VERSION ""

NS_ :

BS_:

BU_: Server VCU Body Brakes

BO_ 2566822142 TCI4: 8 Vector__XXX
 SG_ EngTurbo1TurbineIntakeTemp : 0|16@1+ (0.03125,-273) [-273|1734.97] "deg C" Vector__XXX
 SG_ EngTurbo2TurbineIntakeTemp : 16|16@1+ (0.03125,-273) [-273|1734.97] "deg C" Vector__XXX
 SG_ EngTurbo3TurbineIntakeTemp : 32|16@1+ (0.03125,-273) [-273|1734.97] "deg C" Vector__XXX
 SG_ EngTurbo4TurbineIntakeTemp : 48|16@1+ (0.03125,-273) [-273|1734.97] "deg C" Vector__XXX

BO_ 2566822398 TCI3: 8 Vector__XXX
 SG_ EngTurbo1CompressorIntakePress : 0|16@1+ (0.007812,-250) [-250|251.96] "kPa" Vector__XXX
 SG_ EngTurbo2CompressorIntakePress : 16|16@1+ (0.007812,-250) [-250|251.96] "kPa" Vector__XXX
 SG_ EngTurbo3CompressorIntakePress : 32|16@1+ (0.007812,-250) [-250|251.96] "kPa" Vector__XXX
 SG_ EngTurbo4CompressorIntakePress : 48|16@1+ (0.007812,-250) [-250|251.96] "kPa" Vector__XXX

BO_ 2566822654 TCI2: 8 Vector__XXX
 SG_ EngTurbo1CompressorIntakeTemp : 0|16@1+ (0.03125,-273) [-273|1734.97] "deg C" Vector__XXX
 SG_ EngTurbo2CompressorIntakeTemp : 16|16@1+ (0.03125,-273) [-273|1734.97] "deg C" Vector__XXX
 SG_ EngTurbo3CompressorIntakeTemp : 32|16@1+ (0.03125,-273) [-273|1734.97] "deg C" Vector__XXX
 SG_ EngTurbo4CompressorIntakeTemp : 48|16@1+ (0.03125,-273) [-273|1734.97] "deg C" Vector__XXX

BO_ 2633931774 TCI1: 8 Vector__XXX
 SG_ EngTurboLubeOilPress2 : 0|8@1+ (4,0) [0|1000] "kPa" Vector__XXX
 SG_ EngTurbo2Speed : 8|16@1+ (4,0) [0|257020] "rpm" Vector__XXX
 SG_ EngTurbo3Speed : 24|16@1+ (4,0) [0|257020] "rpm" Vector__XXX
 SG_ EngTurbo4Speed : 40|16@1+ (4,0) [0|257020] "rpm" Vector__XXX

BO_ 2566802430 TCFG2: 8 Vector__XXX
 SG_ TransTorqueLimit : 0|16@1+ (1,0) [0|64255] "Nm" Vector__XXX

BO_ 2566841086 TCFG: 8 Vector__XXX
 SG_ NumberOfReverseGearRatios : 0|8@1+ (1,0) [0|250] "" Vector__XXX
 SG_ NumberOfForwardGearRatios : 8|8@1+ (1,0) [0|250] "" Vector__XXX
 SG_ TransGearRatio : 16|16@1+ (0.001,0) [0|64.255] "" Vector__XXX

BO_ 2348941054 TC1: 8 Vector__XXX
 SG_ TransGearShiftInhibitRq : 0|2@1+ (1,0) [0|3] "" Vector__XXX
 SG_ TrnsTrqeConverterLockupDisableRq : 2|2@1+ (1,0) [0|3] "" Vector__XXX
 SG_ DisengageDrivelineRq : 4|2@1+ (1,0) [0|3] "" Vector__XXX
 SG_ TransReverseGearShiftInhibitRq : 6|2@1+ (1,0) [0|3] "" Vector__XXX
 SG_ RequestedPercentClutchSlip : 8|8@1+ (1,0) [0|100] "%" Vector__XXX
 SG_ TransRequestedGear : 16|8@1+ (1,-125) [-125|125] "" Vector__XXX
 SG_ DisengageDiffLockRqFrontAxle1 : 24|2@1+ (1,0) [0|3] "" Vector__XXX
 SG_ DisengageDiffLockRqFrontAxle2 : 26|2@1+ (1,0) [0|3] "" Vector__XXX
 SG_ DisengageDiffLockRqRearAxle1 : 28|2@1+ (1,0) [0|3] "" Vector__XXX
 SG_ DisengageDiffLockRqRearAxle2 : 30|2@1+ (1,0) [0|3] "" Vector__XXX
 SG_ DisengageDiffLockRqCentral : 32|2@1+ (1,0) [0|3] "" Vector__XXX
 SG_ DisengageDiffLockRqCentralFront : 34|2@1+ (1,0) [0|3] "" Vector__XXX
 SG_ DisengageDiffLockRqCentralRear : 36|2@1+ (1,0) [0|3] "" Vector__XXX
 SG_ TransMode1 : 40|2@1+ (1,0) [0|3] "" Vector__XXX
 SG_ TransMode2 : 42|2@1+ (1,0) [0|3] "" Vector__XXX
 SG_ TransMode3 : 44|2@1+ (1,0) [0|3] "" Vector__XXX
 SG_ TransMode4 : 46|2@1+ (1,0) [0|3] "" Vector__XXX
 SG_ TransRequestedLaunchGear : 50|4@1+ (1,0) [0|15] "" Vector__XXX
 SG_ TrnsShftSlectorDisplayModeSwitch : 54|2@1+ (1,0) [0|3] "" Vector__XXX
 SG_ TransMode5 : 56|2@1+ (1,0) [0|3] "" Vector__XXX
 SG_ TransMode6 : 58|2@1+ (1,0) [0|3] "" Vector__XXX
 SG_ TransMode7 : 60|2@1+ (1,0) [0|3] "" Vector__XXX
 SG_ TransMode8 : 62|2@1+ (1,0) [0|3] "" Vector__XXX

BO_ 2566839806 TC: 8 Vector__XXX
 SG_ EngTurboLubeOilPress1 : 0|8@1+ (4,0) [0|1000] "kPa" Vector__XXX
 SG_ EngTurbo1Speed : 8|16@1+ (4,0) [0|257020] "rpm" Vector__XXX
 SG_ EngTurboOilLevelSwitch : 30|2@1+ (1,0) [0|3] "" Vector__XXX

BO_ 2633911806 TAVG: 8 Vector__XXX
 SG_ EngTotalAverageFuelRate : 0|16@1+ (0.05,0) [0|3212.75] "L/h" Vector__XXX
 SG_ EngTotalAverageFuelEconomy : 16|16@1+ (0.001953,0) [0|125.49] "km/L" Vector__XXX

BO_ 2566775550 SPR: 8 Vector__XXX
 SG_ PneumaticSupplyPressRq : 0|8@1+ (1,0) [0|255] "kPa" Vector__XXX
 SG_ ParkingAnd_orTrailerAirPressRq : 8|8@1+ (1,0) [0|255] "kPa" Vector__XXX
 SG_ ServiceBrakeAirPressRqCircuit1 : 16|8@1+ (1,0) [0|255] "kPa" Vector__XXX
 SG_ ServiceBrakeAirPressRqCircuit2 : 24|8@1+ (1,0) [0|255] "kPa" Vector__XXX
 SG_ AuxEquipmentSupplyPressRq : 32|8@1+ (1,0) [0|255] "kPa" Vector__XXX
 SG_ AirSuspensionSupplyPressRq : 40|8@1+ (1,0) [0|255] "kPa" Vector__XXX

BO_ 2566819838 SP2: 8 Vector__XXX
 SG_ EngExtlShutdownAirSupplyPress : 0|16@1+ (0.5,0) [0|32127.5] "kPa" Vector__XXX

BO_ 2566839038 SOFT: 8 Vector__XXX
 SG_ SoftwareIdentification : 8|8@1+ (1.02,0) [0|255] "per byte" Vector__XXX
 SG_ NmbrOfSftwreIdentificationFields : 0|8@1+ (1,0) [0|250] "steps" Vector__XXX

BO_ 2566841344 SHUTDN: 8 Vector__XXX
 SG_ EngIdleShutdownHasShutdownEng : 0|2@1+ (1,0) [0|3] "" Vector__XXX
 SG_ EngIdleShutdownDriverAlertMode : 2|2@1+ (1,0) [0|3] "" Vector__XXX
 SG_ EngIdleShutdownTimerOverride : 4|2@1+ (1,0) [0|3] "" Vector__XXX
 SG_ EngIdleShutdownTimerState : 6|2@1+ (1,0) [0|3] "" Vector__XXX
 SG_ EngIdleShutdownTimerFunction : 14|2@1+ (1,0) [0|3] "" Vector__XXX
 SG_ A_CHighPressFanSwitch : 16|2@1+ (1,0) [0|3] "" Vector__XXX
 SG_ RefrigerantLowPressSwitch : 18|2@1+ (1,0) [0|3] "" Vector__XXX
 SG_ RefrigerantHighPressSwitch : 20|2@1+ (1,0) [0|3] "" Vector__XXX
 SG_ EngWaitToStartLamp : 24|2@1+ (1,0) [0|3] "" Vector__XXX
 SG_ EngPrtectionSystemHasShutdownEng : 32|2@1+ (1,0) [0|3] "" Vector__XXX
 SG_ EngPrtctnSystmApprachingShutdown : 34|2@1+ (1,0) [0|3] "" Vector__XXX
 SG_ EngProtectionSystemTimerOverride : 36|2@1+ (1,0) [0|3] "" Vector__XXX
 SG_ EngProtectionSystemTimerState : 38|2@1+ (1,0) [0|3] "" Vector__XXX
 SG_ EngProtectionSystemConfig : 46|2@1+ (1,0) [0|3] "" Vector__XXX
 SG_ EngAlarmAcknowledge : 48|2@1+ (1,0) [0|3] "" Vector__XXX
 SG_ EngAlarmOutputCmdStatus : 50|2@1+ (1,0) [0|3] "" Vector__XXX
 SG_ EngAirShutoffCmdStatus : 52|2@1+ (1,0) [0|3] "" Vector__XXX
 SG_ EngOverspeedTest : 54|2@1+ (1,0) [0|3] "" Vector__XXX
 SG_ EngAirShutoffStatus : 56|2@1+ (1,0) [0|3] "" Vector__XXX
 SG_ PTOShutdownHasShutdownEng : 58|2@1+ (1,0) [0|3] "" Vector__XXX
 SG_ CoolantLevEngPrtcShutdnStatus : 60|2@1+ (1,0) [0|3] "bit" Vector__XXX
 SG_ EngOilPressSwitch : 62|2@1+ (1,0) [0|3] "bit" Vector__XXX

BO_ 2633895166 WSMEM: 8 Vector__XXX
 SG_ IdentityNumber : 0|21@1+ (1,0) [0|2097150] "" Vector__XXX
 SG_ ManufacturerCode : 21|11@1+ (1,0) [0|2047] "" Vector__XXX
 SG_ Function : 40|8@1+ (1,0) [0|255] "" Vector__XXX
 SG_ FunctionInstance : 35|5@1+ (1,0) [0|31] "" Vector__XXX
 SG_ ECUInstance : 32|3@1+ (1,0) [0|7] "" Vector__XXX
 SG_ VehicleSystem : 49|7@1+ (1,0) [0|127] "" Vector__XXX
 SG_ VehicleSystemInstance : 56|4@1+ (1,0) [0|15] "" Vector__XXX
 SG_ IndustryGroup : 60|3@1+ (1,0) [0|7] "" Vector__XXX
 SG_ ArbitraryAddressCapable : 63|1@1- (1,0) [0|1] "" Vector__XXX
 SG_ VehicleSystem1 : 49|7@1+ (1,0) [0|127] "" Vector__XXX
 SG_ VehicleSystem2 : 49|7@1+ (1,0) [0|127] "" Vector__XXX
 SG_ VehicleSystem3 : 49|7@1+ (1,0) [0|127] "" Vector__XXX
 SG_ VehicleSystem4 : 49|7@1+ (1,0) [0|127] "" Vector__XXX
 SG_ VehicleSystem5 : 49|7@1+ (1,0) [0|127] "" Vector__XXX

BO_ 2566832382 SERV: 8 Vector__XXX
 SG_ ServiceComponentIdentification : 0|8@1+ (1,0) [0|250] "ID" Vector__XXX
 SG_ ServiceDistance : 8|16@1+ (5,-160635) [-160635|160640] "km" Vector__XXX
 SG_ ServiceComponentIdentification : 24|8@1+ (1,0) [0|250] "ID" Vector__XXX
 SG_ ServiceDelay_CalendarTimeBased : 32|8@1+ (1,-125) [-125|125] "weeks" Vector__XXX
 SG_ ServiceComponentIdentification : 40|8@1+ (1,0) [0|250] "ID" Vector__XXX
 SG_ SrviceDelay_OperationalTimeBased : 48|16@1+ (1,-32127) [-32127|32128] "hr" Vector__XXX

BO_ 2633928446 S2: 8 Vector__XXX
 SG_ ServiceComponentIdentification : 0|8@1+ (1,0) [0|250] "ID" Vector__XXX
 SG_ TimeSinceLastService : 8|16@1+ (1,-32127) [-32127|32128] "hr" Vector__XXX

BO_ 2566804478 RTC1: 8 Vector__XXX
 SG_ LwLmtThrshldFrMaxRPMFromRetarder : 0|8@1+ (1,0) [0|255] "rpm" Vector__XXX
 SG_ HghLmtThrshldFrMnCntnsRPMFrmRtrd : 8|8@1+ (1,0) [0|255] "rpm" Vector__XXX
 SG_ LwLmtThrshldFrMxTrqeFromRetarder : 16|8@1+ (1,-125) [-125|125] "%" Vector__XXX
 SG_ HghLmtThrshldFrMnCntnsTrqFrmRtrd : 24|8@1+ (1,-125) [-125|125] "%" Vector__XXX
 SG_ MaxContinuousRetarderSpeed : 32|8@1+ (1,0) [0|255] "rpm" Vector__XXX
 SG_ MinContinuousRetarderSpeed : 40|8@1+ (1,0) [0|255] "rpm" Vector__XXX
 SG_ MaxContinuousRetarderTorque : 48|8@1+ (1,-125) [-125|125] "%" Vector__XXX
 SG_ MinContinuousRetarderTorque : 56|8@1+ (1,-125) [-125|125] "%" Vector__XXX

BO_ 2566847486 RF: 8 Vector__XXX
 SG_ HydRetarderPress : 0|8@1+ (16,0) [0|4000] "kPa" Vector__XXX
 SG_ HydRetarderOilTemp : 8|8@1+ (1,-40) [-40|210] "deg C" Vector__XXX
 SG_ DrvlineRetarderOverheatIndicator : 16|2@1+ (1,0) [0|3] "" Vector__XXX

BO_ 2631859966 RESET: 8 Vector__XXX
 SG_ TripGroup1 : 0|2@1+ (1,0) [0|3] "" Vector__XXX
 SG_ TripGroup2Proprietary : 2|2@1+ (1,0) [0|3] "" Vector__XXX
 SG_ ServiceComponentIdentification : 8|8@1+ (1,0) [0|250] "ID" Vector__XXX
 SG_ EngBuildHoursReset : 16|2@1+ (1,0) [0|3] "" Vector__XXX
 SG_ SteerStraightAheadPosReset : 18|2@1+ (1,0) [0|3] "" Vector__XXX

BO_ 2633930238 RBI: 8 Vector__XXX
 SG_ EngOperationTimeSinceRebuild : 0|32@1+ (1,0) [0|4211080000] "s" Vector__XXX

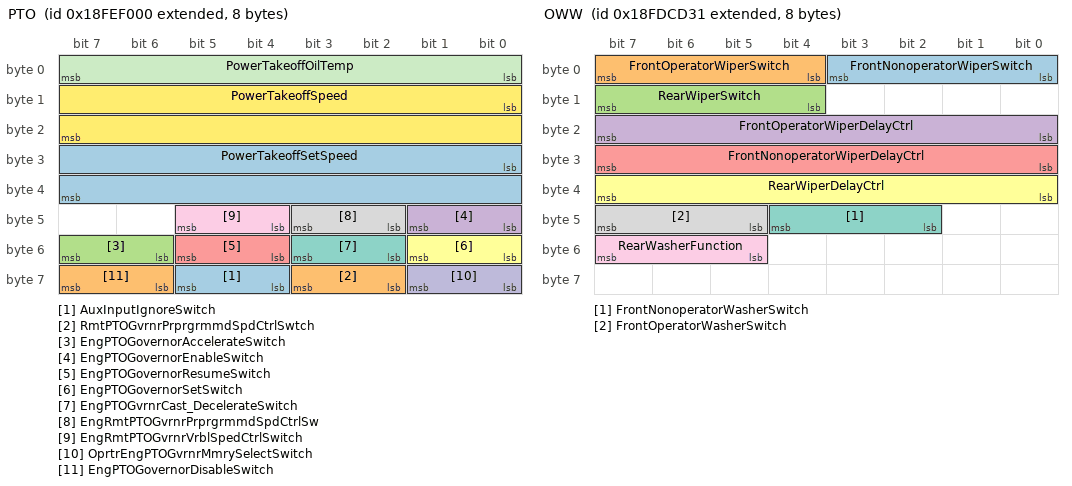
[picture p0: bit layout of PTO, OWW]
BO_ 2566844416 PTO: 8 Vector__XXX
 SG_ AuxInputIgnoreSwitch : 60|2@1+ (1,0) [0|3] "" Vector__XXX
 SG_ RmtPTOGvrnrPrprgrmmdSpdCtrlSwtch : 58|2@1+ (1,0) [0|3] "" Vector__XXX
 SG_ EngPTOGovernorAccelerateSwitch : 54|2@1+ (1,0) [0|3] "" Vector__XXX
 SG_ EngPTOGovernorEnableSwitch : 40|2@1+ (1,0) [0|3] "" Vector__XXX
 SG_ EngPTOGovernorResumeSwitch : 52|2@1+ (1,0) [0|3] "" Vector__XXX
 SG_ EngPTOGovernorSetSwitch : 48|2@1+ (1,0) [0|3] "" Vector__XXX
 SG_ EngPTOGvrnrCast_DecelerateSwitch : 50|2@1+ (1,0) [0|3] "" Vector__XXX
 SG_ EngRmtPTOGvrnrPrprgrmmdSpdCtrlSw : 42|2@1+ (1,0) [0|3] "" Vector__XXX
 SG_ EngRmtPTOGvrnrVrblSpedCtrlSwitch : 44|2@1+ (1,0) [0|3] "" Vector__XXX
 SG_ OprtrEngPTOGvrnrMmrySelectSwitch : 56|2@1+ (1,0) [0|3] "" Vector__XXX
 SG_ PowerTakeoffOilTemp : 0|8@1+ (1,-40) [-40|210] "deg C" Vector__XXX
 SG_ PowerTakeoffSpeed : 8|16@1+ (0.125,0) [0|8031.88] "rpm" Vector__XXX
 SG_ PowerTakeoffSetSpeed : 24|16@1+ (0.125,0) [0|8031.88] "rpm" Vector__XXX
 SG_ EngPTOGovernorDisableSwitch : 62|2@1+ (1,0) [0|3] "" Vector__XXX

BO_ 2566769969 OWW: 8 Vector__XXX
 SG_ FrontNonoperatorWiperSwitch : 0|4@1+ (1,0) [0|15] "" Vector__XXX
 SG_ FrontOperatorWiperSwitch : 4|4@1+ (1,0) [0|15] "" Vector__XXX
 SG_ RearWiperSwitch : 12|4@1+ (1,0) [0|15] "" Vector__XXX
 SG_ FrontOperatorWiperDelayCtrl : 16|8@1+ (0.4,0) [0|100] "%" Vector__XXX
 SG_ FrontNonoperatorWiperDelayCtrl : 24|8@1+ (0.4,0) [0|100] "%" Vector__XXX
 SG_ RearWiperDelayCtrl : 32|8@1+ (0.4,0) [0|100] "%" Vector__XXX
 SG_ FrontNonoperatorWasherSwitch : 42|3@1+ (1,0) [0|7] "" Vector__XXX
 SG_ FrontOperatorWasherSwitch : 45|3@1+ (1,0) [0|7] "" Vector__XXX
 SG_ RearWasherFunction : 53|3@1+ (1,0) [0|7] "" Vector__XXX

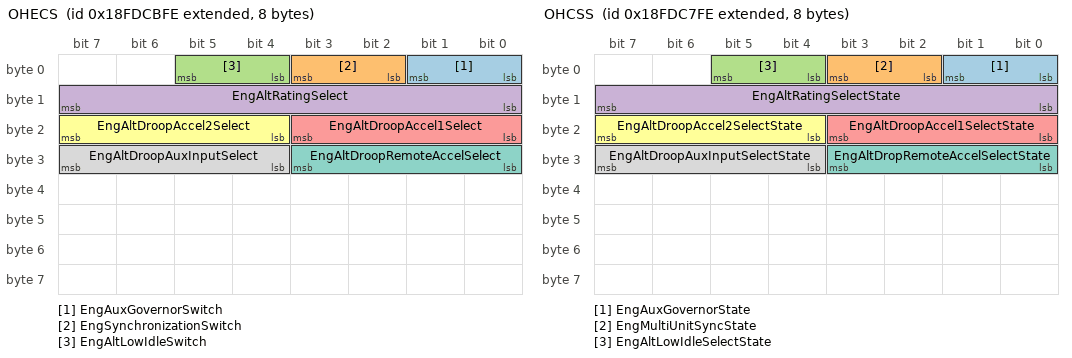
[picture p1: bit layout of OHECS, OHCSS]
BO_ 2566769662 OHECS: 8 Vector__XXX
 SG_ EngAuxGovernorSwitch : 0|2@1+ (1,0) [0|3] "" Vector__XXX
 SG_ EngSynchronizationSwitch : 2|2@1+ (1,0) [0|3] "" Vector__XXX
 SG_ EngAltLowIdleSwitch : 4|2@1+ (1,0) [0|3] "" Vector__XXX
 SG_ EngAltRatingSelect : 8|8@1+ (1.02,0) [0|255] "" Vector__XXX
 SG_ EngAltDroopAccel1Select : 16|4@1+ (1,0) [0|15] "" Vector__XXX
 SG_ EngAltDroopAccel2Select : 20|4@1+ (1,0) [0|15] "" Vector__XXX
 SG_ EngAltDroopRemoteAccelSelect : 24|4@1+ (1,0) [0|15] "" Vector__XXX
 SG_ EngAltDroopAuxInputSelect : 28|4@1+ (1,0) [0|15] "" Vector__XXX

BO_ 2566768638 OHCSS: 8 Vector__XXX
 SG_ EngAuxGovernorState : 0|2@1+ (1,0) [0|3] "" Vector__XXX
 SG_ EngMultiUnitSyncState : 2|2@1+ (1,0) [0|3] "" Vector__XXX
 SG_ EngAltLowIdleSelectState : 4|2@1+ (1,0) [0|3] "" Vector__XXX
 SG_ EngAltRatingSelectState : 8|8@1+ (1,0) [0|255] "" Vector__XXX
 SG_ EngAltDroopAccel1SelectState : 16|4@1+ (1,0) [0|15] "" Vector__XXX
 SG_ EngAltDroopAccel2SelectState : 20|4@1+ (1,0) [0|15] "" Vector__XXX
 SG_ EngAltDropRemoteAccelSelectState : 24|4@1+ (1,0) [0|15] "" Vector__XXX
 SG_ EngAltDroopAuxInputSelectState : 28|4@1+ (1,0) [0|15] "" Vector__XXX

BO_ 2365443326 OEL: 8 Vector__XXX
 SG_ WorkLightSwitch : 0|4@1+ (1,0) [0|15] "" Vector__XXX
 SG_ MainLightSwitch : 4|4@1+ (1,0) [0|15] "" Vector__XXX
 SG_ TurnSignalSwitch : 8|4@1+ (1,0) [0|15] "" Vector__XXX
 SG_ HazardLightSwitch : 12|2@1+ (1,0) [0|3] "" Vector__XXX
 SG_ HighLowBeamSwitch : 14|2@1+ (1,0) [0|3] "" Vector__XXX
 SG_ OperatorsDesiredBacklight : 16|8@1+ (0.4,0) [0|100] "%" Vector__XXX
 SG_ OprtorsDesiredDelayedLampOffTime : 24|16@1+ (1,0) [0|64255] "s" Vector__XXX

BO_ 2566776318 MVS: 8 Vector__XXX
 SG_ MaxVehicleSpeedLimit1 : 0|8@1+ (1,0) [0|250] "km/h" Vector__XXX
 SG_ MaxVehicleSpeedLimit2 : 8|8@1+ (1,0) [0|250] "km/h" Vector__XXX
 SG_ MaxVehicleSpeedLimit3 : 16|8@1+ (1,0) [0|250] "km/h" Vector__XXX
 SG_ MaxVehicleSpeedLimit4 : 24|8@1+ (1,0) [0|250] "km/h" Vector__XXX
 SG_ MaxVehicleSpeedLimit5 : 32|8@1+ (1,0) [0|250] "km/h" Vector__XXX
 SG_ MaxVehicleSpeedLimit6 : 40|8@1+ (1,0) [0|250] "km/h" Vector__XXX
 SG_ MaxVehicleSpeedLimit7 : 48|8@1+ (1,0) [0|250] "km/h" Vector__XXX
 SG_ AppliedVehicleSpeedLimit : 56|8@1+ (1,0) [0|250] "km/h" Vector__XXX

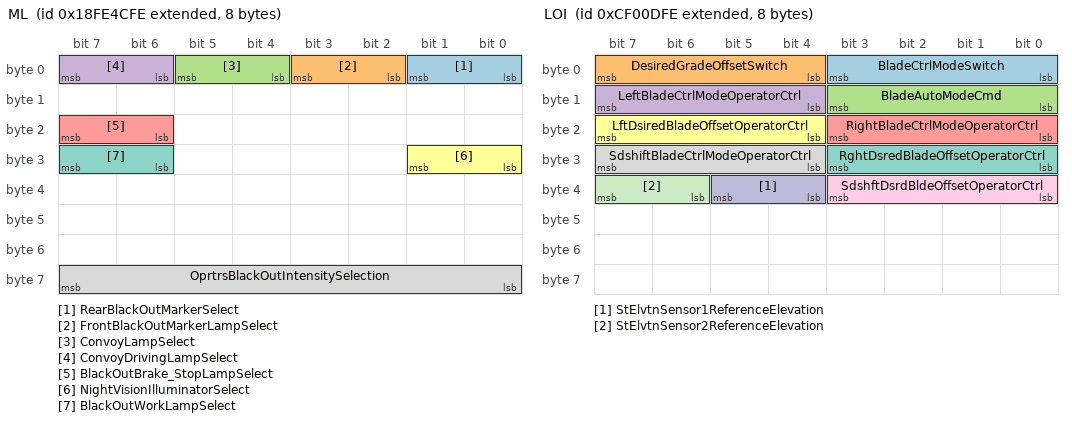
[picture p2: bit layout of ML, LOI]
BO_ 2566802686 ML: 8 Vector__XXX
 SG_ RearBlackOutMarkerSelect : 0|2@1+ (1,0) [0|3] "" Vector__XXX
 SG_ FrontBlackOutMarkerLampSelect : 2|2@1+ (1,0) [0|3] "" Vector__XXX
 SG_ ConvoyLampSelect : 4|2@1+ (1,0) [0|3] "" Vector__XXX
 SG_ ConvoyDrivingLampSelect : 6|2@1+ (1,0) [0|3] "" Vector__XXX
 SG_ BlackOutBrake_StopLampSelect : 22|2@1+ (1,0) [0|3] "" Vector__XXX
 SG_ NightVisionIlluminatorSelect : 24|2@1+ (1,0) [0|3] "" Vector__XXX
 SG_ BlackOutWorkLampSelect : 30|2@1+ (1,0) [0|3] "" Vector__XXX
 SG_ OprtrsBlackOutIntensitySelection : 56|8@1+ (1,0) [0|100] "%" Vector__XXX

BO_ 2566774014 MCI: 8 Vector__XXX
 SG_ EngThrttlSynchrnzationModeStatus : 0|4@1+ (1,0) [0|15] "" Vector__XXX
 SG_ TrollingModeStatus : 4|2@1+ (1,0) [0|3] "" Vector__XXX
 SG_ SlowVesselModeStatus : 6|2@1+ (1,0) [0|3] "" Vector__XXX

BO_ 2566823166 MBT3: 8 Vector__XXX
 SG_ EngMainBearing9Temp : 0|16@1+ (0.03125,-273) [-273|1734.97] "deg C" Vector__XXX
 SG_ EngMainBearing10Temp : 16|16@1+ (0.03125,-273) [-273|1734.97] "deg C" Vector__XXX
 SG_ EngMainBearing11Temp : 32|16@1+ (0.03125,-273) [-273|1734.97] "deg C" Vector__XXX

BO_ 2566823422 MBT2: 8 Vector__XXX
 SG_ EngMainBearing5Temp : 0|16@1+ (0.03125,-273) [-273|1734.97] "deg C" Vector__XXX
 SG_ EngMainBearing6Temp : 16|16@1+ (0.03125,-273) [-273|1734.97] "deg C" Vector__XXX
 SG_ EngMainBearing7Temp : 32|16@1+ (0.03125,-273) [-273|1734.97] "deg C" Vector__XXX
 SG_ EngMainBearing8Temp : 48|16@1+ (0.03125,-273) [-273|1734.97] "deg C" Vector__XXX

BO_ 2566823678 MBT1: 8 Vector__XXX
 SG_ EngMainBearing1Temp : 0|16@1+ (0.03125,-273) [-273|1734.97] "deg C" Vector__XXX
 SG_ EngMainBearing2Temp : 16|16@1+ (0.03125,-273) [-273|1734.97] "deg C" Vector__XXX
 SG_ EngMainBearing3Temp : 32|16@1+ (0.03125,-273) [-273|1734.97] "deg C" Vector__XXX
 SG_ EngMainBearing4Temp : 48|16@1+ (0.03125,-273) [-273|1734.97] "deg C" Vector__XXX

BO_ 2432595710 LVDD: 8 Vector__XXX
 SG_ LEDDisplayData1 : 0|8@1+ (1,0) [0|255] "" Vector__XXX
 SG_ LEDDisplayModeCtrl : 8|4@1+ (1,0) [0|15] "" Vector__XXX
 SG_ LEDDisplayDeadbandCtrl : 12|4@1+ (1,0) [0|15] "" Vector__XXX
 SG_ LEDPatternCtrl : 16|4@1+ (1,0) [0|15] "" Vector__XXX
 SG_ DisplayDeadbands : 20|4@1+ (1,0) [0|15] "" Vector__XXX

BO_ 2365486590 LVD: 8 Vector__XXX
 SG_ AbsLaserStrikePos : 40|16@1+ (0.1,0) [0|6425.5] "mm" Vector__XXX
 SG_ LaserStrikeVerticalDeviation : 0|16@1+ (0.1,-3200) [-3200|3225.5] "mm" Vector__XXX
 SG_ LaserReceiverType : 16|8@1+ (1,0) [0|250] "" Vector__XXX
 SG_ LaserStrikeDataLatency : 24|16@1+ (5.1E-005,0) [0|3.277] "s" Vector__XXX

BO_ 2365485566 LTP: 8 Vector__XXX
 SG_ LaserTracerTargetDeviation : 0|16@1+ (0.1,-3200) [-3200|3225.5] "mm" Vector__XXX
 SG_ LaserTracerVerticalDistance : 16|16@1+ (0.1,0) [0|6425.5] "mm" Vector__XXX
 SG_ LaserTracerHorizontalDeviation : 32|8@1+ (1,0) [0|250] "%" Vector__XXX
 SG_ LEDDisplayData2 : 40|8@1+ (1,0) [0|255] "" Vector__XXX
 SG_ LaserTracerInformation : 48|8@1+ (1,0) [0|255] "" Vector__XXX

BO_ 2365486334 LSP: 8 Vector__XXX
 SG_ ModifyLevelingSystemSetPoint : 0|16@1+ (0.1,-3200) [-3200|3225.5] "mm" Vector__XXX
 SG_ BldeHeightSetPointHighResolution : 16|32@1+ (1,-209.715) [-209.715|4294970000] "m" Vector__XXX

BO_ 2364542462 LOI: 8 Vector__XXX
 SG_ BladeCtrlModeSwitch : 0|4@1+ (1,0) [0|15] "" Vector__XXX
 SG_ DesiredGradeOffsetSwitch : 4|4@1+ (1,0) [0|15] "" Vector__XXX
 SG_ BladeAutoModeCmd : 8|4@1+ (1,0) [0|15] "" Vector__XXX
 SG_ LeftBladeCtrlModeOperatorCtrl : 12|4@1+ (1,0) [0|15] "" Vector__XXX
 SG_ RightBladeCtrlModeOperatorCtrl : 16|4@1+ (1,0) [0|15] "" Vector__XXX
 SG_ LftDsiredBladeOffsetOperatorCtrl : 20|4@1+ (1,0) [0|15] "" Vector__XXX
 SG_ RghtDsredBladeOffsetOperatorCtrl : 24|4@1+ (1,0) [0|15] "" Vector__XXX
 SG_ SdshiftBladeCtrlModeOperatorCtrl : 28|4@1+ (1,0) [0|15] "" Vector__XXX
 SG_ SdshftDsrdBldeOffsetOperatorCtrl : 32|4@1+ (1,0) [0|15] "" Vector__XXX
 SG_ StElvtnSensor1ReferenceElevation : 36|2@1+ (1,0) [0|3] "" Vector__XXX
 SG_ StElvtnSensor2ReferenceElevation : 38|2@1+ (1,0) [0|3] "" Vector__XXX

BO_ 2365486078 LMP: 8 Vector__XXX
 SG_ MastPos : 0|16@1+ (0.1,-3200) [-3200|3225.5] "mm" Vector__XXX

BO_ 2633937918 LFI: 8 Vector__XXX
 SG_ TotalEngPTOGovernorFuelUsed : 0|32@1+ (0.5,0) [0|2105540000] "kg" Vector__XXX
 SG_ TripAverageFuelRate : 32|16@1+ (0.05,0) [0|3212.75] "kg/h" Vector__XXX
 SG_ FlexibleFuelPercentage : 48|10@1+ (1,0) [0|102] "%" Vector__XXX

BO_ 2566844928 LFE: 8 Vector__XXX
 SG_ EngThrottleValve1Pos : 48|8@1+ (0.4,0) [0|100] "%" Vector__XXX
 SG_ EngThrottleValve2Pos : 56|8@1+ (0.4,0) [0|100] "%" Vector__XXX
 SG_ EngFuelRate : 0|16@1+ (0.05,0) [0|3212.75] "L/h" Vector__XXX
 SG_ EngInstantaneousFuelEconomy : 16|16@1+ (0.001953,0) [0|125.49] "km/L" Vector__XXX
 SG_ EngAverageFuelEconomy : 32|16@1+ (0.001953,0) [0|125.49] "km/L"  VCU

BO_ 2566842878 LFC: 8 Vector__XXX
 SG_ EngTripFuel : 0|32@1+ (0.5,0) [0|2105540000] "L" Vector__XXX
 SG_ EngTotalFuelUsed : 32|32@1+ (0.5,0) [0|2105540000] "L" Vector__XXX

BO_ 2633883646 FWD: 8 Vector__XXX
 SG_ FrontWheelDriveActuatorStatus : 0|2@1+ (1,0) [0|3] "" Vector__XXX

BO_ 2633880062 FMS: 8 Vector__XXX
 SG_ FMSstandardDiagnosticsSupported : 0|2@1+ (1,0) [0|3] "" Vector__XXX
 SG_ FMSstandardRequestsSupported : 2|2@1+ (1,0) [0|3] "" Vector__XXX
 SG_ FMSstandardSWversionSupported : 8|32@1+ (1,0) [0|4294970000] "per byte" Vector__XXX

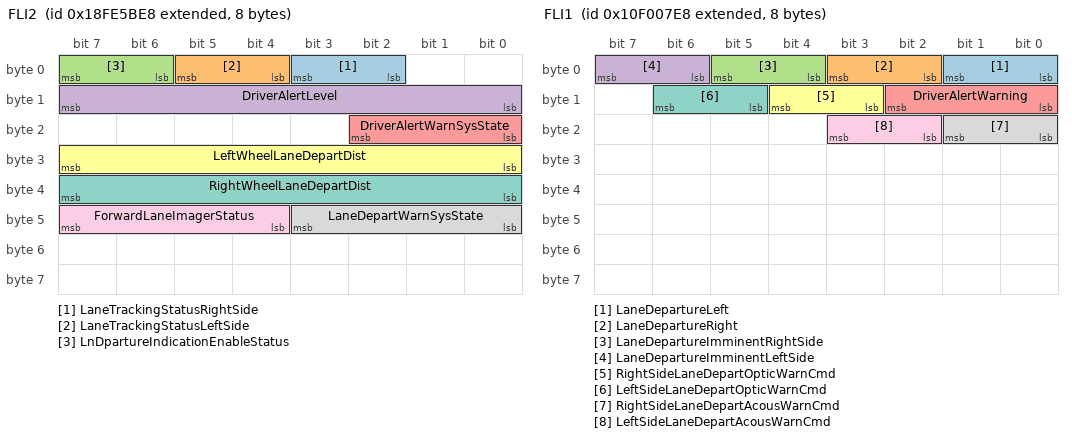
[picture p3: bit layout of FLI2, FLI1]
BO_ 2566806504 FLI2: 8 Vector__XXX
 SG_ LaneTrackingStatusRightSide : 2|2@1+ (1,0) [0|3] "" Vector__XXX
 SG_ LaneTrackingStatusLeftSide : 4|2@1+ (1,0) [0|3] "" Vector__XXX
 SG_ LnDpartureIndicationEnableStatus : 6|2@1+ (1,0) [0|3] "" Vector__XXX
 SG_ DriverAlertLevel : 8|8@1+ (0.4,0) [0|40] "%" Vector__XXX
 SG_ DriverAlertWarnSysState : 16|3@1+ (1,0) [0|7] "bit" Vector__XXX
 SG_ LeftWheelLaneDepartDist : 24|8@1+ (1,-125) [-125|125] "cm" Vector__XXX
 SG_ RightWheelLaneDepartDist : 32|8@1+ (1,-125) [-125|125] "cm" Vector__XXX
 SG_ LaneDepartWarnSysState : 40|4@1+ (1,0) [0|15] "bit" Vector__XXX
 SG_ ForwardLaneImagerStatus : 44|4@1+ (1,0) [0|15] "bit" Vector__XXX

BO_ 2431649768 FLI1: 8 Vector__XXX
 SG_ LaneDepartureLeft : 0|2@1+ (1,0) [0|3] "" Vector__XXX
 SG_ LaneDepartureRight : 2|2@1+ (1,0) [0|3] "" Vector__XXX
 SG_ LaneDepartureImminentRightSide : 4|2@1+ (1,0) [0|3] "" Vector__XXX
 SG_ LaneDepartureImminentLeftSide : 6|2@1+ (1,0) [0|3] "" Vector__XXX
 SG_ DriverAlertWarning : 8|3@1+ (1,0) [0|7] "" Vector__XXX
 SG_ RightSideLaneDepartOpticWarnCmd : 11|2@1+ (1,0) [0|3] "" Vector__XXX
 SG_ LeftSideLaneDepartOpticWarnCmd : 13|2@1+ (1,0) [0|3] "" Vector__XXX
 SG_ RightSideLaneDepartAcousWarnCmd : 16|2@1+ (1,0) [0|3] "" Vector__XXX
 SG_ LeftSideLaneDepartAcousWarnCmd : 18|2@1+ (1,0) [0|3] "" Vector__XXX

BO_ 2633929214 FL: 8 Vector__XXX
 SG_ EngFuelLeakage1 : 0|2@1+ (1,0) [0|3] "" Vector__XXX
 SG_ EngFuelLeakage2 : 2|2@1+ (1,0) [0|3] "" Vector__XXX

BO_ 2566831360 FD1: 8 Vector__XXX
 SG_ EstPercentFanSpeed : 0|8@1+ (1,0) [0|100] "%" Vector__XXX
 SG_ FanDriveState : 8|4@1+ (1,0) [0|15] "" Vector__XXX
 SG_ FanSpeed : 16|16@1+ (0.125,0) [0|8031.88] "rpm" Vector__XXX
 SG_ HydFanMotorPress : 32|16@1+ (0.5,0) [0|32127.5] "kPa" Vector__XXX
 SG_ FanDriveBypassCmdStatus : 48|8@1+ (1,0) [0|100] "%" Vector__XXX

BO_ 2566820094 ETH: 8 Vector__XXX
 SG_ NumberOfEngTorqueHistoryRecords : 0|8@1+ (1,0) [0|250] "records" Vector__XXX
 SG_ EngPower : 8|16@1+ (0.5,0) [0|32127.5] "kW" Vector__XXX
 SG_ EngPeakTorque1 : 24|16@1+ (1,0) [0|64255] "Nm" Vector__XXX
 SG_ EngPeakTorque2 : 40|16@1+ (1,0) [0|64255] "Nm" Vector__XXX
 SG_ CalibRecordStartMonth : 56|8@1+ (1,0) [0|250] "months" Vector__XXX
 SG_ CalibRecordStartDay : 64|8@1+ (0.25,0) [0|62.5] "days" Vector__XXX
 SG_ CalibRecordStartYear : 72|8@1+ (1,1985) [1985|2235] "years" Vector__XXX
 SG_ CalibRecordDurationTime : 80|32@1+ (0.05,0) [0|210554000] "hr" Vector__XXX
 SG_ TorqueLimitingFeatureStatus : 112|2@1+ (1,0) [0|3] "" Vector__XXX
 SG_ EngTorqueLimitFeature : 114|3@1+ (1,0) [0|7] "" Vector__XXX
 SG_ TransGearRatio1 : 120|16@1+ (0.01,0) [0|642.55] "" Vector__XXX
 SG_ EngTorqueLimit1Trans : 136|16@1+ (1,0) [0|64255] "Nm" Vector__XXX
 SG_ TransGearRatio2 : 152|16@1+ (0.01,0) [0|642.55] "" Vector__XXX
 SG_ EngTorqueLimit2Trans : 168|16@1+ (1,0) [0|64255] "Nm" Vector__XXX
 SG_ TransGearRatio3 : 184|16@1+ (0.01,0) [0|642.55] "" Vector__XXX
 SG_ EngTorqueLimit3Trans : 200|16@1+ (1,0) [0|64255] "Nm" Vector__XXX
 SG_ EngTorqueLimit4Trans : 216|16@1+ (1,0) [0|64255] "Nm" Vector__XXX
 SG_ EngTorqueLimit5Switch : 232|16@1+ (1,0) [0|64255] "Nm" Vector__XXX
 SG_ EngTorqueLimit6AxleInput : 248|16@1+ (2,0) [0|128510] "Nm" Vector__XXX

BO_ 2364541955 ETC8: 8 Vector__XXX
 SG_ TransTorqueConverterRatio : 0|16@1+ (0.001,0) [0|64.255] "" Vector__XXX
 SG_ TransClutch_ConverterInputSpeed : 16|16@1+ (0.125,0) [0|8031.88] "rpm" Vector__XXX

BO_ 2566801923 ETC7: 8 Vector__XXX
 SG_ TransServiceIndicator : 2|2@1+ (1,0) [0|3] "" Vector__XXX
 SG_ TrnsRqstedRangeDisplayBlankState : 4|2@1+ (1,0) [0|3] "" Vector__XXX
 SG_ TrnsRqstedRangeDisplayFlashState : 6|2@1+ (1,0) [0|3] "" Vector__XXX
 SG_ TransReadyForBrakeRelease : 8|2@1+ (1,0) [0|3] "" Vector__XXX
 SG_ ActiveShiftConsoleIndicator : 10|2@1+ (1,0) [0|3] "" Vector__XXX
 SG_ TransEngCrankEnable : 12|2@1+ (1,0) [0|3] "" Vector__XXX
 SG_ TransShiftInhibitIndicator : 14|2@1+ (1,0) [0|3] "" Vector__XXX
 SG_ TransMode4Indicator : 16|2@1+ (1,0) [0|3] "" Vector__XXX
 SG_ TransMode3Indicator : 18|2@1+ (1,0) [0|3] "" Vector__XXX
 SG_ TransMode2Indicator : 20|2@1+ (1,0) [0|3] "" Vector__XXX
 SG_ TransMode1Indicator : 22|2@1+ (1,0) [0|3] "" Vector__XXX
 SG_ TransRequestedGearFeedback : 24|8@1+ (1,-125) [-125|125] "" Vector__XXX
 SG_ TransMode5Indicator : 32|2@1+ (1,0) [0|3] "" Vector__XXX
 SG_ TransMode6Indicator : 34|2@1+ (1,0) [0|3] "" Vector__XXX
 SG_ TransMode7Indicator : 36|2@1+ (1,0) [0|3] "" Vector__XXX
 SG_ TransMode8Indicator : 38|2@1+ (1,0) [0|3] "" Vector__XXX
 SG_ TransWarningIndicator : 42|2@1+ (1,0) [0|3] "" Vector__XXX
 SG_ TrnsCrrentRangeDisplayBlankState : 0|2@1+ (1,0) [0|3] "" Vector__XXX
 SG_ TrnsRverseGearShiftInhibitStatus : 40|2@1+ (1,0) [0|3] "" Vector__XXX
 SG_ TransMode9Indicator : 44|2@1+ (1,0) [0|3] "" Vector__XXX
 SG_ TransMode10Indicator : 46|2@1+ (1,0) [0|3] "" Vector__XXX
 SG_ TransAirSupplyPressureIndicator : 48|3@1+ (1,0) [0|7] "" Vector__XXX
 SG_ TransManualReturnState : 51|3@1+ (1,0) [0|7] "" Vector__XXX
 SG_ TransManualModeIndicator : 54|2@1+ (1,0) [0|3] "" Vector__XXX

BO_ 2633935870 ETC6: 8 Vector__XXX
 SG_ RecommendedGear : 0|8@1+ (1,-125) [-125|125] "" Vector__XXX
 SG_ HighestPossibleGear : 8|8@1+ (1,-125) [-125|125] "" Vector__XXX
 SG_ LowestPossibleGear : 16|8@1+ (1,-125) [-125|125] "" Vector__XXX
 SG_ ClutchLifeRemaining : 24|8@1+ (0.4,0) [0|100] "%" Vector__XXX

BO_ 2633942014 ETC5: 8 Vector__XXX
 SG_ TransHighRangeSenseSwitch : 0|2@1+ (1,0) [0|3] "" Vector__XXX
 SG_ TransLowRangeSenseSwitch : 2|2@1+ (1,0) [0|3] "" Vector__XXX
 SG_ TransReverseDirectionSwitch : 8|2@1+ (1,0) [0|3] "" Vector__XXX
 SG_ TransNeutralSwitch : 10|2@1+ (1,0) [0|3] "" Vector__XXX
 SG_ TransForwardDirectionSwitch : 12|2@1+ (1,0) [0|3] "" Vector__XXX

BO_ 2633942526 ETC4: 8 Vector__XXX
 SG_ TransSynchronizerClutchValue : 0|8@1+ (0.4,0) [0|100] "%" Vector__XXX
 SG_ TransSynchronizerBrakeValue : 8|8@1+ (0.4,0) [0|100] "%" Vector__XXX

BO_ 2633943038 ETC3: 8 Vector__XXX
 SG_ TransShiftFingerGearPos : 0|8@1+ (0.4,0) [0|100] "%" Vector__XXX
 SG_ TransShiftFingerRailPos : 8|8@1+ (0.4,0) [0|100] "%" Vector__XXX
 SG_ TransShiftFingerNeutralIndicator : 16|2@1+ (1,0) [0|3] "" Vector__XXX
 SG_ TrnsShftFngerEngagementIndicator : 18|2@1+ (1,0) [0|3] "" Vector__XXX
 SG_ TrnsShftFngerCenterRailIndicator : 20|2@1+ (1,0) [0|3] "" Vector__XXX
 SG_ TransShiftFingerRailActuator1 : 24|2@1+ (1,0) [0|3] "" Vector__XXX
 SG_ TransShiftFingerGearActuator1 : 26|2@1+ (1,0) [0|3] "" Vector__XXX
 SG_ TransShiftFingerRailActuator2 : 28|2@1+ (1,0) [0|3] "" Vector__XXX
 SG_ TransShiftFingerGearActuator2 : 30|2@1+ (1,0) [0|3] "" Vector__XXX
 SG_ TransRangeHighActuator : 32|2@1+ (1,0) [0|3] "" Vector__XXX
 SG_ TransRangeLowActuator : 34|2@1+ (1,0) [0|3] "" Vector__XXX
 SG_ TransSplitterDirectActuator : 36|2@1+ (1,0) [0|3] "" Vector__XXX
 SG_ TransSplitterIndirectActuator : 38|2@1+ (1,0) [0|3] "" Vector__XXX
 SG_ TransClutchActuator : 40|2@1+ (1,0) [0|3] "" Vector__XXX
 SG_ TransLockupClutchActuator : 42|2@1+ (1,0) [0|3] "" Vector__XXX
 SG_ TransDefuelActuator : 44|2@1+ (1,0) [0|3] "" Vector__XXX
 SG_ TransInertiaBrakeActuator : 46|2@1+ (1,0) [0|3] "" Vector__XXX

BO_ 2565866755 ETC2: 8 Vector__XXX
 SG_ TransCurrentGear : 24|8@1+ (1,-125) [-125|125] "" Vector__XXX
 SG_ TransSelectedGear : 0|8@1+ (1,-125) [-125|125] "" Vector__XXX
 SG_ TransActualGearRatio : 8|16@1+ (0.001,0) [0|64.255] "" Vector__XXX
 SG_ TransRequestedRange : 32|16@1+ (1,0) [0|255] "per byte" Vector__XXX
 SG_ TransCurrentRange : 48|16@1+ (1,0) [0|255] "per byte"  VCU

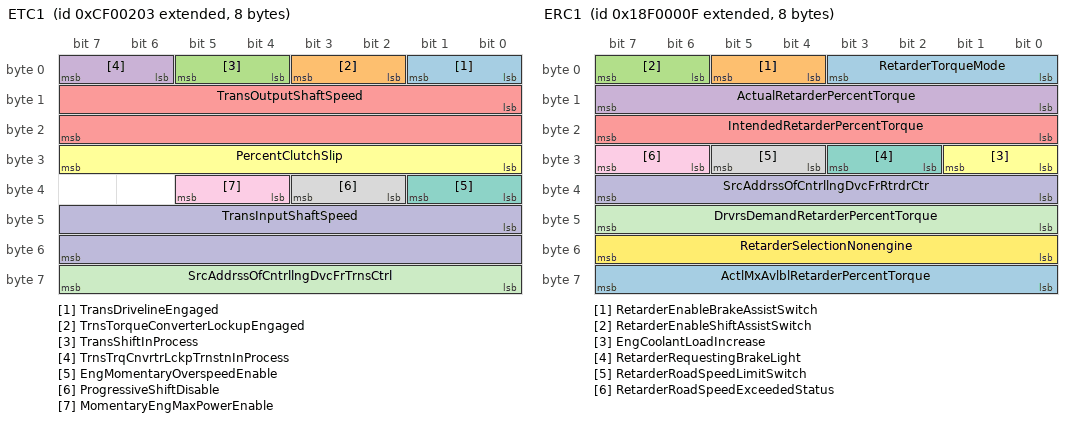
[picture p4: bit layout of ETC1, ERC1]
BO_ 2364539395 ETC1: 8 Vector__XXX
 SG_ TransDrivelineEngaged : 0|2@1+ (1,0) [0|3] "" Vector__XXX
 SG_ TrnsTorqueConverterLockupEngaged : 2|2@1+ (1,0) [0|3] "" Vector__XXX
 SG_ TransShiftInProcess : 4|2@1+ (1,0) [0|3] "" Vector__XXX
 SG_ TrnsTrqCnvrtrLckpTrnstnInProcess : 6|2@1+ (1,0) [0|3] "" Vector__XXX
 SG_ TransOutputShaftSpeed : 8|16@1+ (0.125,0) [0|8031.88] "rpm" Vector__XXX
 SG_ PercentClutchSlip : 24|8@1+ (0.4,0) [0|100] "%" Vector__XXX
 SG_ EngMomentaryOverspeedEnable : 32|2@1+ (1,0) [0|3] "" Vector__XXX
 SG_ ProgressiveShiftDisable : 34|2@1+ (1,0) [0|3] "" Vector__XXX
 SG_ MomentaryEngMaxPowerEnable : 36|2@1+ (1,0) [0|3] "" Vector__XXX
 SG_ TransInputShaftSpeed : 40|16@1+ (0.125,0) [0|8031.88] "rpm" Vector__XXX
 SG_ SrcAddrssOfCntrllngDvcFrTrnsCtrl : 56|8@1+ (1,0) [0|255] ""  VCU

BO_ 2566810110 ET3: 8 Vector__XXX
 SG_ EngCoolantTemp : 16|16@1+ (0.03125,-273) [-273|1734.97] "deg C" Vector__XXX
 SG_ EngIntakeManifold1AirTemp : 0|16@1+ (0.03125,-273) [-273|1734.97] "deg C" Vector__XXX
 SG_ EngIntkVlvActuationSystemOilTemp : 32|16@1+ (0.03125,-273) [-273|1734.97] "deg C" Vector__XXX
 SG_ EngChargeAirCooler1OutletTemp : 48|16@1+ (0.03125,-273) [-273|1734.97] "deg C" Vector__XXX

BO_ 2566825214 ET2: 8 Vector__XXX
 SG_ EngOilTemp2 : 0|16@1+ (0.03125,-273) [-273|1734.97] "deg C" Vector__XXX
 SG_ EngECUTemp : 16|16@1+ (0.03125,-273) [-273|1734.97] "deg C" Vector__XXX
 SG_ EngExhaustGasRecirculation1Temp : 48|16@1+ (0.03125,-273) [-273|1734.97] "deg C" Vector__XXX
 SG_ EngExhstGsRcirculation1DiffPress : 32|16@1+ (0.007812,-250) [-250|251.96] "kPa" Vector__XXX

BO_ 2566843904 ET1: 8 Vector__XXX
 SG_ EngCoolantTemp : 0|8@1+ (1,-40) [-40|210] "deg C" Vector__XXX
 SG_ EngOilTemp1 : 16|16@1+ (0.03125,-273) [-273|1734.97] "deg C" Vector__XXX
 SG_ EngTurboOilTemp : 32|16@1+ (0.03125,-273) [-273|1734.97] "deg C" Vector__XXX
 SG_ EngIntercoolerTemp : 48|8@1+ (1,-40) [-40|210] "deg C" Vector__XXX
 SG_ EngIntercoolerThermostatOpening : 56|8@1+ (0.4,0) [0|100] "%" Vector__XXX
 SG_ EngFuel1Temp1 : 8|8@1+ (1,-40) [-40|210] "deg C"  VCU

BO_ 2566785022 ET: 8 Vector__XXX
 SG_ EngExhaustGasTempRightManifold : 0|16@1+ (0.03125,-273) [-273|1734.97] "deg C" Vector__XXX
 SG_ EngExhaustGasTempLeftManifold : 16|16@1+ (0.03125,-273) [-273|1734.97] "deg C" Vector__XXX

BO_ 2565868542 ESC1: 8 Vector__XXX
 SG_ ActualInnerWheelSteerAngle : 0|16@1+ (0.003891,-125) [-125|125.016] "deg" Vector__XXX
 SG_ AxleLocation : 16|8@1+ (1.02,0) [0|255] "" Vector__XXX
 SG_ StatusOfSteerAxle : 24|4@1+ (1,0) [0|15] "" Vector__XXX
 SG_ SteerableLiftAxleLoweringInhibit : 28|2@1+ (1,0) [0|3] "" Vector__XXX
 SG_ SteerType : 32|4@1+ (1,0) [0|15] "" Vector__XXX
 SG_ TypeOfSteerForces : 36|4@1+ (1,0) [0|15] "" Vector__XXX
 SG_ TypeOfSteerTrans : 40|4@1+ (1,0) [0|15] "" Vector__XXX

BO_ 2633941519 ERC2: 8 Vector__XXX
 SG_ TransOutputRetarder : 0|2@1+ (1,0) [0|3] "" Vector__XXX
 SG_ CruiseCtrlRetdActSpeedOffset : 2|16@1- (1,-125) [-417|168] "km/h" Vector__XXX

BO_ 2565865487 ERC1: 8 Vector__XXX
 SG_ RetarderTorqueMode : 0|4@1+ (1,0) [0|15] "" Vector__XXX
 SG_ RetarderEnableBrakeAssistSwitch : 4|2@1+ (1,0) [0|3] "" Vector__XXX
 SG_ RetarderEnableShiftAssistSwitch : 6|2@1+ (1,0) [0|3] "" Vector__XXX
 SG_ ActualRetarderPercentTorque : 8|8@1+ (1,-125) [-125|125] "%" Vector__XXX
 SG_ IntendedRetarderPercentTorque : 16|8@1+ (1,-125) [-125|125] "%" Vector__XXX
 SG_ EngCoolantLoadIncrease : 24|2@1+ (1,0) [0|3] "" Vector__XXX
 SG_ RetarderRequestingBrakeLight : 26|2@1+ (1,0) [0|3] "" Vector__XXX
 SG_ RetarderRoadSpeedLimitSwitch : 28|2@1+ (1,0) [0|3] "" Vector__XXX
 SG_ RetarderRoadSpeedExceededStatus : 30|2@1+ (1,0) [0|3] "" Vector__XXX
 SG_ SrcAddrssOfCntrllngDvcFrRtrdrCtr : 32|8@1+ (1,0) [0|255] "" Vector__XXX
 SG_ DrvrsDemandRetarderPercentTorque : 40|8@1+ (1,-125) [-125|125] "%" Vector__XXX
 SG_ RetarderSelectionNonengine : 48|8@1+ (0.4,0) [0|100] "%" Vector__XXX
 SG_ ActlMxAvlblRetarderPercentTorque : 56|8@1+ (1,-125) [-125|125] "%"  VCU

BO_ 2633932798 EPT5: 8 Vector__XXX
 SG_ EngExhaustGasPort17Temp : 0|16@1+ (0.03125,-273) [-273|1734.97] "deg C" Vector__XXX
 SG_ EngExhaustGasPort18Temp : 16|16@1+ (0.03125,-273) [-273|1734.97] "deg C" Vector__XXX
 SG_ EngExhaustGasPort19Temp : 32|16@1+ (0.03125,-273) [-273|1734.97] "deg C" Vector__XXX
 SG_ EngExhaustGasPort20Temp : 48|16@1+ (0.03125,-273) [-273|1734.97] "deg C" Vector__XXX

BO_ 2566824190 EPT4: 8 Vector__XXX
 SG_ EngExhaustGasPort13Temp : 0|16@1+ (0.03125,-273) [-273|1734.97] "deg C" Vector__XXX
 SG_ EngExhaustGasPort14Temp : 16|16@1+ (0.03125,-273) [-273|1734.97] "deg C" Vector__XXX
 SG_ EngExhaustGasPort15Temp : 32|16@1+ (0.03125,-273) [-273|1734.97] "deg C" Vector__XXX
 SG_ EngExhaustGasPort16Temp : 48|16@1+ (0.03125,-273) [-273|1734.97] "deg C" Vector__XXX

BO_ 2633933310 EPT3: 8 Vector__XXX
 SG_ EngExhaustGasPort9Temp : 0|16@1+ (0.03125,-273) [-273|1734.97] "deg C" Vector__XXX
 SG_ EngExhaustGasPort10Temp : 16|16@1+ (0.03125,-273) [-273|1734.97] "deg C" Vector__XXX
 SG_ EngExhaustGasPort11Temp : 32|16@1+ (0.03125,-273) [-273|1734.97] "deg C" Vector__XXX
 SG_ EngExhaustGasPort12Temp : 48|16@1+ (0.03125,-273) [-273|1734.97] "deg C" Vector__XXX

BO_ 2633933566 EPT2: 8 Vector__XXX
 SG_ EngExhaustGasPort5Temp : 0|16@1+ (0.03125,-273) [-273|1734.97] "deg C" Vector__XXX
 SG_ EngExhaustGasPort6Temp : 16|16@1+ (0.03125,-273) [-273|1734.97] "deg C" Vector__XXX
 SG_ EngExhaustGasPort7Temp : 32|16@1+ (0.03125,-273) [-273|1734.97] "deg C" Vector__XXX
 SG_ EngExhaustGasPort8Temp : 48|16@1+ (0.03125,-273) [-273|1734.97] "deg C" Vector__XXX

BO_ 2633933822 EPT1: 8 Vector__XXX
 SG_ EngExhaustGasPort1Temp : 0|16@1+ (0.03125,-273) [-273|1734.97] "deg C" Vector__XXX
 SG_ EngExhaustGasPort2Temp : 16|16@1+ (0.03125,-273) [-273|1734.97] "deg C" Vector__XXX
 SG_ EngExhaustGasPort3Temp : 32|16@1+ (0.03125,-273) [-273|1734.97] "deg C" Vector__XXX
 SG_ EngExhaustGasPort4Temp : 48|16@1+ (0.03125,-273) [-273|1734.97] "deg C" Vector__XXX

BO_ 2566776062 EPD: 8 Vector__XXX
 SG_ PayloadPercentage : 0|8@1+ (1,0) [0|250] "%" Vector__XXX

BO_ 2566771454 EP: 8 Vector__XXX
 SG_ KeepAliveBatteryConsumption : 0|16@1+ (1,0) [0|64255] "mAhr" Vector__XXX
 SG_ DataMemoryUsage : 16|8@1+ (0.4,0) [0|100] "%" Vector__XXX

BO_ 2566775806 EOAC: 8 Vector__XXX
 SG_ TravelVelocityCtrlPos : 0|8@1+ (1,-125) [-125|125] "%" Vector__XXX

BO_ 2633935358 EO1: 8 Vector__XXX
 SG_ EngDesiredRatedExhaustOxygen : 0|16@1+ (0.0025,0) [0|160.637] "%" Vector__XXX
 SG_ EngDesiredExhaustOxygen : 16|16@1+ (0.0025,0) [0|160.637] "%" Vector__XXX
 SG_ EngActualExhaustOxygen : 32|16@1+ (0.0025,0) [0|160.637] "%" Vector__XXX
 SG_ EngExhstGsOxygnSnsrFlngCrrection : 48|8@1+ (1,-125) [-125|125] "%" Vector__XXX
 SG_ EngExhstGsOxygnSnsrClsdLpOprtion : 62|2@1+ (1,0) [0|3] "" Vector__XXX

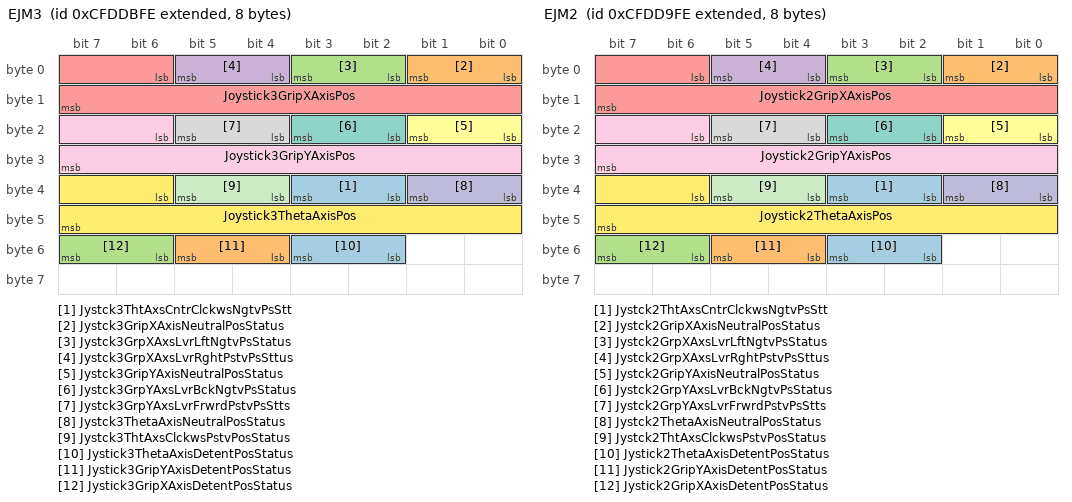
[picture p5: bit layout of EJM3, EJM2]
BO_ 2365447166 EJM3: 8 Vector__XXX
 SG_ Jystck3ThtAxsCntrClckwsNgtvPsStt : 34|2@1+ (1,0) [0|3] "" Vector__XXX
 SG_ Jystck3GripXAxisNeutralPosStatus : 0|2@1+ (1,0) [0|3] "" Vector__XXX
 SG_ Jystck3GrpXAxsLvrLftNgtvPsStatus : 2|2@1+ (1,0) [0|3] "" Vector__XXX
 SG_ Jystck3GrpXAxsLvrRghtPstvPsSttus : 4|2@1+ (1,0) [0|3] "" Vector__XXX
 SG_ Joystick3GripXAxisPos : 6|10@1+ (1,0) [0|102] "%" Vector__XXX
 SG_ Jystck3GripYAxisNeutralPosStatus : 16|2@1+ (1,0) [0|3] "" Vector__XXX
 SG_ Jystck3GrpYAxsLvrBckNgtvPsStatus : 18|2@1+ (1,0) [0|3] "" Vector__XXX
 SG_ Jystck3GrpYAxsLvrFrwrdPstvPsStts : 20|2@1+ (1,0) [0|3] "" Vector__XXX
 SG_ Joystick3GripYAxisPos : 22|10@1+ (1,0) [0|102] "%" Vector__XXX
 SG_ Jystck3ThetaAxisNeutralPosStatus : 32|2@1+ (1,0) [0|3] "" Vector__XXX
 SG_ Jystck3ThtAxsClckwsPstvPosStatus : 36|2@1+ (1,0) [0|3] "" Vector__XXX
 SG_ Joystick3ThetaAxisPos : 38|10@1+ (1,0) [0|102] "%" Vector__XXX
 SG_ Jystick3ThetaAxisDetentPosStatus : 50|2@1+ (1,0) [0|3] "" Vector__XXX
 SG_ Jystick3GripYAxisDetentPosStatus : 52|2@1+ (1,0) [0|3] "" Vector__XXX
 SG_ Jystick3GripXAxisDetentPosStatus : 54|2@1+ (1,0) [0|3] "" Vector__XXX

BO_ 2365446654 EJM2: 8 Vector__XXX
 SG_ Jystck2ThtAxsCntrClckwsNgtvPsStt : 34|2@1+ (1,0) [0|3] "" Vector__XXX
 SG_ Jystck2GripXAxisNeutralPosStatus : 0|2@1+ (1,0) [0|3] "" Vector__XXX
 SG_ Jystck2GrpXAxsLvrLftNgtvPsStatus : 2|2@1+ (1,0) [0|3] "" Vector__XXX
 SG_ Jystck2GrpXAxsLvrRghtPstvPsSttus : 4|2@1+ (1,0) [0|3] "" Vector__XXX
 SG_ Joystick2GripXAxisPos : 6|10@1+ (1,0) [0|102] "%" Vector__XXX
 SG_ Jystck2GripYAxisNeutralPosStatus : 16|2@1+ (1,0) [0|3] "" Vector__XXX
 SG_ Jystck2GrpYAxsLvrBckNgtvPsStatus : 18|2@1+ (1,0) [0|3] "" Vector__XXX
 SG_ Jystck2GrpYAxsLvrFrwrdPstvPsStts : 20|2@1+ (1,0) [0|3] "" Vector__XXX
 SG_ Joystick2GripYAxisPos : 22|10@1+ (1,0) [0|102] "%" Vector__XXX
 SG_ Jystck2ThetaAxisNeutralPosStatus : 32|2@1+ (1,0) [0|3] "" Vector__XXX
 SG_ Jystck2ThtAxsClckwsPstvPosStatus : 36|2@1+ (1,0) [0|3] "" Vector__XXX
 SG_ Joystick2ThetaAxisPos : 38|10@1+ (1,0) [0|102] "%" Vector__XXX
 SG_ Jystick2ThetaAxisDetentPosStatus : 50|2@1+ (1,0) [0|3] "" Vector__XXX
 SG_ Jystick2GripYAxisDetentPosStatus : 52|2@1+ (1,0) [0|3] "" Vector__XXX
 SG_ Jystick2GripXAxisDetentPosStatus : 54|2@1+ (1,0) [0|3] "" Vector__XXX

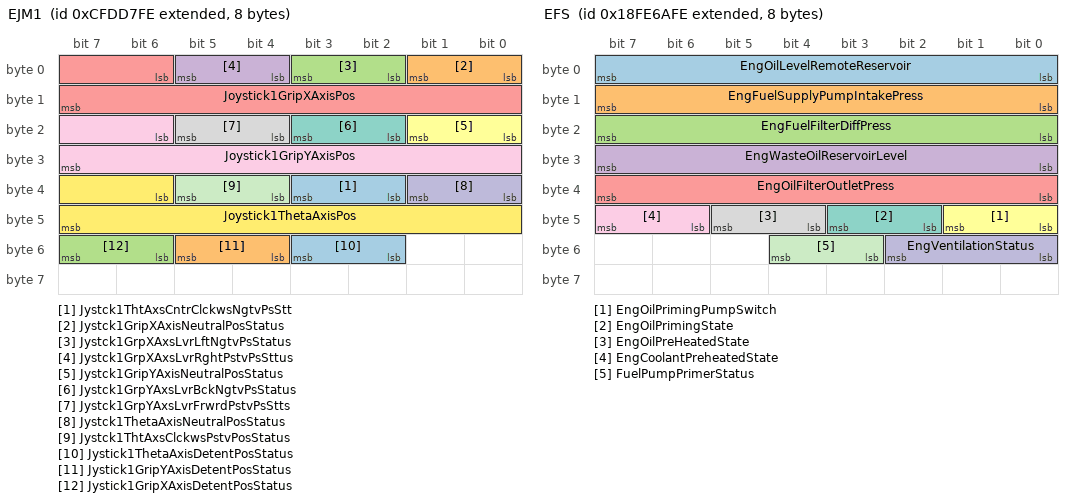
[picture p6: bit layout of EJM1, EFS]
BO_ 2365446142 EJM1: 8 Vector__XXX
 SG_ Jystck1ThtAxsCntrClckwsNgtvPsStt : 34|2@1+ (1,0) [0|3] "" Vector__XXX
 SG_ Jystck1GripXAxisNeutralPosStatus : 0|2@1+ (1,0) [0|3] "" Vector__XXX
 SG_ Jystck1GrpXAxsLvrLftNgtvPsStatus : 2|2@1+ (1,0) [0|3] "" Vector__XXX
 SG_ Jystck1GrpXAxsLvrRghtPstvPsSttus : 4|2@1+ (1,0) [0|3] "" Vector__XXX
 SG_ Joystick1GripXAxisPos : 6|10@1+ (1,0) [0|102] "%" Vector__XXX
 SG_ Jystck1GripYAxisNeutralPosStatus : 16|2@1+ (1,0) [0|3] "" Vector__XXX
 SG_ Jystck1GrpYAxsLvrBckNgtvPsStatus : 18|2@1+ (1,0) [0|3] "" Vector__XXX
 SG_ Jystck1GrpYAxsLvrFrwrdPstvPsStts : 20|2@1+ (1,0) [0|3] "" Vector__XXX
 SG_ Joystick1GripYAxisPos : 22|10@1+ (1,0) [0|102] "%" Vector__XXX
 SG_ Jystck1ThetaAxisNeutralPosStatus : 32|2@1+ (1,0) [0|3] "" Vector__XXX
 SG_ Jystck1ThtAxsClckwsPstvPosStatus : 36|2@1+ (1,0) [0|3] "" Vector__XXX
 SG_ Joystick1ThetaAxisPos : 38|10@1+ (1,0) [0|102] "%" Vector__XXX
 SG_ Jystick1ThetaAxisDetentPosStatus : 50|2@1+ (1,0) [0|3] "" Vector__XXX
 SG_ Jystick1GripYAxisDetentPosStatus : 52|2@1+ (1,0) [0|3] "" Vector__XXX
 SG_ Jystick1GripXAxisDetentPosStatus : 54|2@1+ (1,0) [0|3] "" Vector__XXX

BO_ 2633929470 EI: 8 Vector__XXX
 SG_ EngPrefilterOilPress : 0|8@1+ (4,0) [0|1000] "kPa" Vector__XXX
 SG_ EngExhaustGasPress : 8|16@1+ (0.007812,-250) [-250|251.96] "kPa" Vector__XXX
 SG_ InstantaneousEstBrakePower : 48|16@1+ (0.5,0) [0|32127.5] "kW" Vector__XXX
 SG_ EngGasMassFlowRate1 : 32|16@1+ (0.05,0) [0|3212.75] "kg/h" Vector__XXX
 SG_ EngFuelRackPos : 24|8@1+ (0.4,0) [0|100] "%" Vector__XXX

BO_ 2633937406 EH: 8 Vector__XXX
 SG_ TotalECUDistance : 0|32@1+ (0.125,0) [0|526385000] "km" Vector__XXX
 SG_ TotalECURunTime : 32|32@1+ (0.05,0) [0|210554000] "hr" Vector__XXX

BO_ 2364541440 EGF1: 8 Vector__XXX
 SG_ EngExhstGsRcrcltion1MassFlowRate : 0|16@1+ (0.05,0) [0|3212.75] "kg/h" Vector__XXX
 SG_ EngIntakeAirMassFlowRate : 16|16@1+ (0.05,0) [0|3212.75] "kg/h" Vector__XXX
 SG_ EngExhstGsRcrcltion2MassFlowRate : 32|16@1+ (0.05,0) [0|3212.75] "kg/h" Vector__XXX

BO_ 2566810366 EFS: 8 Vector__XXX
 SG_ EngOilLevelRemoteReservoir : 0|8@1+ (0.4,0) [0|100] "%" Vector__XXX
 SG_ EngFuelSupplyPumpIntakePress : 8|8@1+ (2,0) [0|500] "kPa" Vector__XXX
 SG_ EngFuelFilterDiffPress : 16|8@1+ (2,0) [0|500] "kPa" Vector__XXX
 SG_ EngWasteOilReservoirLevel : 24|8@1+ (0.4,0) [0|100] "%" Vector__XXX
 SG_ EngOilFilterOutletPress : 32|8@1+ (4,0) [0|1000] "kPa" Vector__XXX
 SG_ EngOilPrimingPumpSwitch : 40|2@1+ (1,0) [0|3] "" Vector__XXX
 SG_ EngOilPrimingState : 42|2@1+ (1,0) [0|3] "" Vector__XXX
 SG_ EngOilPreHeatedState : 44|2@1+ (1,0) [0|3] "" Vector__XXX
 SG_ EngCoolantPreheatedState : 46|2@1+ (1,0) [0|3] "" Vector__XXX
 SG_ EngVentilationStatus : 48|3@1+ (1,0) [0|7] "" Vector__XXX
 SG_ FuelPumpPrimerStatus : 51|2@1+ (1,0) [0|3] "" Vector__XXX

BO_ 2566767102 EFL_P3: 8 Vector__XXX
 SG_ EngIntkVlvActationSystemOilPress : 0|16@1+ (0.003906,0) [0|250.98] "MPa" Vector__XXX
 SG_ EngExhstGsRcrclation1IntakePress : 16|8@1+ (2,0) [0|500] "kPa" Vector__XXX
 SG_ EngExhstVlvActtionSystemOilPress : 24|16@1+ (0.003906,0) [0|250.98] "MPa" Vector__XXX
 SG_ EngExhstGsRcrclation1OutletPress : 40|8@1+ (2,0) [0|500] "kPa" Vector__XXX

BO_ 2566839294 EFL_P2: 8 Vector__XXX
 SG_ EngInjectionCtrlPress : 0|16@1+ (0.003906,0) [0|250.98] "MPa" Vector__XXX
 SG_ EngInjectorMeteringRail1Press : 16|16@1+ (0.003906,0) [0|250.98] "MPa" Vector__XXX
 SG_ EngInjectorTimingRail1Press : 32|16@1+ (0.003906,0) [0|250.98] "MPa" Vector__XXX
 SG_ EngInjectorMeteringRail2Press : 48|16@1+ (0.003906,0) [0|250.98] "MPa" Vector__XXX

BO_ 2566844160 EFL_P1: 8 Vector__XXX
 SG_ EngFuelDeliveryPress : 0|8@1+ (4,0) [0|1000] "kPa" Vector__XXX
 SG_ EngExCrankcaseBlowbyPress : 8|8@1+ (0.05,0) [0|12.5] "kPa" Vector__XXX
 SG_ EngOilLevel : 16|8@1+ (0.4,0) [0|100] "%" Vector__XXX
 SG_ EngOilPress : 24|8@1+ (4,0) [0|1000] "kPa" Vector__XXX
 SG_ EngCrankcasePress : 32|16@1+ (0.007812,-250) [-250|251.96] "kPa" Vector__XXX
 SG_ EngCoolantPress : 48|8@1+ (2,0) [0|500] "kPa" Vector__XXX
 SG_ EngCoolantLevel : 56|8@1+ (0.4,0) [0|100] "%" Vector__XXX

BO_ 2633929726 EES: 8 Vector__XXX
 SG_ ElectricalLoad : 0|16@1+ (0.5,0) [0|32127.5] "kW" Vector__XXX
 SG_ SafetyWireStatus : 16|2@1+ (1,0) [0|3] "" Vector__XXX

BO_ 2566772222 EEC5: 8 Vector__XXX
 SG_ EngTrb1ClclatedTurbineOutletTemp : 16|16@1+ (0.03125,-273) [-273|1734.96875] "deg C" Vector__XXX
 SG_ EngVrblGmtryTrbArCtrlShtoffValve : 48|2@1+ (1,0) [0|3] "" Vector__XXX
 SG_ EngVrblGeometryTurbo1ActuatorPos : 56|8@1+ (0.4,0) [0|100] "%" Vector__XXX
 SG_ EngExhstGsRcirculation1ValveCtrl : 32|16@1+ (0.0025,0) [0|160.8375] "%" Vector__XXX
 SG_ EngTrb1ClclatedTurbineIntakeTemp : 0|16@1+ (0.03125,-273) [-273|1734.96875] "deg C" Vector__XXX
 SG_ EngVriableGeometryTurbo1CtrlMode : 52|2@1+ (1,0) [0|3] "" Vector__XXX

BO_ 2633940734 EEC4: 8 Vector__XXX
 SG_ EngRatedPower : 0|16@1+ (0.5,0) [0|32127.5] "kW" Vector__XXX
 SG_ EngRatedSpeed : 16|16@1+ (0.125,0) [0|8031.88] "rpm" Vector__XXX
 SG_ EngRotationDirection : 32|2@1+ (1,0) [0|3] "" Vector__XXX
 SG_ EngIntakeManifoldPressCtrlMode : 34|2@1+ (1,0) [0|3] "" Vector__XXX
 SG_ CrnkAttmptCntOnPrsntStartAttempt : 40|8@1+ (1,0) [0|250] "" Vector__XXX

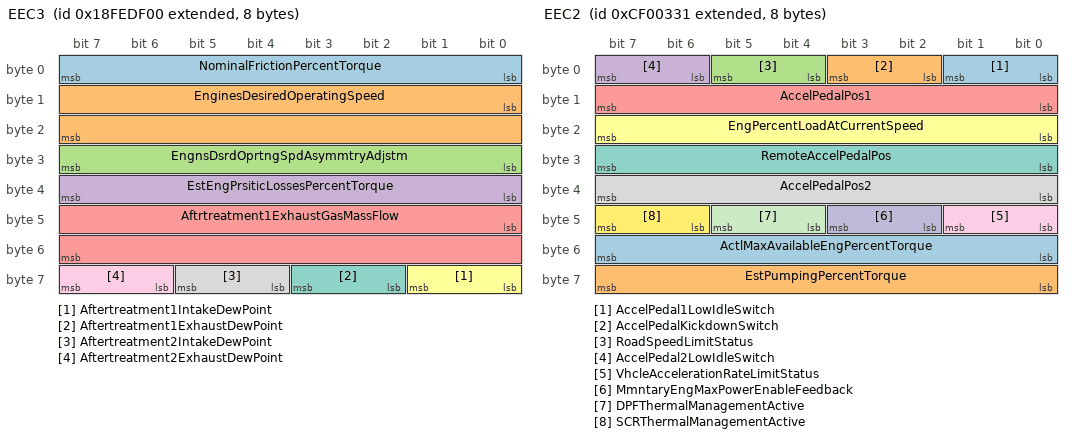
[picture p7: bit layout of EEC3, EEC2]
BO_ 2566840064 EEC3: 8 Vector__XXX
 SG_ NominalFrictionPercentTorque : 0|8@1+ (1,-125) [-125|125] "%" Vector__XXX
 SG_ EnginesDesiredOperatingSpeed : 8|16@1+ (1,0) [0|8032] "rpm" Vector__XXX
 SG_ EngnsDsrdOprtngSpdAsymmtryAdjstm : 24|8@1+ (1,0) [0|250] "" Vector__XXX
 SG_ EstEngPrsiticLossesPercentTorque : 32|8@1+ (1,-125) [-125|125] "%" Vector__XXX
 SG_ Aftrtreatment1ExhaustGasMassFlow : 40|16@1+ (0.2,0) [0|12851] "kg/h per bit" Vector__XXX
 SG_ Aftertreatment1IntakeDewPoint : 56|2@1+ (1,0) [0|3] "" Vector__XXX
 SG_ Aftertreatment1ExhaustDewPoint : 58|2@1+ (1,0) [0|3] "" Vector__XXX
 SG_ Aftertreatment2IntakeDewPoint : 60|2@1+ (1,0) [0|3] "" Vector__XXX
 SG_ Aftertreatment2ExhaustDewPoint : 62|2@1+ (1,0) [0|3] ""  VCU

BO_ 2364539697 EEC2: 8 Vector__XXX
 SG_ AccelPedal1LowIdleSwitch : 0|2@1+ (1,0) [0|3] "" Vector__XXX
 SG_ AccelPedalKickdownSwitch : 2|2@1+ (1,0) [0|3] "" Vector__XXX
 SG_ RoadSpeedLimitStatus : 4|2@1+ (1,0) [0|3] "" Vector__XXX
 SG_ AccelPedal2LowIdleSwitch : 6|2@1+ (1,0) [0|3] "" Vector__XXX
 SG_ AccelPedalPos1 : 8|8@1+ (0.4,0) [0|100] "%" Vector__XXX
 SG_ EngPercentLoadAtCurrentSpeed : 16|8@1+ (1,0) [0|250] "%" Vector__XXX
 SG_ RemoteAccelPedalPos : 24|8@1+ (0.4,0) [0|100] "%" Vector__XXX
 SG_ AccelPedalPos2 : 32|8@1+ (0.4,0) [0|100] "%" Vector__XXX
 SG_ VhcleAccelerationRateLimitStatus : 40|2@1+ (1,0) [0|3] "" Vector__XXX
 SG_ MmntaryEngMaxPowerEnableFeedback : 42|2@1+ (1,0) [0|3] "" Vector__XXX
 SG_ DPFThermalManagementActive : 44|2@1+ (1,0) [0|3] "" Vector__XXX
 SG_ SCRThermalManagementActive : 46|2@1+ (1,0) [0|3] "" Vector__XXX
 SG_ ActlMaxAvailableEngPercentTorque : 48|8@1+ (0.4,0) [0|100] "%" Vector__XXX
 SG_ EstPumpingPercentTorque : 56|8@1+ (1,-125) [-125|125] "%" Vector__XXX

BO_ 2364539904 EEC1: 8 Vector__XXX
 SG_ EngTorqueMode : 0|4@1+ (1,0) [0|15] "" Vector__XXX
 SG_ DriversDemandEngPercentTorque : 8|8@1+ (1,-125) [-125|125] "%" Vector__XXX
 SG_ ActualEngPercentTorque : 16|8@1+ (1,-125) [-125|125] "%" Vector__XXX
 SG_ EngSpeed : 24|16@1+ (0.125,0) [0|8031.88] "rpm" Vector__XXX
 SG_ EngStarterMode : 48|4@1+ (1,0) [0|15] "" Vector__XXX
 SG_ EngDemandPercentTorque : 56|8@1+ (1,-125) [-125|125] "%" Vector__XXX
 SG_ ActlEngPrcntTorqueHighResolution : 4|4@1+ (1,0) [0|1] "%" Vector__XXX
 SG_ SrcAddrssOfCntrllngDvcForEngCtrl : 40|8@1+ (1,0) [0|255] ""  VCU

BO_ 2566768126 ECUID: 8 Vector__XXX
 SG_ ECUPartNumber : 0|8@1+ (1.02,0) [0|255] "per byte" Vector__XXX
 SG_ ECUSerialNumber : 8|8@1+ (1.02,0) [0|255] "per byte" Vector__XXX
 SG_ ECULocation : 16|8@1+ (1.02,0) [0|255] "per byte" Vector__XXX
 SG_ ECUType : 24|8@1+ (1.02,0) [0|255] "per byte" Vector__XXX

BO_ 2566804734 ECT1: 8 Vector__XXX
 SG_ EngLwLmtThrsholdForMaxRPMFromEng : 0|8@1+ (1,0) [0|255] "rpm" Vector__XXX
 SG_ EngHghLmtThrshldFrMnCntnusEngRPM : 8|8@1+ (1,0) [0|255] "rpm" Vector__XXX
 SG_ EngLwLmtThrshldFrMxTorqueFromEng : 16|8@1+ (1,-125) [-125|125] "%" Vector__XXX
 SG_ EngHghLmtThrshldFrMnCntnsTrqFrmE : 24|8@1+ (1,-125) [-125|125] "%" Vector__XXX
 SG_ EngMaxContinuousRPM : 32|8@1+ (1,0) [0|255] "rpm" Vector__XXX
 SG_ EngMinContinuousRPM : 40|8@1+ (1,0) [0|255] "rpm" Vector__XXX
 SG_ EngMaxContinuousTorque : 48|8@1+ (1,-125) [-125|125] "%" Vector__XXX
 SG_ EngMinContinuousTorque : 56|8@1+ (1,-125) [-125|125] "%" Vector__XXX

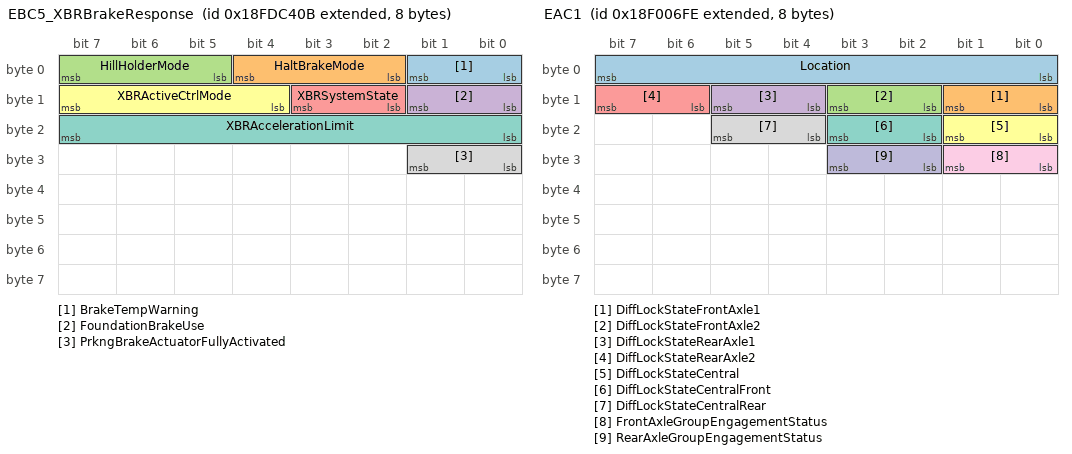
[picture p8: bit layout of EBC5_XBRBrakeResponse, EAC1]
BO_ 2566767627 EBC5_XBRBrakeResponse: 8 Vector__XXX
 SG_ BrakeTempWarning : 0|2@1+ (1,0) [0|3] "" Vector__XXX
 SG_ HaltBrakeMode : 2|3@1+ (1,0) [0|7] "" Vector__XXX
 SG_ HillHolderMode : 5|3@1+ (1,0) [0|7] "" Vector__XXX
 SG_ FoundationBrakeUse : 8|2@1+ (1,0) [0|3] "" Vector__XXX
 SG_ XBRSystemState : 10|2@1+ (1,0) [0|3] "" Vector__XXX
 SG_ XBRActiveCtrlMode : 12|4@1+ (1,0) [0|15] "" Vector__XXX
 SG_ XBRAccelerationLimit : 16|8@1+ (1,-12.5) [-12.5|12.5] "" Vector__XXX
 SG_ PrkngBrakeActuatorFullyActivated : 24|2@1+ (1,0) [0|3] ""  VCU

BO_ 2633936126 EBC4: 8 Vector__XXX
 SG_ BrkLnngRminingFrontAxleLeftWheel : 0|8@1+ (0.4,0) [0|100] "%" Vector__XXX
 SG_ BrkLnngRmningFrontAxleRightWheel : 8|8@1+ (0.4,0) [0|100] "%" Vector__XXX
 SG_ BrkLnngRminingRearAxle1LeftWheel : 16|8@1+ (0.4,0) [0|100] "%" Vector__XXX
 SG_ BrkLnngRmningRearAxle1RightWheel : 24|8@1+ (0.4,0) [0|100] "%" Vector__XXX
 SG_ BrkLnngRminingRearAxle2LeftWheel : 32|8@1+ (0.4,0) [0|100] "%" Vector__XXX
 SG_ BrkLnngRmningRearAxle2RightWheel : 40|8@1+ (0.4,0) [0|100] "%" Vector__XXX
 SG_ BrkLnngRminingRearAxle3LeftWheel : 48|8@1+ (0.4,0) [0|100] "%" Vector__XXX
 SG_ BrkLnngRmningRearAxle3RightWheel : 56|8@1+ (0.4,0) [0|100] "%" Vector__XXX

BO_ 2566827518 EBC3: 8 Vector__XXX
 SG_ BrkAppPrssHghRngRrAxl1RightWheel : 24|8@1+ (5,0) [0|1250] "kPa" Vector__XXX
 SG_ BrkAppPrssHghRngFrntAxlLeftWheel : 0|8@1+ (5,0) [0|1250] "kPa" Vector__XXX
 SG_ BrkAppPrssHghRngFrntAxlRghtWheel : 8|8@1+ (5,0) [0|1250] "kPa" Vector__XXX
 SG_ BrkAppPrssHghRngRrAxle1LeftWheel : 16|8@1+ (5,0) [0|1250] "kPa" Vector__XXX
 SG_ BrkAppPrssHghRngRrAxle2LeftWheel : 32|8@1+ (5,0) [0|1250] "kPa" Vector__XXX
 SG_ BrkAppPrssHghRngRrAxl2RightWheel : 40|8@1+ (5,0) [0|1250] "kPa" Vector__XXX
 SG_ BrkAppPrssHghRngRrAxle3LeftWheel : 48|8@1+ (5,0) [0|1250] "kPa" Vector__XXX
 SG_ BrkAppPrssHghRngRrAxl3RightWheel : 56|8@1+ (5,0) [0|1250] "kPa" Vector__XXX

BO_ 2566831883 EBC2: 8 Vector__XXX
 SG_ FrontAxleSpeed : 0|16@1+ (0.003906,0) [0|250.98] "km/h" Vector__XXX
 SG_ RelativeSpeedFrontAxleLeftWheel : 16|8@1+ (0.0625,-7.8125) [-7.8125|7.8125] "km/h" Vector__XXX
 SG_ RelativeSpeedFrontAxleRightWheel : 24|8@1+ (0.0625,-7.8125) [-7.8125|7.8125] "km/h" Vector__XXX
 SG_ RelativeSpeedRearAxle1LeftWheel : 32|8@1+ (0.0625,-7.8125) [-7.8125|7.8125] "km/h" Vector__XXX
 SG_ RelativeSpeedRearAxle1RightWheel : 40|8@1+ (0.0625,-7.8125) [-7.8125|7.8125] "km/h" Vector__XXX
 SG_ RelativeSpeedRearAxle2LeftWheel : 48|8@1+ (0.0625,-7.8125) [-7.8125|7.8125] "km/h" Vector__XXX
 SG_ RelativeSpeedRearAxle2RightWheel : 56|8@1+ (0.0625,-7.8125) [-7.8125|7.8125] "km/h" Vector__XXX

BO_ 2565865728 EBC1_00: 8 Vector__XXX
 SG_ ASREngCtrlActive : 0|2@1+ (1,0) [0|3] "" Vector__XXX
 SG_ ASRBrakeCtrlActive : 2|2@1+ (1,0) [0|3] "" Vector__XXX
 SG_ AntiLockBrakingActive : 4|2@1+ (1,0) [0|3] "" Vector__XXX
 SG_ EBSBrakeSwitch : 6|2@1+ (1,0) [0|3] "" Vector__XXX
 SG_ BrakePedalPos : 8|8@1+ (0.4,0) [0|100] "%" Vector__XXX
 SG_ ABSOffroadSwitch : 16|2@1+ (1,0) [0|3] "" Vector__XXX
 SG_ ASROffroadSwitch : 18|2@1+ (1,0) [0|3] "" Vector__XXX
 SG_ ASRHillHolderSwitch : 20|2@1+ (1,0) [0|3] "" Vector__XXX
 SG_ TractionCtrlOverrideSwitch : 22|2@1+ (1,0) [0|3] "" Vector__XXX
 SG_ AccelInterlockSwitch : 24|2@1+ (1,0) [0|3] "" Vector__XXX
 SG_ EngDerateSwitch : 26|2@1+ (1,0) [0|3] "" Vector__XXX
 SG_ EngAuxShutdownSwitch : 28|2@1+ (1,0) [0|3] "" Vector__XXX
 SG_ RemoteAccelEnableSwitch : 30|2@1+ (1,0) [0|3] "" Vector__XXX
 SG_ EngRetarderSelection : 32|8@1+ (0.4,0) [0|100] "%" Vector__XXX
 SG_ ABSFullyOperational : 40|2@1+ (1,0) [0|3] "" Vector__XXX
 SG_ EBSRedWarningSignal : 42|2@1+ (1,0) [0|3] "" Vector__XXX
 SG_ ABS_EBSAmberWarningSignal : 44|2@1+ (1,0) [0|3] "" Vector__XXX
 SG_ ATC_ASRInformationSignal : 46|2@1+ (1,0) [0|3] "" Vector__XXX
 SG_ SrcAddrssOfCntrllngDvcFrBrkeCtrl : 48|8@1+ (1,0) [0|255] "" Vector__XXX
 SG_ HaltBrakeSwitch : 58|2@1+ (1,0) [0|3] "" Vector__XXX
 SG_ TrailerABSStatus : 60|2@1+ (1,0) [0|3] "" Vector__XXX
 SG_ TrctrMntdTrailerABSWarningSignal : 62|2@1+ (1,0) [0|3] "" Vector__XXX
 SG_ RailroadModeSwitch : 56|2@1+ (1,0) [0|3] "" Vector__XXX

BO_ 2565867262 EAC1: 8 Vector__XXX
 SG_ Location : 0|8@1+ (1.02,0) [0|255] "" Vector__XXX
 SG_ DiffLockStateFrontAxle1 : 8|2@1+ (1,0) [0|3] "" Vector__XXX
 SG_ DiffLockStateFrontAxle2 : 10|2@1+ (1,0) [0|3] "" Vector__XXX
 SG_ DiffLockStateRearAxle1 : 12|2@1+ (1,0) [0|3] "" Vector__XXX
 SG_ DiffLockStateRearAxle2 : 14|2@1+ (1,0) [0|3] "" Vector__XXX
 SG_ DiffLockStateCentral : 16|2@1+ (1,0) [0|3] "" Vector__XXX
 SG_ DiffLockStateCentralFront : 18|2@1+ (1,0) [0|3] "" Vector__XXX
 SG_ DiffLockStateCentralRear : 20|2@1+ (1,0) [0|3] "" Vector__XXX
 SG_ FrontAxleGroupEngagementStatus : 24|2@1+ (1,0) [0|3] "" Vector__XXX
 SG_ RearAxleGroupEngagementStatus : 26|2@1+ (1,0) [0|3] "" Vector__XXX

BO_ 2566821118 EAC: 8 Vector__XXX
 SG_ EngAuxCoolantPress : 0|8@1+ (4,0) [0|1000] "kPa" Vector__XXX
 SG_ EngAuxCoolantTemp : 8|8@1+ (1,-40) [-40|210] "deg C" Vector__XXX
 SG_ SeaWaterPumpOutletPress : 16|8@1+ (2,0) [0|500] "kPa" Vector__XXX

BO_ 2566810622 DI: 8 Vector__XXX
 SG_ Driver1Identification : 0|8@1+ (1.02,0) [0|255] "per byte" Vector__XXX
 SG_ Driver2Identification : 8|8@1+ (1.02,0) [0|255] "per byte" Vector__XXX

BO_ 2566847537 DD: 8 Vector__XXX
 SG_ WasherFluidLevel : 0|8@1+ (0.4,0) [0|100] "%" Vector__XXX
 SG_ FuelLevel1 : 8|8@1+ (0.4,0) [0|100] "%" Vector__XXX
 SG_ EngFuelFilterDiffPress : 16|8@1+ (2,0) [0|500] "kPa" Vector__XXX
 SG_ EngOilFilterDiffPress : 24|8@1+ (0.5,0) [0|125] "kPa" Vector__XXX
 SG_ CargoAmbientTemp : 32|16@1+ (0.03125,-273) [-273|1734.97] "deg C" Vector__XXX
 SG_ FuelLevel2 : 48|8@1+ (0.4,0) [0|100] "%"  VCU

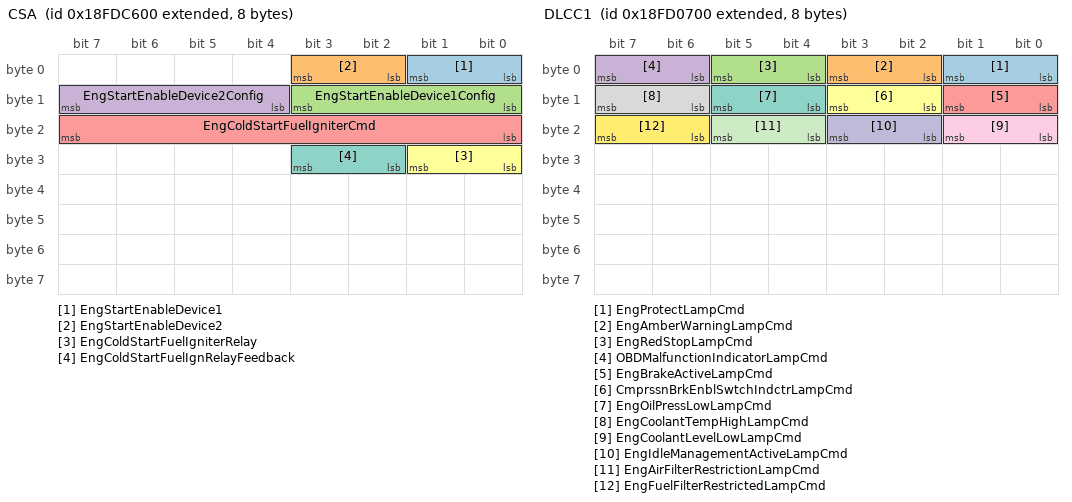
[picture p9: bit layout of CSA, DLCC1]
BO_ 2566768128 CSA: 8 Vector__XXX
 SG_ EngStartEnableDevice1 : 0|2@1+ (1,0) [0|3] "" Vector__XXX
 SG_ EngStartEnableDevice2 : 2|2@1+ (1,0) [0|3] "" Vector__XXX
 SG_ EngStartEnableDevice1Config : 8|4@1+ (1,0) [0|15] "" Vector__XXX
 SG_ EngStartEnableDevice2Config : 12|4@1+ (1,0) [0|15] "" Vector__XXX
 SG_ EngColdStartFuelIgniterCmd : 16|8@1+ (0.4,0) [0|102] "" Vector__XXX
 SG_ EngColdStartFuelIgniterRelay : 24|2@1+ (1,0) [0|3] "" Vector__XXX
 SG_ EngColdStartFuelIgnRelayFeedback : 26|2@1+ (1,0) [0|3] "" Vector__XXX

BO_ 2566811659 CVW: 8 Vector__XXX
 SG_ GrossCombinationVehicleWeight : 16|16@1+ (10,0) [0|642550] "kg" Vector__XXX
 SG_ PoweredVehicleWeight : 0|16@1+ (10,0) [0|642550] "kg"  VCU

BO_ 2563768062 CTL: 8 Vector__XXX
 SG_ EngSpeedLimitRqMinContinuous : 0|8@1+ (1,0) [0|255] "rpm" Vector__XXX
 SG_ EngSpeedLimitRqMaxContinuous : 8|8@1+ (1,0) [0|255] "rpm" Vector__XXX
 SG_ EngTorqueLimitRqMinContinuous : 16|8@1+ (1,-125) [-125|125] "%" Vector__XXX
 SG_ EngTorqueLimitRqMaxContinuous : 24|8@1+ (1,-125) [-125|125] "%" Vector__XXX
 SG_ MnContinuousRetarderSpeedLimitRq : 32|8@1+ (1,0) [0|255] "rpm" Vector__XXX
 SG_ MxContinuousRetarderSpeedLimitRq : 40|8@1+ (1,0) [0|255] "rpm" Vector__XXX
 SG_ MnCntinuousRetarderTorqueLimitRq : 48|8@1+ (1,-125) [-125|125] "%" Vector__XXX
 SG_ MxCntinuousRetarderTorqueLimitRq : 56|8@1+ (1,-125) [-125|125] "%" Vector__XXX

BO_ 2633924862 CT6: 8 Vector__XXX
 SG_ EngDesiredCombustionTime : 0|16@1+ (0.01,0) [0|642.55] "ms" Vector__XXX
 SG_ EngAverageCombustionTime : 16|16@1+ (0.01,0) [0|642.55] "ms" Vector__XXX

BO_ 2633924606 CT5: 8 Vector__XXX
 SG_ EngCyl17CombustionTime : 0|16@1+ (0.01,0) [0|642.55] "ms" Vector__XXX
 SG_ EngCyl18CombustionTime : 16|16@1+ (0.01,0) [0|642.55] "ms" Vector__XXX
 SG_ EngCyl19CombustionTime : 32|16@1+ (0.01,0) [0|642.55] "ms" Vector__XXX
 SG_ EngCyl20CombustionTime : 48|16@1+ (0.01,0) [0|642.55] "ms" Vector__XXX

BO_ 2633924350 CT4: 8 Vector__XXX
 SG_ EngCyl13CombustionTime : 0|16@1+ (0.01,0) [0|642.55] "ms" Vector__XXX
 SG_ EngCyl14CombustionTime : 16|16@1+ (0.01,0) [0|642.55] "ms" Vector__XXX
 SG_ EngCyl15CombustionTime : 32|16@1+ (0.01,0) [0|642.55] "ms" Vector__XXX
 SG_ EngCyl16CombustionTime : 48|16@1+ (0.01,0) [0|642.55] "ms" Vector__XXX

BO_ 2633924094 CT3: 8 Vector__XXX
 SG_ EngCyl9CombustionTime : 0|16@1+ (0.01,0) [0|642.55] "ms" Vector__XXX
 SG_ EngCyl10CombustionTime : 16|16@1+ (0.01,0) [0|642.55] "ms" Vector__XXX
 SG_ EngCyl11CombustionTime : 32|16@1+ (0.01,0) [0|642.55] "ms" Vector__XXX
 SG_ EngCyl12CombustionTime : 48|16@1+ (0.01,0) [0|642.55] "ms" Vector__XXX

BO_ 2633923838 CT2: 8 Vector__XXX
 SG_ EngCyl5CombustionTime : 0|16@1+ (0.01,0) [0|642.55] "ms" Vector__XXX
 SG_ EngCyl6CombustionTime : 16|16@1+ (0.01,0) [0|642.55] "ms" Vector__XXX
 SG_ EngCyl7CombustionTime : 32|16@1+ (0.01,0) [0|642.55] "ms" Vector__XXX
 SG_ EngCyl8CombustionTime : 48|16@1+ (0.01,0) [0|642.55] "ms" Vector__XXX

BO_ 2633923582 CT1: 8 Vector__XXX
 SG_ EngCyl1CombustionTime : 0|16@1+ (0.01,0) [0|642.55] "ms" Vector__XXX
 SG_ EngCyl2CombustionTime : 16|16@1+ (0.01,0) [0|642.55] "ms" Vector__XXX
 SG_ EngCyl3CombustionTime : 32|16@1+ (0.01,0) [0|642.55] "ms" Vector__XXX
 SG_ EngCyl4CombustionTime : 48|16@1+ (0.01,0) [0|642.55] "ms" Vector__XXX

BO_ 2633878014 CMI: 8 Vector__XXX
 SG_ TotalCountOfConfigChangesMade : 0|16@1+ (1,0) [0|64255] "counts" Vector__XXX

BO_ 2566771966 CM3: 8 Vector__XXX
 SG_ TransferCaseSelectorSwitch : 0|3@1+ (1,0) [0|7] "" Vector__XXX
 SG_ FfthWhlRleaseCtrlSecurityLockout : 10|2@1+ (1,0) [0|3] "" Vector__XXX
 SG_ FifthWheelReleaseCtrl : 8|2@1+ (1,0) [0|3] "" Vector__XXX
 SG_ TransOilLevelRq : 16|2@1+ (1,0) [0|3] "" Vector__XXX

BO_ 2564882174 CM1: 8 Vector__XXX
 SG_ RequestedPercentFanSpeed : 0|8@1+ (0.4,0) [0|100] "%" Vector__XXX
 SG_ CabInteriorTempCmd : 8|16@1+ (0.03125,-273) [-273|1734.96875] "deg C" Vector__XXX
 SG_ AuxHeaterCoolantPumpRq : 24|2@1+ (1,0) [0|3] "" Vector__XXX
 SG_ BatteryMainSwitchHoldRq : 26|2@1+ (1,0) [0|3] "" Vector__XXX
 SG_ OperatorSeatDirectionSwitch : 28|2@1+ (1,0) [0|3] "" Vector__XXX
 SG_ SeatBeltSwitch : 30|2@1+ (1,0) [0|3] "" Vector__XXX
 SG_ VhclLmtngSpdGvrnrDecrementSwitch : 34|2@1+ (1,0) [0|3] "" Vector__XXX
 SG_ VhclLmtngSpdGvrnrIncrementSwitch : 36|2@1+ (1,0) [0|3] "" Vector__XXX
 SG_ VhclLmtngSpdGovernorEnableSwitch : 38|2@1+ (1,0) [0|3] "" Vector__XXX
 SG_ DslPrtcltFltrRgnrtnInhibitSwitch : 40|2@1+ (1,0) [0|3] "" Vector__XXX
 SG_ DslPrtcltFltrRgnrtionForceSwitch : 42|2@1+ (1,0) [0|3] "" Vector__XXX
 SG_ AtomaticGearShiftingEnableSwitch : 44|2@1+ (1,0) [0|3] "" Vector__XXX
 SG_ EngAutomaticStartEnableSwitch : 46|2@1+ (1,0) [0|3] "" Vector__XXX
 SG_ AuxHeaterModeRq : 48|4@1+ (1,0) [0|15] "" Vector__XXX
 SG_ RqEngZoneHeating : 52|2@1+ (1,0) [0|3] "" Vector__XXX
 SG_ RqCabZoneHeating : 54|2@1+ (1,0) [0|3] "" Vector__XXX
 SG_ SelectedMaxVehicleSpeedLimit : 56|8@1+ (1,0) [0|250] "" Vector__XXX

BO_ 2563833598 CL: 3 Vector__XXX
 SG_ SwIndicatBrightnessPrct : 16|8@1+ (0.4,0) [0|100] "%" Vector__XXX
 SG_ SwBacklightBrightnessPrct : 8|8@1+ (0.4,0) [0|100] "%" Vector__XXX
 SG_ IlluminationBrightnessPercent : 0|8@1+ (0.4,0) [0|100] "%" Vector__XXX

BO_ 2566843390 CI: 8 Vector__XXX
 SG_ Make : 0|8@1+ (1.02,0) [0|255] "per byte" Vector__XXX
 SG_ Model : 8|8@1+ (1.02,0) [0|255] "per byte" Vector__XXX
 SG_ SerialNumber : 16|8@1+ (1.02,0) [0|255] "per byte" Vector__XXX
 SG_ UnitNumber : 24|8@1+ (1.02,0) [0|255] "per byte" Vector__XXX

BO_ 2566844721 CCVS_B_Cru: 8 Vector__XXX
 SG_ TwoSpeedAxleSwitch : 0|2@1+ (1,0) [0|3] "" Vector__XXX
 SG_ ParkingBrakeSwitch : 2|2@1+ (1,0) [0|3] "" Vector__XXX
 SG_ CruiseCtrlPauseSwitch : 4|2@1+ (1,0) [0|3] "" Vector__XXX
 SG_ ParkBrakeReleaseInhibitRq : 6|2@1+ (1,0) [0|3] "" Vector__XXX
 SG_ WheelBasedVehicleSpeed : 8|16@1+ (0.003906,0) [0|250.98] "km/h" Vector__XXX
 SG_ CruiseCtrlActive : 24|2@1+ (1,0) [0|3] "" Vector__XXX
 SG_ CruiseCtrlEnableSwitch : 26|2@1+ (1,0) [0|3] "" Vector__XXX
 SG_ BrakeSwitch : 28|2@1+ (1,0) [0|3] "" Vector__XXX
 SG_ ClutchSwitch : 30|2@1+ (1,0) [0|3] "" Vector__XXX
 SG_ CruiseCtrlSetSwitch : 32|2@1+ (1,0) [0|3] "" Vector__XXX
 SG_ CruiseCtrlCoastSwitch : 34|2@1+ (1,0) [0|3] "" Vector__XXX
 SG_ CruiseCtrlResumeSwitch : 36|2@1+ (1,0) [0|3] "" Vector__XXX
 SG_ CruiseCtrlAccelerateSwitch : 38|2@1+ (1,0) [0|3] "" Vector__XXX
 SG_ CruiseCtrlSetSpeed : 40|8@1+ (1,0) [0|250] "km/h" Vector__XXX
 SG_ PTOGovernorState : 48|5@1+ (1,0) [0|31] "" Vector__XXX
 SG_ CruiseCtrlStates : 53|3@1+ (1,0) [0|7] "" Vector__XXX
 SG_ EngIdleIncrementSwitch : 56|2@1+ (1,0) [0|3] "" Vector__XXX
 SG_ EngIdleDecrementSwitch : 58|2@1+ (1,0) [0|3] "" Vector__XXX
 SG_ EngTestModeSwitch : 60|2@1+ (1,0) [0|3] "" Vector__XXX
 SG_ EngShutdownOverrideSwitch : 62|2@1+ (1,0) [0|3] ""  VCU

BO_ 2566843648 CCSS: 8 Vector__XXX
 SG_ MaxVehicleSpeedLimit : 0|8@1+ (1,0) [0|250] "km/h" Vector__XXX
 SG_ CruiseCtrlHighSetLimitSpeed : 8|8@1+ (1,0) [0|250] "km/h" Vector__XXX
 SG_ CruiseCtrlLowSetLimitSpeed : 16|8@1+ (1,0) [0|250] "km/h" Vector__XXX

BO_ 2566809598 CCC: 8 Vector__XXX
 SG_ AuxHeaterMaxOutputPower : 0|16@1+ (2,0) [0|128510] "W" Vector__XXX

BO_ 2566775294 CACI: 8 Vector__XXX
 SG_ CbA_CRfrgrntCmpressorOutletPress : 0|8@1+ (16,0) [0|4000] "kPa" Vector__XXX

BO_ 2566803710 BT1: 8 Vector__XXX
 SG_ Battery1Temp : 0|8@1+ (1,-40) [-40|210] "deg C" Vector__XXX
 SG_ Battery2Temp : 8|8@1+ (1,-40) [-40|210] "deg C" Vector__XXX

BO_ 2566719232 DLCC1: 8 Vector__XXX
 SG_ EngProtectLampCmd : 0|2@1+ (1,0) [0|3] "" Vector__XXX
 SG_ EngAmberWarningLampCmd : 2|2@1+ (1,0) [0|3] "" Vector__XXX
 SG_ EngRedStopLampCmd : 4|2@1+ (1,0) [0|3] "" Vector__XXX
 SG_ OBDMalfunctionIndicatorLampCmd : 6|2@1+ (1,0) [0|3] "" Vector__XXX
 SG_ EngBrakeActiveLampCmd : 8|2@1+ (1,0) [0|3] "" Vector__XXX
 SG_ CmprssnBrkEnblSwtchIndctrLampCmd : 10|2@1+ (1,0) [0|3] "" Vector__XXX
 SG_ EngOilPressLowLampCmd : 12|2@1+ (1,0) [0|3] "" Vector__XXX
 SG_ EngCoolantTempHighLampCmd : 14|2@1+ (1,0) [0|3] "" Vector__XXX
 SG_ EngCoolantLevelLowLampCmd : 16|2@1+ (1,0) [0|3] "" Vector__XXX
 SG_ EngIdleManagementActiveLampCmd : 18|2@1+ (1,0) [0|3] "" Vector__XXX
 SG_ EngAirFilterRestrictionLampCmd : 20|2@1+ (1,0) [0|3] "" Vector__XXX
 SG_ EngFuelFilterRestrictedLampCmd : 22|2@1+ (1,0) [0|3] "" Vector__XXX

BO_ 2633832702 CSI: 8 Vector__XXX
 SG_ FrontalCollisionSensor1Type : 0|4@1+ (1,0) [0|15] "" Vector__XXX
 SG_ FrontalCollisionSensor2Type : 4|4@1+ (1,0) [0|15] "" Vector__XXX
 SG_ FrontalCollisionSensor3Type : 8|4@1+ (1,0) [0|15] "" Vector__XXX
 SG_ FrontalCollisionSensor4Type : 12|4@1+ (1,0) [0|15] "" Vector__XXX
 SG_ SideCollisionSensorFrontLeftType : 16|4@1+ (1,0) [0|15] "" Vector__XXX
 SG_ SdCllisionSensorMidFrontLeftType : 20|4@1+ (1,0) [0|15] "" Vector__XXX
 SG_ SdCollisionSensorMidRearLeftType : 24|4@1+ (1,0) [0|15] "" Vector__XXX
 SG_ SideCollisionSensorRearLeftType : 28|4@1+ (1,0) [0|15] "" Vector__XXX
 SG_ SdeCollisionSensorFrontRightType : 32|4@1+ (1,0) [0|15] "" Vector__XXX
 SG_ SdCllsionSensorMidFrontRightType : 36|4@1+ (1,0) [0|15] "" Vector__XXX
 SG_ SdCllisionSensorMidRearRightType : 40|4@1+ (1,0) [0|15] "" Vector__XXX
 SG_ SideCollisionSensorRearRightType : 44|4@1+ (1,0) [0|15] "" Vector__XXX
 SG_ RearCollisionSensor1Type : 48|4@1+ (1,0) [0|15] "" Vector__XXX
 SG_ RearCollisionSensor2Type : 52|4@1+ (1,0) [0|15] "" Vector__XXX
 SG_ RearCollisionSensor3Type : 56|4@1+ (1,0) [0|15] "" Vector__XXX
 SG_ RearCollisionSensor4Type : 60|4@1+ (1,0) [0|15] "" Vector__XXX
 SG_ RolloverSensorType : 64|4@1+ (1,0) [0|15] "" Vector__XXX

BO_ 2163223550 CN: 8 Vector__XXX
 SG_ CrashType : 0|5@1+ (1,0) [0|31] "" Vector__XXX
 SG_ CrashCounter : 56|4@1+ (1,0) [0|15] "" Vector__XXX
 SG_ CrashChecksum : 60|4@1+ (1,0) [0|15] "" Vector__XXX

BO_ 2566714878 CAC2P: 8 Vector__XXX
 SG_ EngChrgArClr2PrecoolerIntakeTemp : 0|16@1+ (0.03125,-273) [-273|1734.97] "deg C" Vector__XXX
 SG_ EngChrgArClr2PrecoolerOutletTemp : 16|16@1+ (0.03125,-273) [-273|1734.97] "deg C" Vector__XXX
 SG_ EngChrgArClr2PrecoolerEfficiency : 32|8@1+ (0.4,0) [0|100] "%" Vector__XXX

BO_ 2566714622 CAC2: 8 Vector__XXX
 SG_ EngChargeAirCooler2IntakeTemp : 0|16@1+ (0.03125,-273) [-273|1734.97] "deg C" Vector__XXX
 SG_ EngChargeAirCooler2OutletTemp : 16|16@1+ (0.03125,-273) [-273|1734.97] "deg C" Vector__XXX
 SG_ EngChrgeAirCooler2AmbientAirTemp : 32|16@1+ (0.03125,-273) [-273|1734.97] "deg C" Vector__XXX
 SG_ EngChargeAirCooler2Efficiency : 48|8@1+ (0.4,0) [0|100] "%" Vector__XXX

BO_ 2566715390 CAC1P: 8 Vector__XXX
 SG_ EngChrgArClr1PrecoolerIntakeTemp : 0|16@1+ (0.03125,-273) [-273|1734.97] "deg C" Vector__XXX
 SG_ EngChrgArClr1PrecoolerOutletTemp : 16|16@1+ (0.03125,-273) [-273|1734.97] "deg C" Vector__XXX
 SG_ EngChrgArClr1PrecoolerEfficiency : 32|8@1+ (0.4,0) [0|100] "%" Vector__XXX

BO_ 2566715134 CAC1: 8 Vector__XXX
 SG_ EngChargeAirCooler1IntakeTemp : 0|16@1+ (0.03125,-273) [-273|1734.97] "deg C" Vector__XXX
 SG_ EngChrgeAirCooler1AmbientAirTemp : 16|16@1+ (0.03125,-273) [-273|1734.97] "deg C" Vector__XXX
 SG_ EngChargeAirCooler1Efficiency : 32|8@1+ (0.4,0) [0|100] "%" Vector__XXX

BO_ 2365400830 BJM9: 8 Vector__XXX
 SG_ Joystick9XAxisNeutralPosStatus : 0|2@1+ (1,0) [0|3] "" Vector__XXX
 SG_ Jystck9XAxsLvrLftNgtivePosStatus : 2|2@1+ (1,0) [0|3] "" Vector__XXX
 SG_ Jystck9XAxsLvrRghtPstvePosStatus : 4|2@1+ (1,0) [0|3] "" Vector__XXX
 SG_ Joystick9XAxisPos : 6|10@1+ (1,0) [0|102] "%" Vector__XXX
 SG_ Joystick9YAxisNeutralPosStatus : 16|2@1+ (1,0) [0|3] "" Vector__XXX
 SG_ Jystck9YAxsLvrBckNgtivePosStatus : 18|2@1+ (1,0) [0|3] "" Vector__XXX
 SG_ Jystck9YAxsLvrFrwrdPstvPosStatus : 20|2@1+ (1,0) [0|3] "" Vector__XXX
 SG_ Joystick9YAxisPos : 22|10@1+ (1,0) [0|102] "%" Vector__XXX
 SG_ Joystick9YAxisDetentPosStatus : 36|2@1+ (1,0) [0|3] "" Vector__XXX
 SG_ Joystick9XAxisDetentPosStatus : 38|2@1+ (1,0) [0|3] "" Vector__XXX
 SG_ Joystick9Button4PressedStatus : 40|2@1+ (1,0) [0|3] "" Vector__XXX
 SG_ Joystick9Button3PressedStatus : 42|2@1+ (1,0) [0|3] "" Vector__XXX
 SG_ Joystick9Button2PressedStatus : 44|2@1+ (1,0) [0|3] "" Vector__XXX
 SG_ Joystick9Button1PressedStatus : 46|2@1+ (1,0) [0|3] "" Vector__XXX
 SG_ Joystick9Button8PressedStatus : 48|2@1+ (1,0) [0|3] "" Vector__XXX
 SG_ Joystick9Button7PressedStatus : 50|2@1+ (1,0) [0|3] "" Vector__XXX
 SG_ Joystick9Button6PressedStatus : 52|2@1+ (1,0) [0|3] "" Vector__XXX
 SG_ Joystick9Button5PressedStatus : 54|2@1+ (1,0) [0|3] "" Vector__XXX
 SG_ Joystick9Button12PressedStatus : 56|2@1+ (1,0) [0|3] "" Vector__XXX
 SG_ Joystick9Button11PressedStatus : 58|2@1+ (1,0) [0|3] "" Vector__XXX
 SG_ Joystick9Button10PressedStatus : 60|2@1+ (1,0) [0|3] "" Vector__XXX
 SG_ Joystick9Button9PressedStatus : 62|2@1+ (1,0) [0|3] "" Vector__XXX

BO_ 2365401342 BJM8: 8 Vector__XXX
 SG_ Joystick8XAxisNeutralPosStatus : 0|2@1+ (1,0) [0|3] "" Vector__XXX
 SG_ Jystck8XAxsLvrLftNgtivePosStatus : 2|2@1+ (1,0) [0|3] "" Vector__XXX
 SG_ Jystck8XAxsLvrRghtPstvePosStatus : 4|2@1+ (1,0) [0|3] "" Vector__XXX
 SG_ Joystick8XAxisPos : 6|10@1+ (1,0) [0|102] "%" Vector__XXX
 SG_ Joystick8YAxisNeutralPosStatus : 16|2@1+ (1,0) [0|3] "" Vector__XXX
 SG_ Jystck8YAxsLvrBckNgtivePosStatus : 18|2@1+ (1,0) [0|3] "" Vector__XXX
 SG_ Jystck8YAxsLvrFrwrdPstvPosStatus : 20|2@1+ (1,0) [0|3] "" Vector__XXX
 SG_ Joystick8YAxisPos : 22|10@1+ (1,0) [0|102] "%" Vector__XXX
 SG_ Joystick8YAxisDetentPosStatus : 36|2@1+ (1,0) [0|3] "" Vector__XXX
 SG_ Joystick8XAxisDetentPosStatus : 38|2@1+ (1,0) [0|3] "" Vector__XXX
 SG_ Joystick8Button4PressedStatus : 40|2@1+ (1,0) [0|3] "" Vector__XXX
 SG_ Joystick8Button3PressedStatus : 42|2@1+ (1,0) [0|3] "" Vector__XXX
 SG_ Joystick8Button2PressedStatus : 44|2@1+ (1,0) [0|3] "" Vector__XXX
 SG_ Joystick8Button1PressedStatus : 46|2@1+ (1,0) [0|3] "" Vector__XXX
 SG_ Joystick8Button8PressedStatus : 48|2@1+ (1,0) [0|3] "" Vector__XXX
 SG_ Joystick8Button7PressedStatus : 50|2@1+ (1,0) [0|3] "" Vector__XXX
 SG_ Joystick8Button6PressedStatus : 52|2@1+ (1,0) [0|3] "" Vector__XXX
 SG_ Joystick8Button5PressedStatus : 54|2@1+ (1,0) [0|3] "" Vector__XXX
 SG_ Joystick8Button12PressedStatus : 56|2@1+ (1,0) [0|3] "" Vector__XXX
 SG_ Joystick8Button11PressedStatus : 58|2@1+ (1,0) [0|3] "" Vector__XXX
 SG_ Joystick8Button10PressedStatus : 60|2@1+ (1,0) [0|3] "" Vector__XXX
 SG_ Joystick8Button9PressedStatus : 62|2@1+ (1,0) [0|3] "" Vector__XXX

BO_ 2365401854 BJM7: 8 Vector__XXX
 SG_ Joystick7XAxisNeutralPosStatus : 0|2@1+ (1,0) [0|3] "" Vector__XXX
 SG_ Jystck7XAxsLvrLftNgtivePosStatus : 2|2@1+ (1,0) [0|3] "" Vector__XXX
 SG_ Jystck7XAxsLvrRghtPstvePosStatus : 4|2@1+ (1,0) [0|3] "" Vector__XXX
 SG_ Joystick7XAxisPos : 6|10@1+ (1,0) [0|102] "%" Vector__XXX
 SG_ Joystick7YAxisNeutralPosStatus : 16|2@1+ (1,0) [0|3] "" Vector__XXX
 SG_ Jystck7YAxsLvrBckNgtivePosStatus : 18|2@1+ (1,0) [0|3] "" Vector__XXX
 SG_ Jystck7YAxsLvrFrwrdPstvPosStatus : 20|2@1+ (1,0) [0|3] "" Vector__XXX
 SG_ Joystick7YAxisPos : 22|10@1+ (1,0) [0|102] "%" Vector__XXX
 SG_ Joystick7YAxisDetentPosStatus : 36|2@1+ (1,0) [0|3] "" Vector__XXX
 SG_ Joystick7XAxisDetentPosStatus : 38|2@1+ (1,0) [0|3] "" Vector__XXX
 SG_ Joystick7Button4PressedStatus : 40|2@1+ (1,0) [0|3] "" Vector__XXX
 SG_ Joystick7Button3PressedStatus : 42|2@1+ (1,0) [0|3] "" Vector__XXX
 SG_ Joystick7Button2PressedStatus : 44|2@1+ (1,0) [0|3] "" Vector__XXX
 SG_ Joystick7Button1PressedStatus : 46|2@1+ (1,0) [0|3] "" Vector__XXX
 SG_ Joystick7Button8PressedStatus : 48|2@1+ (1,0) [0|3] "" Vector__XXX
 SG_ Joystick7Button7PressedStatus : 50|2@1+ (1,0) [0|3] "" Vector__XXX
 SG_ Joystick7Button6PressedStatus : 52|2@1+ (1,0) [0|3] "" Vector__XXX
 SG_ Joystick7Button5PressedStatus : 54|2@1+ (1,0) [0|3] "" Vector__XXX
 SG_ Joystick7Button12PressedStatus : 56|2@1+ (1,0) [0|3] "" Vector__XXX
 SG_ Joystick7Button11PressedStatus : 58|2@1+ (1,0) [0|3] "" Vector__XXX
 SG_ Joystick7Button10PressedStatus : 60|2@1+ (1,0) [0|3] "" Vector__XXX
 SG_ Joystick7Button9PressedStatus : 62|2@1+ (1,0) [0|3] "" Vector__XXX

BO_ 2365402366 BJM6: 8 Vector__XXX
 SG_ Joystick6XAxisNeutralPosStatus : 0|2@1+ (1,0) [0|3] "" Vector__XXX
 SG_ Jystck6XAxsLvrLftNgtivePosStatus : 2|2@1+ (1,0) [0|3] "" Vector__XXX
 SG_ Jystck6XAxsLvrRghtPstvePosStatus : 4|2@1+ (1,0) [0|3] "" Vector__XXX
 SG_ Joystick6XAxisPos : 6|10@1+ (1,0) [0|102] "%" Vector__XXX
 SG_ Joystick6YAxisNeutralPosStatus : 16|2@1+ (1,0) [0|3] "" Vector__XXX
 SG_ Jystck6YAxsLvrBckNgtivePosStatus : 18|2@1+ (1,0) [0|3] "" Vector__XXX
 SG_ Jystck6YAxsLvrFrwrdPstvPosStatus : 20|2@1+ (1,0) [0|3] "" Vector__XXX
 SG_ Joystick6YAxisPos : 22|10@1+ (1,0) [0|102] "%" Vector__XXX
 SG_ Joystick6YAxisDetentPosStatus : 36|2@1+ (1,0) [0|3] "" Vector__XXX
 SG_ Joystick6XAxisDetentPosStatus : 38|2@1+ (1,0) [0|3] "" Vector__XXX
 SG_ Joystick6Button4PressedStatus : 40|2@1+ (1,0) [0|3] "" Vector__XXX
 SG_ Joystick6Button3PressedStatus : 42|2@1+ (1,0) [0|3] "" Vector__XXX
 SG_ Joystick6Button2PressedStatus : 44|2@1+ (1,0) [0|3] "" Vector__XXX
 SG_ Joystick6Button1PressedStatus : 46|2@1+ (1,0) [0|3] "" Vector__XXX
 SG_ Joystick6Button8PressedStatus : 48|2@1+ (1,0) [0|3] "" Vector__XXX
 SG_ Joystick6Button7PressedStatus : 50|2@1+ (1,0) [0|3] "" Vector__XXX
 SG_ Joystick6Button6PressedStatus : 52|2@1+ (1,0) [0|3] "" Vector__XXX
 SG_ Joystick6Button5PressedStatus : 54|2@1+ (1,0) [0|3] "" Vector__XXX
 SG_ Joystick6Button12PressedStatus : 56|2@1+ (1,0) [0|3] "" Vector__XXX
 SG_ Joystick6Button11PressedStatus : 58|2@1+ (1,0) [0|3] "" Vector__XXX
 SG_ Joystick6Button10PressedStatus : 60|2@1+ (1,0) [0|3] "" Vector__XXX
 SG_ Joystick6Button9PressedStatus : 62|2@1+ (1,0) [0|3] "" Vector__XXX

BO_ 2365402878 BJM5: 8 Vector__XXX
 SG_ Joystick5XAxisNeutralPosStatus : 0|2@1+ (1,0) [0|3] "" Vector__XXX
 SG_ Jystck5XAxsLvrLftNgtivePosStatus : 2|2@1+ (1,0) [0|3] "" Vector__XXX
 SG_ Jystck5XAxsLvrRghtPstvePosStatus : 4|2@1+ (1,0) [0|3] "" Vector__XXX
 SG_ Joystick5XAxisPos : 6|10@1+ (1,0) [0|102] "%" Vector__XXX
 SG_ Joystick5YAxisNeutralPosStatus : 16|2@1+ (1,0) [0|3] "" Vector__XXX
 SG_ Jystck5YAxsLvrBckNgtivePosStatus : 18|2@1+ (1,0) [0|3] "" Vector__XXX
 SG_ Jystck5YAxsLvrFrwrdPstvPosStatus : 20|2@1+ (1,0) [0|3] "" Vector__XXX
 SG_ Joystick5YAxisPos : 22|10@1+ (1,0) [0|102] "%" Vector__XXX
 SG_ Joystick5YAxisDetentPosStatus : 36|2@1+ (1,0) [0|3] "" Vector__XXX
 SG_ Joystick5XAxisDetentPosStatus : 38|2@1+ (1,0) [0|3] "" Vector__XXX
 SG_ Joystick5Button4PressedStatus : 40|2@1+ (1,0) [0|3] "" Vector__XXX
 SG_ Joystick5Button3PressedStatus : 42|2@1+ (1,0) [0|3] "" Vector__XXX
 SG_ Joystick5Button2PressedStatus : 44|2@1+ (1,0) [0|3] "" Vector__XXX
 SG_ Joystick5Button1PressedStatus : 46|2@1+ (1,0) [0|3] "" Vector__XXX
 SG_ Joystick5Button8PressedStatus : 48|2@1+ (1,0) [0|3] "" Vector__XXX
 SG_ Joystick5Button7PressedStatus : 50|2@1+ (1,0) [0|3] "" Vector__XXX
 SG_ Joystick5Button6PressedStatus : 52|2@1+ (1,0) [0|3] "" Vector__XXX
 SG_ Joystick5Button5PressedStatus : 54|2@1+ (1,0) [0|3] "" Vector__XXX
 SG_ Joystick5Button12PressedStatus : 56|2@1+ (1,0) [0|3] "" Vector__XXX
 SG_ Joystick5Button11PressedStatus : 58|2@1+ (1,0) [0|3] "" Vector__XXX
 SG_ Joystick5Button10PressedStatus : 60|2@1+ (1,0) [0|3] "" Vector__XXX
 SG_ Joystick5Button9PressedStatus : 62|2@1+ (1,0) [0|3] "" Vector__XXX

BO_ 2365403390 BJM4: 8 Vector__XXX
 SG_ Joystick4XAxisNeutralPosStatus : 0|2@1+ (1,0) [0|3] "" Vector__XXX
 SG_ Jystck4XAxsLvrLftNgtivePosStatus : 2|2@1+ (1,0) [0|3] "" Vector__XXX
 SG_ Jystck4XAxsLvrRghtPstvePosStatus : 4|2@1+ (1,0) [0|3] "" Vector__XXX
 SG_ Joystick4XAxisPos : 6|10@1+ (1,0) [0|102] "%" Vector__XXX
 SG_ Joystick4YAxisNeutralPosStatus : 16|2@1+ (1,0) [0|3] "" Vector__XXX
 SG_ Jystck4YAxsLvrBckNgtivePosStatus : 18|2@1+ (1,0) [0|3] "" Vector__XXX
 SG_ Jystck4YAxsLvrFrwrdPstvPosStatus : 20|2@1+ (1,0) [0|3] "" Vector__XXX
 SG_ Joystick4YAxisPos : 22|10@1+ (1,0) [0|102] "%" Vector__XXX
 SG_ Joystick4YAxisDetentPosStatus : 36|2@1+ (1,0) [0|3] "" Vector__XXX
 SG_ Joystick4XAxisDetentPosStatus : 38|2@1+ (1,0) [0|3] "" Vector__XXX
 SG_ Joystick4Button4PressedStatus : 40|2@1+ (1,0) [0|3] "" Vector__XXX
 SG_ Joystick4Button3PressedStatus : 42|2@1+ (1,0) [0|3] "" Vector__XXX
 SG_ Joystick4Button2PressedStatus : 44|2@1+ (1,0) [0|3] "" Vector__XXX
 SG_ Joystick4Button1PressedStatus : 46|2@1+ (1,0) [0|3] "" Vector__XXX
 SG_ Joystick4Button8PressedStatus : 48|2@1+ (1,0) [0|3] "" Vector__XXX
 SG_ Joystick4Button7PressedStatus : 50|2@1+ (1,0) [0|3] "" Vector__XXX
 SG_ Joystick4Button6PressedStatus : 52|2@1+ (1,0) [0|3] "" Vector__XXX
 SG_ Joystick4Button5PressedStatus : 54|2@1+ (1,0) [0|3] "" Vector__XXX
 SG_ Joystick4Button12PressedStatus : 56|2@1+ (1,0) [0|3] "" Vector__XXX
 SG_ Joystick4Button11PressedStatus : 58|2@1+ (1,0) [0|3] "" Vector__XXX
 SG_ Joystick4Button10PressedStatus : 60|2@1+ (1,0) [0|3] "" Vector__XXX
 SG_ Joystick4Button9PressedStatus : 62|2@1+ (1,0) [0|3] "" Vector__XXX

BO_ 2365400318 BJM10: 8 Vector__XXX
 SG_ Joystick10XAxisNeutralPosStatus : 0|2@1+ (1,0) [0|3] "" Vector__XXX
 SG_ Jystck10XAxsLvrLftNgtvePosStatus : 2|2@1+ (1,0) [0|3] "" Vector__XXX
 SG_ Jystck10XAxsLvrRghtPstvPosStatus : 4|2@1+ (1,0) [0|3] "" Vector__XXX
 SG_ Joystick10XAxisPos : 6|10@1+ (1,0) [0|102] "%" Vector__XXX
 SG_ Joystick10YAxisNeutralPosStatus : 16|2@1+ (1,0) [0|3] "" Vector__XXX
 SG_ Jystck10YAxsLvrBckNgtvePosStatus : 18|2@1+ (1,0) [0|3] "" Vector__XXX
 SG_ Jystck10YAxsLvrFrwrdPstvPsStatus : 20|2@1+ (1,0) [0|3] "" Vector__XXX
 SG_ Joystick10YAxisPos : 22|10@1+ (1,0) [0|102] "%" Vector__XXX
 SG_ Joystick10YAxisDetentPosStatus : 36|2@1+ (1,0) [0|3] "" Vector__XXX
 SG_ Joystick10XAxisDetentPosStatus : 38|2@1+ (1,0) [0|3] "" Vector__XXX
 SG_ Joystick10Button4PressedStatus : 40|2@1+ (1,0) [0|3] "" Vector__XXX
 SG_ Joystick10Button3PressedStatus : 42|2@1+ (1,0) [0|3] "" Vector__XXX
 SG_ Joystick10Button2PressedStatus : 44|2@1+ (1,0) [0|3] "" Vector__XXX
 SG_ Joystick10Button1PressedStatus : 46|2@1+ (1,0) [0|3] "" Vector__XXX
 SG_ Joystick10Button8PressedStatus : 48|2@1+ (1,0) [0|3] "" Vector__XXX
 SG_ Joystick10Button7PressedStatus : 50|2@1+ (1,0) [0|3] "" Vector__XXX
 SG_ Joystick10Button6PressedStatus : 52|2@1+ (1,0) [0|3] "" Vector__XXX
 SG_ Joystick10Button5PressedStatus : 54|2@1+ (1,0) [0|3] "" Vector__XXX
 SG_ Joystick10Button12PressedStatus : 56|2@1+ (1,0) [0|3] "" Vector__XXX
 SG_ Joystick10Button11PressedStatus : 58|2@1+ (1,0) [0|3] "" Vector__XXX
 SG_ Joystick10Button10PressedStatus : 60|2@1+ (1,0) [0|3] "" Vector__XXX
 SG_ Joystick10Button9PressedStatus : 62|2@1+ (1,0) [0|3] "" Vector__XXX

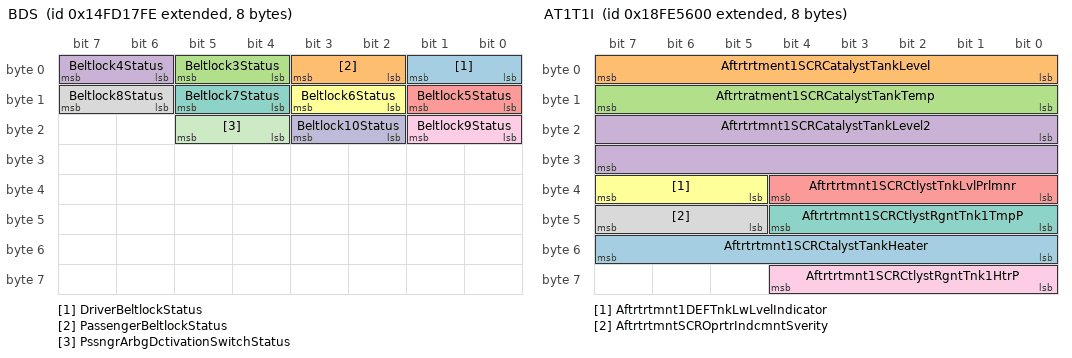
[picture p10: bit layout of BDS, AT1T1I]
BO_ 2499614718 BDS: 8 Vector__XXX
 SG_ DriverBeltlockStatus : 0|2@1+ (1,0) [0|3] "" Vector__XXX
 SG_ PassengerBeltlockStatus : 2|2@1+ (1,0) [0|3] "" Vector__XXX
 SG_ Beltlock3Status : 4|2@1+ (1,0) [0|3] "" Vector__XXX
 SG_ Beltlock4Status : 6|2@1+ (1,0) [0|3] "" Vector__XXX
 SG_ Beltlock5Status : 8|2@1+ (1,0) [0|3] "" Vector__XXX
 SG_ Beltlock6Status : 10|2@1+ (1,0) [0|3] "" Vector__XXX
 SG_ Beltlock7Status : 12|2@1+ (1,0) [0|3] "" Vector__XXX
 SG_ Beltlock8Status : 14|2@1+ (1,0) [0|3] "" Vector__XXX
 SG_ Beltlock9Status : 16|2@1+ (1,0) [0|3] "" Vector__XXX
 SG_ Beltlock10Status : 18|2@1+ (1,0) [0|3] "" Vector__XXX
 SG_ PssngrArbgDctivationSwitchStatus : 20|2@1+ (1,0) [0|3] "" Vector__XXX

BO_ 2566722814 BCH2: 8 Vector__XXX
 SG_ BatteryCharger2State : 0|4@1+ (1,0) [0|15] "" Vector__XXX
 SG_ BatteryCharger2PowerLineState : 4|2@1+ (1,0) [0|3] "" Vector__XXX
 SG_ BatteryCharger2OutputVoltage : 8|16@1+ (0.05,0) [0|3212.75] "V" Vector__XXX
 SG_ BatteryCharger2OutputCurrent : 24|16@1+ (0.05,-1600) [-1600|1612.75] "A" Vector__XXX

BO_ 2566723070 BCH1: 8 Vector__XXX
 SG_ BatteryCharger1State : 0|4@1+ (1,0) [0|15] "" Vector__XXX
 SG_ BatteryCharger1PowerLineState : 4|2@1+ (1,0) [0|3] "" Vector__XXX
 SG_ BatteryCharger1OutputVoltage : 8|16@1+ (0.05,0) [0|3212.75] "V" Vector__XXX
 SG_ BatteryCharger1OutputCurrent : 24|16@1+ (0.05,-1600) [-1600|1612.75] "A" Vector__XXX

BO_ 2566725118 ATDT2: 8 Vector__XXX
 SG_ Aftrtrtmnt1ThrWyCtlystDffGasTemp : 0|16@1+ (0.03125,-273) [-273|1734.97] "deg C" Vector__XXX
 SG_ Aftrtrtmnt2ThrWyCtlystDffGasTemp : 16|16@1+ (0.03125,-273) [-273|1734.97] "deg C" Vector__XXX

BO_ 2566725374 ATDT1: 8 Vector__XXX
 SG_ Aftrtrtmnt1GsOxdtnCtlystDffGsTmp : 0|16@1+ (0.03125,-273) [-273|1734.97] "deg C" Vector__XXX
 SG_ Aftrtrtmnt2GsOxdtnCtlystDffGsTmp : 16|16@1+ (0.03125,-273) [-273|1734.97] "deg C" Vector__XXX

BO_ 2566712830 AT2WUDOC: 8 Vector__XXX
 SG_ Aftrtrtmnt2WrmUpDslOxdtnCtlystIn : 0|16@1+ (0.03125,-273) [-273|1734.97] "deg C" Vector__XXX
 SG_ Aftrtrtmnt2WrmUpDslOxdtnCtlystOt : 16|16@1+ (0.03125,-273) [-273|1734.97] "deg C" Vector__XXX

BO_ 2566735358 AT2TWCC: 8 Vector__XXX
 SG_ Aftrtrtmnt2ThrWyCtlytcCnvrtrIntk : 0|16@1+ (0.03125,-273) [-273|1734.97] "deg C" Vector__XXX
 SG_ Aftrtrtmnt2ThrWyCtlytcCnvrtrOtlt : 16|16@1+ (0.03125,-273) [-273|1734.97] "deg C" Vector__XXX
 SG_ Aftrtrtmnt2ThrWyCtlytcCnvrtrDffP : 32|16@1+ (0.1,0) [0|6425.5] "kPa" Vector__XXX
 SG_ Aftrtrtmnt2ThrWyCtlytcCnvrtrIntk : 48|5@1+ (1,0) [0|31] "" Vector__XXX
 SG_ Aftrtrtmnt2ThrWyCtlytcCnvrtrOtlt : 53|5@1+ (1,0) [0|31] "" Vector__XXX
 SG_ Aftrtrtmnt2ThrWyCtlytcCnvrtrDffP : 58|5@1+ (1,0) [0|31] "" Vector__XXX

BO_ 2365393662 AT2OGC2: 8 Vector__XXX
 SG_ Aftrtrtmnt2OtltGsNOxSnsrCrrctnOf : 0|8@1+ (0.5,0) [0|125] "%/bar" Vector__XXX
 SG_ Aftrtrtmnt2OtltGsNOxSnsrCrrctnOf : 8|8@1+ (0.5,0) [0|125] "%/bar" Vector__XXX
 SG_ Aftrtrtmnt2OtltGsNOxSnsrNO2Crrct : 16|8@1+ (0.5,0) [0|125] "%" Vector__XXX
 SG_ Aftrtrtmnt2OtltGsNOxSnsrNH3Crrct : 24|8@1+ (0.5,0) [0|125] "%" Vector__XXX

BO_ 2365393918 AT2OGC1: 8 Vector__XXX
 SG_ Aftrtrtmnt2OtltGsNOxSnsrHtrRatio : 0|16@1+ (0.001,0) [0|64.255] "" Vector__XXX
 SG_ Aftrtrtmnt2OtltGsNOxSnsrNwPrtDvt : 16|16@1+ (0.003113,-100) [-100|100.026] "%" Vector__XXX
 SG_ Aftrtrtmnt2OtltGsNOxSnsrNwPrtDvt : 32|8@1+ (1,-125) [-125|125] "ppm" Vector__XXX

BO_ 2365394174 AT2IGC2: 8 Vector__XXX
 SG_ Aftrtrtmnt2IntkGsNOxSnsrCrrctnOf : 0|8@1+ (0.5,0) [0|125] "%/bar" Vector__XXX
 SG_ Aftrtrtmnt2IntkGsNOxSnsrCrrctnOf : 8|8@1+ (0.5,0) [0|125] "%/bar" Vector__XXX
 SG_ Aftrtrtmnt2IntkGsNOxSnsrNO2Crrct : 16|8@1+ (0.5,0) [0|125] "%" Vector__XXX
 SG_ Aftrtrtmnt2IntkGsNOxSnsrNH3Crrct : 24|8@1+ (0.5,0) [0|125] "%" Vector__XXX

BO_ 2365394430 AT2IGC1: 8 Vector__XXX
 SG_ Aftrtrtmnt2IntkGsNOxSnsrHtrRatio : 0|16@1+ (0.001,0) [0|64.255] "" Vector__XXX
 SG_ Aftrtrtmnt2IntkGsNOxSnsrNwPrtDvt : 16|16@1+ (0.003113,-100) [-100|100.026] "%" Vector__XXX
 SG_ Aftrtrtmnt2IntkGsNOxSnsrNwPrtDvt : 32|8@1+ (1,-125) [-125|125] "ppm" Vector__XXX

BO_ 2566735102 AT2FC2: 8 Vector__XXX
 SG_ Aftertreatment2FuelPress2 : 0|16@1+ (0.1,0) [0|6425.5] "kPa" Vector__XXX
 SG_ Aftertreatment2FuelPumpRelayCtrl : 16|2@1+ (1,0) [0|3] "" Vector__XXX
 SG_ Aftrtrtmnt2FlFlwDverterValveCtrl : 18|2@1+ (1,0) [0|3] "" Vector__XXX
 SG_ Aftertreatment2FuelPress2Ctrl : 24|16@1+ (1,0) [0|161] "%" Vector__XXX

BO_ 2157313790 AT2DPFSSC: 8 Vector__XXX
 SG_ Aftrtrtmnt2DslPrtcltFltrStMnClbO : 0|16@1+ (1,0) [0|161] "%" Vector__XXX
 SG_ Aftrtrtmnt2DslPrtcltFltrStStndrd : 16|16@1+ (1,0) [0|161] "%" Vector__XXX

BO_ 2566724350 AT1WUDOC: 8 Vector__XXX
 SG_ Aftrtrtmnt1WrmUpDslOxdtnCtlystIn : 0|16@1+ (0.03125,-273) [-273|1734.97] "deg C" Vector__XXX
 SG_ Aftrtrtmnt1WrmUpDslOxdtnCtlystOt : 16|16@1+ (0.03125,-273) [-273|1734.97] "deg C" Vector__XXX

BO_ 2566735614 AT1TWCC: 8 Vector__XXX
 SG_ Aftrtrtmnt1ThrWyCtlytcCnvrtrIntk : 0|16@1+ (0.03125,-273) [-273|1734.97] "deg C" Vector__XXX
 SG_ Aftrtrtmnt1ThrWyCtlytcCnvrtrOtlt : 16|16@1+ (0.03125,-273) [-273|1734.97] "deg C" Vector__XXX
 SG_ Aftrtrtmnt1ThrWyCtlytcCnvrtrDffP : 32|16@1+ (0.1,0) [0|6425.5] "kPa" Vector__XXX
 SG_ Aftrtrtmnt1ThrWyCtlytcCnvrtrIntk : 48|5@1+ (1,0) [0|31] "" Vector__XXX
 SG_ Aftrtrtmnt1ThrWyCtlytcCnvrtrOtlt : 53|5@1+ (1,0) [0|31] "" Vector__XXX
 SG_ Aftrtrtmnt1ThrWyCtlytcCnvrtrDffP : 58|5@1+ (1,0) [0|31] "" Vector__XXX

BO_ 2566804992 AT1T1I: 8 Vector__XXX
 SG_ Aftrtrtmnt1SCRCtalystTankHeater : 48|8@1+ (0.4,0) [0|100] "%" Vector__XXX
 SG_ Aftrtrtment1SCRCatalystTankLevel : 0|8@1+ (0.4,0) [0|100] "%" Vector__XXX
 SG_ Aftrtratment1SCRCatalystTankTemp : 8|8@1+ (1,-40) [-40|210] "deg C" Vector__XXX
 SG_ Aftrtrtmnt1SCRCatalystTankLevel2 : 16|16@1+ (0.1,0) [0|6425.5] "mm" Vector__XXX
 SG_ Aftrtrtmnt1SCRCtlystTnkLvlPrlmnr : 32|5@1+ (1,0) [0|31] "" Vector__XXX
 SG_ Aftrtrtmnt1DEFTnkLwLvelIndicator : 37|3@1+ (1,0) [0|7] "" Vector__XXX
 SG_ Aftrtrtmnt1SCRCtlystRgntTnk1TmpP : 40|5@1+ (1,0) [0|31] "" Vector__XXX
 SG_ AftrtrtmntSCROprtrIndcmntSverity : 45|3@1+ (1,0) [0|7] "" Vector__XXX
 SG_ Aftrtrtmnt1SCRCtlystRgntTnk1HtrP : 56|5@1+ (1,0) [0|31] "" Vector__XXX

BO_ 2365394686 AT1OGC2: 8 Vector__XXX
 SG_ Aftrtrtmnt1OtltGsNOxSnsrCrrctnOf : 0|8@1+ (0.5,0) [0|125] "%/bar" Vector__XXX
 SG_ Aftrtrtmnt1OtltGsNOxSnsrCrrctnOf : 8|8@1+ (0.5,0) [0|125] "%/bar" Vector__XXX
 SG_ Aftrtrtmnt1OtltGsNOxSnsrNO2Crrct : 16|8@1+ (0.5,0) [0|125] "%" Vector__XXX
 SG_ Aftrtrtmnt1OtltGsNOxSnsrNH3Crrct : 24|8@1+ (0.5,0) [0|125] "%" Vector__XXX

BO_ 2365394942 AT1OGC1: 8 Vector__XXX
 SG_ Aftrtrtmnt1OtltGsNOxSnsrHtrRatio : 0|16@1+ (0.001,0) [0|64.255] "" Vector__XXX
 SG_ Aftrtrtmnt1OtltGsNOxSnsrNwPrtDvt : 16|16@1+ (0.003113,-100) [-100|100.026] "%" Vector__XXX
 SG_ Aftrtrtmnt1OtltGsNOxSnsrNwPrtDvt : 32|8@1+ (1,-125) [-125|125] "ppm" Vector__XXX

BO_ 2365395198 AT1IGC2: 8 Vector__XXX
 SG_ Aftrtrtmnt1IntkGsNOxSnsrCrrctnOf : 0|8@1+ (0.5,0) [0|125] "%/bar" Vector__XXX
 SG_ Aftrtrtmnt1IntkGsNOxSnsrCrrctnOf : 8|8@1+ (0.5,0) [0|125] "%/bar" Vector__XXX
 SG_ Aftrtrtmnt1IntkGsNOxSnsrNO2Crrct : 16|8@1+ (0.5,0) [0|125] "%" Vector__XXX
 SG_ Aftrtrtmnt1IntkGsNOxSnsrNH3Crrct : 24|8@1+ (0.5,0) [0|125] "%" Vector__XXX

BO_ 2365395454 AT1IGC1: 8 Vector__XXX
 SG_ Aftrtrtmnt1IntkGsNOxSnsrHtrRatio : 0|16@1+ (0.001,0) [0|64.255] "" Vector__XXX
 SG_ Aftrtrtmnt1IntkGsNOxSnsrNwPrtDvt : 16|16@1+ (0.003113,-100) [-100|100.026] "%" Vector__XXX
 SG_ Aftrtrtmnt1IntkGsNOxSnsrNwPrtDvt : 32|8@1+ (1,-125) [-125|125] "ppm" Vector__XXX

BO_ 2157248254 AT1DPFSSC: 8 Vector__XXX
 SG_ Aftrtrtmnt1DslPrtcltFltrStMnClbO : 0|16@1+ (1,0) [0|161] "%" Vector__XXX
 SG_ Aftrtrtmnt1DslPrtcltFltrStStndrd : 16|16@1+ (1,0) [0|161] "%" Vector__XXX

BO_ 2566711806 ARMSWIMC: 8 Vector__XXX
 SG_ ArmrestSwitchMatrixSwitch1 : 0|2@1+ (1,0) [0|3] "" Vector__XXX
 SG_ ArmrestSwitchMatrixSwitch2 : 2|2@1+ (1,0) [0|3] "" Vector__XXX
 SG_ ArmrestSwitchMatrix2Switch1 : 4|2@1+ (1,0) [0|3] "" Vector__XXX
 SG_ ArmrestSwitchMatrix2Switch2 : 6|2@1+ (1,0) [0|3] "" Vector__XXX

BO_ 2364549886 ARI: 8 Vector__XXX
 SG_ PitchRateExRange : 0|16@1+ (0.007797,-250) [-250|250.996] "deg/sec" Vector__XXX
 SG_ RollRateExRange : 16|16@1+ (0.007797,-250) [-250|250.996] "deg/sec" Vector__XXX
 SG_ YawRateExRange : 32|16@1+ (0.007797,-250) [-250|250.996] "deg/sec" Vector__XXX
 SG_ PitchRateExRangeFigureOfMerit : 48|2@1+ (1,0) [0|3] "" Vector__XXX
 SG_ RollRateExRangeFigureOfMerit : 50|2@1+ (1,0) [0|3] "" Vector__XXX
 SG_ YawRateExRangeFigureOfMerit : 52|2@1+ (1,0) [0|3] "" Vector__XXX
 SG_ AngularRateMeasurementLatency : 56|8@1+ (0.5,0) [0|125] "ms" Vector__XXX

BO_ 2566712318 AFT2NAI: 8 Vector__XXX
 SG_ Aftrtrtmnt2NOxAdsrbrDNOxRgnrtnSt : 0|2@1+ (1,0) [0|3] "" Vector__XXX
 SG_ Aftrtrtmnt2NOxAdsrbrDSOxRgnrtnSt : 2|2@1+ (1,0) [0|3] "" Vector__XXX

BO_ 2566712574 AFT1NAI: 8 Vector__XXX
 SG_ Aftrtrtmnt1NOxAdsrbrDNOxRgnrtnSt : 0|2@1+ (1,0) [0|3] "" Vector__XXX
 SG_ Aftrtrtmnt1NOxAdsrbrDSOxRgnrtnSt : 2|2@1+ (1,0) [0|3] "" Vector__XXX

BO_ 2164078590 A2SCRSI: 8 Vector__XXX
 SG_ Aftrtrtmnt2SCRAvrgCtlystRgntCnsm : 0|16@1+ (0.05,0) [0|3212.75] "L/h" Vector__XXX
 SG_ Aftrtrtmnt2SCRCmmnddCtlystRgntCn : 16|16@1+ (1,0) [0|3213] "L/h" Vector__XXX
 SG_ Aftrtrtmnt2SCRCtlystCnvrsnEffcnc : 32|8@1+ (0.4,0) [0|100] "%" Vector__XXX

BO_ 2566731006 A2SCRRT2I: 8 Vector__XXX
 SG_ Aftrtrtmnt2SCRCtlystRgntTnk2Lvel : 0|8@1+ (0.4,0) [0|100] "%" Vector__XXX
 SG_ Aftrtrtmnt2SCRCtlystRgntTnk2Temp : 8|8@1+ (1,-40) [-40|210] "deg C" Vector__XXX
 SG_ Aftrtrtmnt2SCRCtlystRgntTnk2Lvl2 : 16|16@1+ (1,0) [0|6426] "mm" Vector__XXX
 SG_ Aftrtrtmnt2SCRCtlystRgntTnk2LvlP : 32|5@1+ (1,0) [0|31] "" Vector__XXX
 SG_ Aftrtrtmnt2SCRRgntTnk2TmpPrlmnry : 40|5@1+ (1,0) [0|31] "" Vector__XXX
 SG_ Aftrtrtmnt2SCRCtlystRgntTnk2Hter : 48|4@1+ (1,0) [0|15] "" Vector__XXX
 SG_ Aftrtrtmnt2SCRCtlystRgntTnk2HtrP : 56|5@1+ (1,0) [0|31] "" Vector__XXX

BO_ 2566731262 A2SCRRT1I: 8 Vector__XXX
 SG_ Aftrtrtment2SCRCatalystTankLevel : 0|8@1+ (0.4,0) [0|100] "%" Vector__XXX
 SG_ Aftrtratment2SCRCatalystTankTemp : 8|8@1+ (1,-40) [-40|210] "deg C" Vector__XXX
 SG_ Aftrtrtmnt2SCRCatalystTankLevel2 : 16|16@1+ (0.1,0) [0|6425.5] "mm" Vector__XXX
 SG_ Aftrtrtmnt2SCRCtlystTnkLvlPrlmnr : 32|5@1+ (1,0) [0|31] "" Vector__XXX
 SG_ Aftrtrtmnt2SCRCtlystRgntTnk1TmpP : 40|5@1+ (1,0) [0|31] "" Vector__XXX
 SG_ Aftrtrtmnt2SCRCtalystTankHeater : 48|8@1+ (0.4,0) [0|100] "%" Vector__XXX
 SG_ Aftrtrtmnt2SCRCtlystRgntTnk1HtrP : 56|5@1+ (1,0) [0|31] "" Vector__XXX

BO_ 2566730750 A2SCRRSI: 8 Vector__XXX
 SG_ Aftrtrtmnt2SCRCtlystRgntPmpMtrSp : 0|16@1+ (0.5,0) [0|32127.5] "rpm" Vector__XXX
 SG_ Aftrtrtmnt2SCRCtlystRgntPmpDrvPr : 16|8@1+ (1,0) [0|100] "%" Vector__XXX
 SG_ Aftrtrtmnt2SCRCtlystRgntRtrnVlve : 24|8@1+ (1,0) [0|100] "%" Vector__XXX
 SG_ Aftrtrtmnt2SCRCtlystRgntTnkFllVl : 32|8@1+ (1,0) [0|100] "%" Vector__XXX
 SG_ Aftrtrtmnt2SCRCtlystRgntPmpState : 40|2@1+ (1,0) [0|3] "" Vector__XXX
 SG_ Aftrtrtmnt2SCRCtlystRgntTnkDrnVl : 48|8@1+ (1,0) [0|100] "%" Vector__XXX

BO_ 2566731518 A2SCRRI: 8 Vector__XXX
 SG_ Aftrtrtmnt2SCRCtlystReagentTemp2 : 0|8@1+ (1,-40) [-40|210] "deg C" Vector__XXX
 SG_ Aftrtrtmnt2SCRCtlystRgntCncntrtn : 8|8@1+ (0.25,0) [0|62.5] "%" Vector__XXX
 SG_ Aftrtrtmnt2SCRCtlystRgntCndctvty : 16|8@1+ (5,0) [0|1250] "microSiemens/mm" Vector__XXX
 SG_ Aftrtrtmnt2SCRCtlystRgntTmp2Prlm : 24|5@1+ (1,0) [0|31] "" Vector__XXX
 SG_ Aftrtrtmnt2SCRCtlystRgntPrprtsPr : 32|5@1+ (1,0) [0|31] "" Vector__XXX
 SG_ Aftrtrtmnt2SCRCtalystReagentType : 40|4@1+ (1,0) [0|15] "" Vector__XXX

BO_ 2566732030 A2SCREGT: 8 Vector__XXX
 SG_ Aftrtrtmnt2SCRCtlystIntkeGasTemp : 0|16@1+ (0.03125,-273) [-273|1734.97] "deg C" Vector__XXX
 SG_ Aftrtrtmnt2SCRCtlystIntkGsTmpPrl : 16|5@1+ (1,0) [0|31] "" Vector__XXX
 SG_ Aftrtrtmnt2SCRCtlystOtletGasTemp : 24|16@1+ (0.03125,-273) [-273|1734.97] "deg C" Vector__XXX
 SG_ Aftrtrtmnt2SCRCtlystOtltGsTmpPrl : 40|5@1+ (1,0) [0|31] "" Vector__XXX

BO_ 2566732286 A2SCREGP: 8 Vector__XXX
 SG_ Aftrtrtmnt2SCRCtlystExhstGsDffPr : 0|16@1+ (0.1,0) [0|6425.5] "kPa" Vector__XXX
 SG_ Aftrtrtmnt2SCRCtlystExhstGsDffPr : 16|5@1+ (1,0) [0|31] "" Vector__XXX

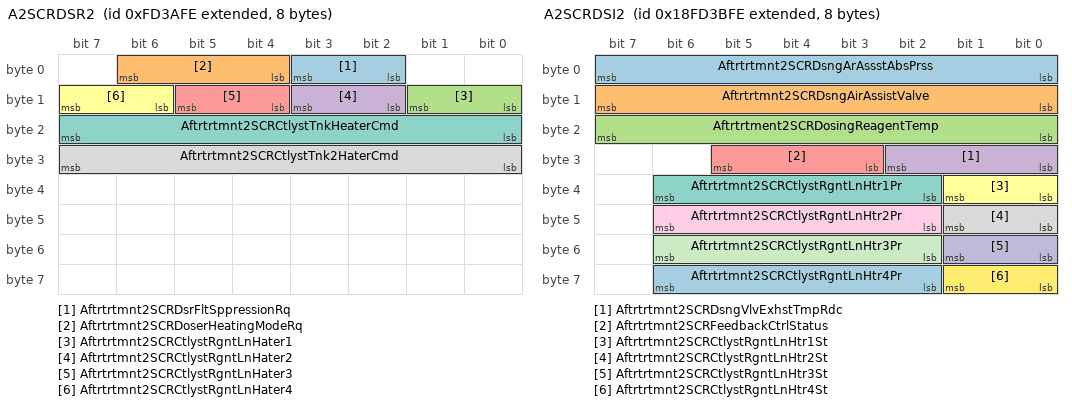
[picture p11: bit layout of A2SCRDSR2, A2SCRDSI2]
BO_ 2164079358 A2SCRDSR2: 8 Vector__XXX
 SG_ Aftrtrtmnt2SCRDsrFltSppressionRq : 2|2@1+ (1,0) [0|3] "" Vector__XXX
 SG_ Aftrtrtmnt2SCRDoserHeatingModeRq : 4|3@1+ (1,0) [0|7] "" Vector__XXX
 SG_ Aftrtrtmnt2SCRCtlystRgntLnHater1 : 8|2@1+ (1,0) [0|3] "" Vector__XXX
 SG_ Aftrtrtmnt2SCRCtlystRgntLnHater2 : 10|2@1+ (1,0) [0|3] "" Vector__XXX
 SG_ Aftrtrtmnt2SCRCtlystRgntLnHater3 : 12|2@1+ (1,0) [0|3] "" Vector__XXX
 SG_ Aftrtrtmnt2SCRCtlystRgntLnHater4 : 14|2@1+ (1,0) [0|3] "" Vector__XXX
 SG_ Aftrtrtmnt2SCRCtlystTnkHeaterCmd : 16|8@1+ (1,0) [0|100] "%" Vector__XXX
 SG_ Aftrtrtmnt2SCRCtlystTnk2HaterCmd : 24|8@1+ (1,0) [0|100] "%" Vector__XXX

BO_ 2364549118 A2SCRDSR1: 8 Vector__XXX
 SG_ Aftrtrtmnt2SCRRqstdDsngRgntQntty : 0|16@1+ (0.3,0) [0|19276.5] "g/h" Vector__XXX
 SG_ Aftrtrtmnt2SCRSystmRquestedState : 16|4@1+ (1,0) [0|15] "" Vector__XXX
 SG_ Aftrtrtmnt2SCRRqstdRgntQnttyFrIn : 24|16@1+ (0.1,0) [0|6425.5] "g" Vector__XXX

BO_ 2566732798 A2SCRDSI2: 8 Vector__XXX
 SG_ Aftrtrtmnt2SCRDsngArAssstAbsPrss : 0|8@1+ (8,0) [0|2000] "kPa" Vector__XXX
 SG_ Aftrtrtmnt2SCRDsngAirAssistValve : 8|8@1+ (1,0) [0|100] "%" Vector__XXX
 SG_ Aftrtrtment2SCRDosingReagentTemp : 16|8@1+ (1,-40) [-40|210] "deg C" Vector__XXX
 SG_ Aftrtrtmnt2SCRDsngVlvExhstTmpRdc : 24|3@1+ (1,0) [0|7] "" Vector__XXX
 SG_ Aftrtrtmnt2SCRFeedbackCtrlStatus : 27|3@1+ (1,0) [0|7] "" Vector__XXX
 SG_ Aftrtrtmnt2SCRCtlystRgntLnHtr1St : 32|2@1+ (1,0) [0|3] "" Vector__XXX
 SG_ Aftrtrtmnt2SCRCtlystRgntLnHtr1Pr : 34|5@1+ (1,0) [0|31] "" Vector__XXX
 SG_ Aftrtrtmnt2SCRCtlystRgntLnHtr2St : 40|2@1+ (1,0) [0|3] "" Vector__XXX
 SG_ Aftrtrtmnt2SCRCtlystRgntLnHtr2Pr : 42|5@1+ (1,0) [0|31] "" Vector__XXX
 SG_ Aftrtrtmnt2SCRCtlystRgntLnHtr3St : 48|2@1+ (1,0) [0|3] "" Vector__XXX
 SG_ Aftrtrtmnt2SCRCtlystRgntLnHtr3Pr : 50|5@1+ (1,0) [0|31] "" Vector__XXX
 SG_ Aftrtrtmnt2SCRCtlystRgntLnHtr4St : 56|2@1+ (1,0) [0|3] "" Vector__XXX
 SG_ Aftrtrtmnt2SCRCtlystRgntLnHtr4Pr : 58|5@1+ (1,0) [0|31] "" Vector__XXX

BO_ 2364548862 A2SCRDSI1: 8 Vector__XXX
 SG_ Aftrtrtmnt2SCRActlDsngRgntQntity : 0|16@1+ (0.3,0) [0|19276.5] "g/h" Vector__XXX
 SG_ Aftertreatment2SCRSystemState : 16|4@1+ (1,0) [0|15] "" Vector__XXX
 SG_ Aftrtrtmnt2SCRActlRgntQnttyOfInt : 24|16@1+ (0.1,0) [0|6425.5] "g" Vector__XXX
 SG_ Aftrtrtmnt2SCRDsngRagentAbsPress : 40|8@1+ (8,0) [0|2000] "kPa" Vector__XXX

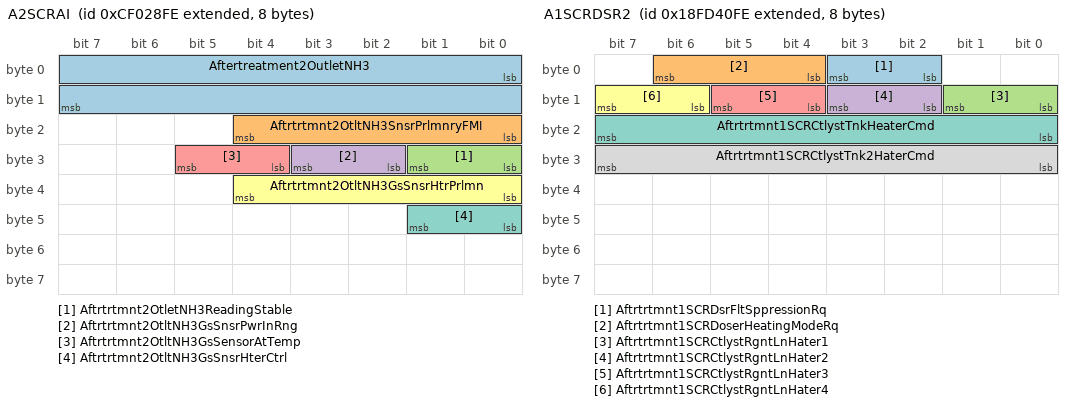
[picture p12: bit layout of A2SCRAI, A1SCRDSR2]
BO_ 2364549374 A2SCRAI: 8 Vector__XXX
 SG_ Aftertreatment2OutletNH3 : 0|16@1+ (0.3,0) [0|19276.5] "g/h" Vector__XXX
 SG_ Aftrtrtmnt2OtltNH3SnsrPrlmnryFMI : 16|5@1+ (1,0) [0|31] "" Vector__XXX
 SG_ Aftrtrtmnt2OtletNH3ReadingStable : 24|2@1+ (1,0) [0|3] "" Vector__XXX
 SG_ Aftrtrtmnt2OtltNH3GsSnsrPwrInRng : 26|2@1+ (1,0) [0|3] "" Vector__XXX
 SG_ Aftrtrtmnt2OtltNH3GsSensorAtTemp : 28|2@1+ (1,0) [0|3] "" Vector__XXX
 SG_ Aftrtrtmnt2OtltNH3GsSnsrHtrPrlmn : 32|5@1+ (1,0) [0|31] "" Vector__XXX
 SG_ Aftrtrtmnt2OtltNH3GsSnsrHterCtrl : 40|2@1+ (1,0) [0|3] "" Vector__XXX

BO_ 2566726142 A2GOC: 8 Vector__XXX
 SG_ Aftrtrtmnt2GsOxdtnCtlystIntkGsTm : 0|16@1+ (0.03125,-273) [-273|1734.97] "deg C" Vector__XXX
 SG_ Aftrtrtmnt2GsOxdtnCtlystOtltGsTm : 16|16@1+ (0.03125,-273) [-273|1734.97] "deg C" Vector__XXX
 SG_ Aftrtrtmnt2GsOxdtnCtlystDffPress : 32|16@1+ (0.1,0) [0|6425.5] "kPa" Vector__XXX
 SG_ Aftrtrtmnt2GsOxdtnCtlystIntkGsTm : 48|5@1+ (1,0) [0|31] "" Vector__XXX
 SG_ Aftrtrtmnt2GsOxdtnCtlystOtltGsTm : 53|5@1+ (1,0) [0|31] "" Vector__XXX
 SG_ Aftrtrtmnt2GsOxdtnCtlystDffPrssP : 58|5@1+ (1,0) [0|31] "" Vector__XXX

BO_ 2566725630 A2DOC: 8 Vector__XXX
 SG_ Aftrtrtmnt2DslOxdtnCtlystDffPrss : 58|5@1+ (1,0) [0|31] "" Vector__XXX
 SG_ Aftrtrtmnt2DslOxdtnCtlystIntkGsT : 0|16@1+ (0.03125,-273) [-273|1734.97] "deg C" Vector__XXX
 SG_ Aftrtrtmnt2DslOxdtnCtlystOtltGsT : 16|16@1+ (0.03125,-273) [-273|1734.97] "deg C" Vector__XXX
 SG_ Aftrtrtmnt2DslOxdtnCtlystDffPrss : 32|16@1+ (0.5,0) [0|32127.5] "kPa" Vector__XXX
 SG_ Aftrtrtmnt2DslOxdtnCtlystIntkGsT : 48|5@1+ (1,0) [0|31] "" Vector__XXX
 SG_ Aftrtrtmnt2DslOxdtnCtlystOtltGsT : 53|5@1+ (1,0) [0|31] "" Vector__XXX

BO_ 2566733310 A1SCRRT2I: 8 Vector__XXX
 SG_ Aftrtrtmnt1SCRCtlystRgntTnk2Lvel : 0|8@1+ (0.4,0) [0|100] "%" Vector__XXX
 SG_ Aftrtrtmnt1SCRCtlystRgntTnk2Temp : 8|8@1+ (1,-40) [-40|210] "deg C" Vector__XXX
 SG_ Aftrtrtmnt1SCRCtlystRgntTnk2Lvl2 : 16|16@1+ (1,0) [0|6426] "mm" Vector__XXX
 SG_ Aftrtrtmnt1SCRCtlystRgntTnk2LvlP : 32|5@1+ (1,0) [0|31] "" Vector__XXX
 SG_ Aftrtrtmnt1SCRRgntTnk2TmpPrlmnry : 40|5@1+ (1,0) [0|31] "" Vector__XXX
 SG_ Aftrtrtmnt1SCRCtlystRgntTnk2Hter : 48|8@1+ (0.4,0) [0|100] "%" Vector__XXX
 SG_ Aftrtrtmnt1SCRCtlystRgntTnk2HtrP : 56|5@1+ (1,0) [0|31] "" Vector__XXX

BO_ 2566733054 A1SCRRSI: 8 Vector__XXX
 SG_ Aftrtrtmnt1SCRCtlystRgntPmpMtrSp : 0|16@1+ (0.5,0) [0|32127.5] "rpm" Vector__XXX
 SG_ Aftrtrtmnt1SCRCtlystRgntPmpDrvPr : 16|8@1+ (1,0) [0|100] "%" Vector__XXX
 SG_ Aftrtrtmnt1SCRCtlystRgntRtrnVlve : 24|8@1+ (1,0) [0|100] "%" Vector__XXX
 SG_ Aftrtrtmnt1SCRCtlystRgntTnkFllVl : 32|8@1+ (1,0) [0|100] "%" Vector__XXX
 SG_ Aftrtrtmnt1SCRCtlystRgntPmpState : 40|2@1+ (1,0) [0|3] "" Vector__XXX
 SG_ Aftrtrtmnt1SCRCtlystRgntTnkDrnVl : 48|8@1+ (1,0) [0|100] "%" Vector__XXX

BO_ 2499624702 A1SCREGT: 8 Vector__XXX
 SG_ Aftrtrtmnt1SCRCtlystIntkeGasTemp : 0|16@1+ (0.03125,-273) [-273|1734.97] "deg C" Vector__XXX
 SG_ Aftrtrtmnt1SCRCtlystIntkGsTmpPrl : 16|5@1+ (1,0) [0|31] "" Vector__XXX
 SG_ Aftrtrtmnt1SCRCtlystOtletGasTemp : 24|16@1+ (0.03125,-273) [-273|1734.97] "deg C" Vector__XXX
 SG_ Aftrtrtmnt1SCRCtlystOtltGsTmpPrl : 40|5@1+ (1,0) [0|31] "" Vector__XXX

BO_ 2566733822 A1SCREGP: 8 Vector__XXX
 SG_ Aftrtrtmnt1SCRCtlystExhstGsDffPr : 0|16@1+ (0.1,0) [0|6425.5] "kPa" Vector__XXX
 SG_ Aftrtrtmnt1SCRCtlystExhstGsDffPr : 16|5@1+ (1,0) [0|31] "" Vector__XXX

BO_ 2566734078 A1SCRDSR2: 8 Vector__XXX
 SG_ Aftrtrtmnt1SCRDsrFltSppressionRq : 2|2@1+ (1,0) [0|3] "" Vector__XXX
 SG_ Aftrtrtmnt1SCRDoserHeatingModeRq : 4|3@1+ (1,0) [0|7] "" Vector__XXX
 SG_ Aftrtrtmnt1SCRCtlystRgntLnHater1 : 8|2@1+ (1,0) [0|3] "" Vector__XXX
 SG_ Aftrtrtmnt1SCRCtlystRgntLnHater2 : 10|2@1+ (1,0) [0|3] "" Vector__XXX
 SG_ Aftrtrtmnt1SCRCtlystRgntLnHater3 : 12|2@1+ (1,0) [0|3] "" Vector__XXX
 SG_ Aftrtrtmnt1SCRCtlystRgntLnHater4 : 14|2@1+ (1,0) [0|3] "" Vector__XXX
 SG_ Aftrtrtmnt1SCRCtlystTnkHeaterCmd : 16|8@1+ (1,0) [0|100] "%" Vector__XXX
 SG_ Aftrtrtmnt1SCRCtlystTnk2HaterCmd : 24|8@1+ (1,0) [0|100] "%" Vector__XXX

BO_ 2364548350 A1SCRDSR1: 8 Vector__XXX
 SG_ Aftrtrtmnt1SCRRqstdDsngRgntQntty : 0|16@1+ (0.3,0) [0|19276.5] "g/h" Vector__XXX
 SG_ Aftrtrtmnt1SCRSystmRquestedState : 16|4@1+ (1,0) [0|15] "" Vector__XXX
 SG_ Aftrtrtmnt1SCRRqstdRgntQnttyFrIn : 24|16@1+ (0.1,0) [0|6425.5] "g" Vector__XXX

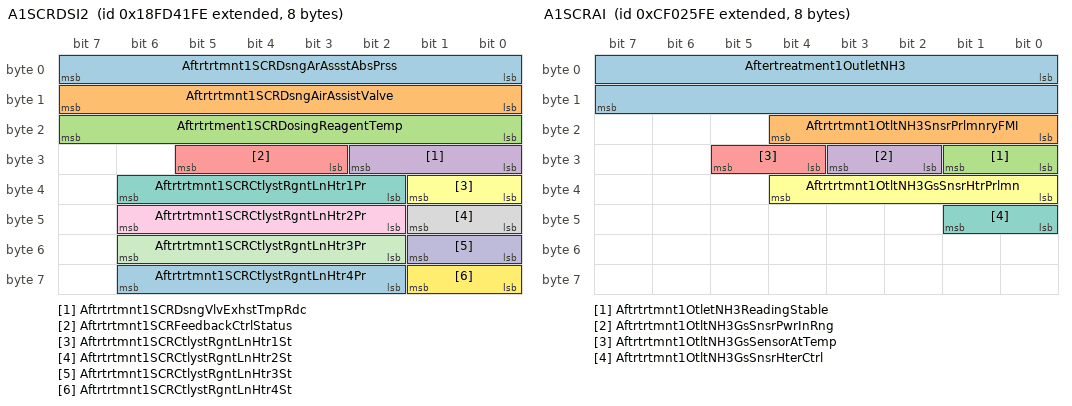
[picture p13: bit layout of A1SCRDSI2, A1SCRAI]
BO_ 2566734334 A1SCRDSI2: 8 Vector__XXX
 SG_ Aftrtrtmnt1SCRDsngArAssstAbsPrss : 0|8@1+ (8,0) [0|2000] "kPa" Vector__XXX
 SG_ Aftrtrtmnt1SCRDsngAirAssistValve : 8|8@1+ (1,0) [0|100] "%" Vector__XXX
 SG_ Aftrtrtment1SCRDosingReagentTemp : 16|8@1+ (1,-40) [-40|210] "deg C" Vector__XXX
 SG_ Aftrtrtmnt1SCRDsngVlvExhstTmpRdc : 24|3@1+ (1,0) [0|7] "" Vector__XXX
 SG_ Aftrtrtmnt1SCRFeedbackCtrlStatus : 27|3@1+ (1,0) [0|7] "" Vector__XXX
 SG_ Aftrtrtmnt1SCRCtlystRgntLnHtr1St : 32|2@1+ (1,0) [0|3] "" Vector__XXX
 SG_ Aftrtrtmnt1SCRCtlystRgntLnHtr1Pr : 34|5@1+ (1,0) [0|31] "" Vector__XXX
 SG_ Aftrtrtmnt1SCRCtlystRgntLnHtr2St : 40|2@1+ (1,0) [0|3] "" Vector__XXX
 SG_ Aftrtrtmnt1SCRCtlystRgntLnHtr2Pr : 42|5@1+ (1,0) [0|31] "" Vector__XXX
 SG_ Aftrtrtmnt1SCRCtlystRgntLnHtr3St : 48|2@1+ (1,0) [0|3] "" Vector__XXX
 SG_ Aftrtrtmnt1SCRCtlystRgntLnHtr3Pr : 50|5@1+ (1,0) [0|31] "" Vector__XXX
 SG_ Aftrtrtmnt1SCRCtlystRgntLnHtr4St : 56|2@1+ (1,0) [0|3] "" Vector__XXX
 SG_ Aftrtrtmnt1SCRCtlystRgntLnHtr4Pr : 58|5@1+ (1,0) [0|31] "" Vector__XXX

BO_ 2364548094 A1SCRDSI1: 8 Vector__XXX
 SG_ Aftrtrtmnt1SCRActlDsngRgntQntity : 0|16@1+ (0.3,0) [0|19276.5] "g/h" Vector__XXX
 SG_ Aftertreatment1SCRSystemState : 16|4@1+ (1,0) [0|15] "" Vector__XXX
 SG_ Aftrtrtmnt1SCRActlRgntQnttyOfInt : 24|16@1+ (0.1,0) [0|6425.5] "g" Vector__XXX
 SG_ Aftrtrtmnt1SCRDsngRagentAbsPress : 40|8@1+ (8,0) [0|2000] "kPa" Vector__XXX

BO_ 2364548606 A1SCRAI: 8 Vector__XXX
 SG_ Aftertreatment1OutletNH3 : 0|16@1+ (0.3,0) [0|19276.5] "g/h" Vector__XXX
 SG_ Aftrtrtmnt1OtltNH3SnsrPrlmnryFMI : 16|5@1+ (1,0) [0|31] "" Vector__XXX
 SG_ Aftrtrtmnt1OtletNH3ReadingStable : 24|2@1+ (1,0) [0|3] "" Vector__XXX
 SG_ Aftrtrtmnt1OtltNH3GsSnsrPwrInRng : 26|2@1+ (1,0) [0|3] "" Vector__XXX
 SG_ Aftrtrtmnt1OtltNH3GsSensorAtTemp : 28|2@1+ (1,0) [0|3] "" Vector__XXX
 SG_ Aftrtrtmnt1OtltNH3GsSnsrHtrPrlmn : 32|5@1+ (1,0) [0|31] "" Vector__XXX
 SG_ Aftrtrtmnt1OtltNH3GsSnsrHterCtrl : 40|2@1+ (1,0) [0|3] "" Vector__XXX

BO_ 2566726398 A1GOC: 8 Vector__XXX
 SG_ Aftrtrtmnt1GsOxdtnCtlystIntkGsTm : 0|16@1+ (0.03125,-273) [-273|1734.97] "deg C" Vector__XXX
 SG_ Aftrtrtmnt1GsOxdtnCtlystOtltGsTm : 16|16@1+ (0.03125,-273) [-273|1734.97] "deg C" Vector__XXX
 SG_ Aftrtrtmnt1GsOxdtnCtlystDffPress : 32|16@1+ (0.1,0) [0|6425.5] "kPa" Vector__XXX
 SG_ Aftrtrtmnt1GsOxdtnCtlystIntkGsTm : 48|5@1+ (1,0) [0|31] "" Vector__XXX
 SG_ Aftrtrtmnt1GsOxdtnCtlystOtltGsTm : 53|5@1+ (1,0) [0|31] "" Vector__XXX
 SG_ Aftrtrtmnt1GsOxdtnCtlystDffPrssP : 58|5@1+ (1,0) [0|31] "" Vector__XXX

BO_ 2566742270 DM40: 8 Vector__XXX
 SG_ SPN1 : 0|16@1+ (1,0) [0|65535] "" Vector__XXX
 SG_ SPN1High : 21|3@1+ (1,0) [0|7] "" Vector__XXX
 SG_ FailureModeIdentifier1 : 16|5@1+ (1,0) [0|31] "" Vector__XXX
 SG_ FailureSpecificB1Counter : 24|16@1+ (0.1,0) [0|6425.5] "hr" Vector__XXX

BO_ 2566742526 DM39: 8 Vector__XXX
 SG_ SysCumulativeContinuousMITime : 0|32@1+ (0.05,0) [0|210554000] "hr" Vector__XXX
 SG_ SysGreatestB1Counter : 32|16@1+ (0.1,0) [0|6425.5] "hr" Vector__XXX

BO_ 2566742782 DM38: 8 Vector__XXX
 SG_ RegulationDescription : 0|8@1+ (1,0) [0|255] "" Vector__XXX

BO_ 2566743038 DM37: 8 Vector__XXX
 SG_ SysNonRoadworthyCompCount : 0|8@1+ (1,0) [0|250] "" Vector__XXX
 SG_ SysContinuousMalfunctionInd : 14|2@1+ (1,0) [0|3] "" Vector__XXX
 SG_ SysMalIndDisplayStrategy : 12|2@1+ (1,0) [0|3] "" Vector__XXX
 SG_ SysMalIndActivationMode : 8|4@1+ (1,0) [0|15] "" Vector__XXX
 SG_ SysIncompleteMonitorCount : 16|16@1+ (1,0) [0|64512] "" Vector__XXX

BO_ 2566743294 DM36: 8 Vector__XXX
 SG_ VehicleNonRoadworthyCompCount : 0|8@1+ (1,0) [0|250] "" Vector__XXX
 SG_ VehicleContinuousMalfunctionInd : 12|2@1+ (1,0) [0|3] "" Vector__XXX
 SG_ VehicleMalfunctionIndStrategy : 14|2@1+ (1,0) [0|3] "" Vector__XXX
 SG_ VehicleMalfunctionIndActMode : 8|4@1+ (1,0) [0|15] "" Vector__XXX
 SG_ VehicleIncompleteMonitorCount : 16|16@1+ (1,0) [0|64255] "" Vector__XXX
 SG_ VehicleCurrentMIAccumTime : 32|16@1+ (1,0) [0|64255] "min" Vector__XXX

BO_ 2560687870 DM34: 8 Vector__XXX
 SG_ NOxNTEControlAreaStatus : 6|2@1+ (1,0) [0|3] "" Vector__XXX
 SG_ MnfcNOxNTECarveOutAreaStatus : 4|2@1+ (1,0) [0|3] "" Vector__XXX
 SG_ NOxNTEDeficiencyAreaStatus : 2|2@1+ (1,0) [0|3] "" Vector__XXX
 SG_ PMNTEControlAreaStatus : 14|2@1+ (1,0) [0|3] "" Vector__XXX
 SG_ MnfcPMNTECarveOutAreaStatus : 12|2@1+ (1,0) [0|3] "" Vector__XXX
 SG_ PMNTEDeficiencyAreaStatus : 10|2@1+ (1,0) [0|3] "" Vector__XXX

BO_ 2566809342 BM: 8 Vector__XXX
 SG_ BatteryMainSwitchHoldState : 0|2@1+ (1,0) [0|3] "" Vector__XXX

BO_ 2365446910 BJM3: 8 Vector__XXX
 SG_ Joystick3Button4PressedStatus : 40|2@1+ (1,0) [0|3] "" Vector__XXX
 SG_ Joystick3Button3PressedStatus : 42|2@1+ (1,0) [0|3] "" Vector__XXX
 SG_ Joystick3Button2PressedStatus : 44|2@1+ (1,0) [0|3] "" Vector__XXX
 SG_ Joystick3Button1PressedStatus : 46|2@1+ (1,0) [0|3] "" Vector__XXX
 SG_ Joystick3Button8PressedStatus : 48|2@1+ (1,0) [0|3] "" Vector__XXX
 SG_ Joystick3Button7PressedStatus : 50|2@1+ (1,0) [0|3] "" Vector__XXX
 SG_ Joystick3Button6PressedStatus : 52|2@1+ (1,0) [0|3] "" Vector__XXX
 SG_ Joystick3Button5PressedStatus : 54|2@1+ (1,0) [0|3] "" Vector__XXX
 SG_ Joystick3XAxisNeutralPosStatus : 0|2@1+ (1,0) [0|3] "" Vector__XXX
 SG_ Jystck3XAxsLvrLftNgtivePosStatus : 2|2@1+ (1,0) [0|3] "" Vector__XXX
 SG_ Jystck3XAxsLvrRghtPstvePosStatus : 4|2@1+ (1,0) [0|3] "" Vector__XXX
 SG_ Joystick3XAxisPos : 6|10@1+ (1,0) [0|102] "%" Vector__XXX
 SG_ Joystick3YAxisNeutralPosStatus : 16|2@1+ (1,0) [0|3] "" Vector__XXX
 SG_ Jystck3YAxsLvrBckNgtivePosStatus : 18|2@1+ (1,0) [0|3] "" Vector__XXX
 SG_ Jystck3YAxsLvrFrwrdPstvPosStatus : 20|2@1+ (1,0) [0|3] "" Vector__XXX
 SG_ Joystick3YAxisPos : 22|10@1+ (1,0) [0|102] "%" Vector__XXX
 SG_ Joystick3YAxisDetentPosStatus : 36|2@1+ (1,0) [0|3] "" Vector__XXX
 SG_ Joystick3Button12PressedStatus : 56|2@1+ (1,0) [0|3] "" Vector__XXX
 SG_ Joystick3Button11PressedStatus : 58|2@1+ (1,0) [0|3] "" Vector__XXX
 SG_ Joystick3Button10PressedStatus : 60|2@1+ (1,0) [0|3] "" Vector__XXX
 SG_ Joystick3Button9PressedStatus : 62|2@1+ (1,0) [0|3] "" Vector__XXX
 SG_ Joystick3XAxisDetentPosStatus : 38|2@1+ (1,0) [0|3] "" Vector__XXX

BO_ 2365446398 BJM2: 8 Vector__XXX
 SG_ Joystick2Button4PressedStatus : 40|2@1+ (1,0) [0|3] "" Vector__XXX
 SG_ Joystick2Button3PressedStatus : 42|2@1+ (1,0) [0|3] "" Vector__XXX
 SG_ Joystick2Button2PressedStatus : 44|2@1+ (1,0) [0|3] "" Vector__XXX
 SG_ Joystick2Button1PressedStatus : 46|2@1+ (1,0) [0|3] "" Vector__XXX
 SG_ Joystick2Button8PressedStatus : 48|2@1+ (1,0) [0|3] "" Vector__XXX
 SG_ Joystick2Button7PressedStatus : 50|2@1+ (1,0) [0|3] "" Vector__XXX
 SG_ Joystick2Button6PressedStatus : 52|2@1+ (1,0) [0|3] "" Vector__XXX
 SG_ Joystick2Button5PressedStatus : 54|2@1+ (1,0) [0|3] "" Vector__XXX
 SG_ Joystick2Button12PressedStatus : 56|2@1+ (1,0) [0|3] "" Vector__XXX
 SG_ Joystick2Button11PressedStatus : 58|2@1+ (1,0) [0|3] "" Vector__XXX
 SG_ Joystick2Button10PressedStatus : 60|2@1+ (1,0) [0|3] "" Vector__XXX
 SG_ Joystick2Button9PressedStatus : 62|2@1+ (1,0) [0|3] "" Vector__XXX
 SG_ Joystick2XAxisNeutralPosStatus : 0|2@1+ (1,0) [0|3] "" Vector__XXX
 SG_ Jystck2XAxsLvrLftNgtivePosStatus : 2|2@1+ (1,0) [0|3] "" Vector__XXX
 SG_ Jystck2XAxsLvrRghtPstvePosStatus : 4|2@1+ (1,0) [0|3] "" Vector__XXX
 SG_ Joystick2XAxisPos : 6|10@1+ (1,0) [0|102] "%" Vector__XXX
 SG_ Joystick2YAxisNeutralPosStatus : 16|2@1+ (1,0) [0|3] "" Vector__XXX
 SG_ Jystck2YAxsLvrBckNgtivePosStatus : 18|2@1+ (1,0) [0|3] "" Vector__XXX
 SG_ Jystck2YAxsLvrFrwrdPstvPosStatus : 20|2@1+ (1,0) [0|3] "" Vector__XXX
 SG_ Joystick2YAxisPos : 22|10@1+ (1,0) [0|102] "%" Vector__XXX
 SG_ Joystick2YAxisDetentPosStatus : 36|2@1+ (1,0) [0|3] "" Vector__XXX
 SG_ Joystick2XAxisDetentPosStatus : 38|2@1+ (1,0) [0|3] "" Vector__XXX

BO_ 2365445886 BJM1: 8 Vector__XXX
 SG_ Joystick1XAxisNeutralPosStatus : 0|2@1+ (1,0) [0|3] "" Vector__XXX
 SG_ Jystck1XAxsLvrLftNgtivePosStatus : 2|2@1+ (1,0) [0|3] "" Vector__XXX
 SG_ Jystck1XAxsLvrRghtPstvePosStatus : 4|2@1+ (1,0) [0|3] "" Vector__XXX
 SG_ Joystick1Button4PressedStatus : 40|2@1+ (1,0) [0|3] "" Vector__XXX
 SG_ Joystick1Button3PressedStatus : 42|2@1+ (1,0) [0|3] "" Vector__XXX
 SG_ Joystick1Button2PressedStatus : 44|2@1+ (1,0) [0|3] "" Vector__XXX
 SG_ Joystick1Button1PressedStatus : 46|2@1+ (1,0) [0|3] "" Vector__XXX
 SG_ Joystick1Button8PressedStatus : 48|2@1+ (1,0) [0|3] "" Vector__XXX
 SG_ Joystick1Button7PressedStatus : 50|2@1+ (1,0) [0|3] "" Vector__XXX
 SG_ Joystick1Button6PressedStatus : 52|2@1+ (1,0) [0|3] "" Vector__XXX
 SG_ Joystick1Button5PressedStatus : 54|2@1+ (1,0) [0|3] "" Vector__XXX
 SG_ Joystick1Button12PressedStatus : 56|2@1+ (1,0) [0|3] "" Vector__XXX
 SG_ Joystick1Button11PressedStatus : 58|2@1+ (1,0) [0|3] "" Vector__XXX
 SG_ Joystick1Button10PressedStatus : 60|2@1+ (1,0) [0|3] "" Vector__XXX
 SG_ Joystick1Button9PressedStatus : 62|2@1+ (1,0) [0|3] "" Vector__XXX
 SG_ Joystick1XAxisPos : 6|10@1+ (1,0) [0|102] "%" Vector__XXX
 SG_ Joystick1YAxisNeutralPosStatus : 16|2@1+ (1,0) [0|3] "" Vector__XXX
 SG_ Jystck1YAxsLvrBckNgtivePosStatus : 18|2@1+ (1,0) [0|3] "" Vector__XXX
 SG_ Jystck1YAxsLvrFrwrdPstvPosStatus : 20|2@1+ (1,0) [0|3] "" Vector__XXX
 SG_ Joystick1YAxisPos : 22|10@1+ (1,0) [0|102] "%" Vector__XXX
 SG_ Joystick1YAxisDetentPosStatus : 36|2@1+ (1,0) [0|3] "" Vector__XXX
 SG_ Joystick1XAxisDetentPosStatus : 38|2@1+ (1,0) [0|3] "" Vector__XXX

BO_ 2566847230 B: 8 Vector__XXX
 SG_ BrakeAppPress : 0|8@1+ (4,0) [0|1000] "kPa" Vector__XXX
 SG_ BrakePrimaryPress : 8|8@1+ (4,0) [0|1000] "kPa" Vector__XXX
 SG_ BrakeSecondPress : 16|8@1+ (4,0) [0|1000] "kPa" Vector__XXX
 SG_ ParkingBrakeActuator : 24|2@1+ (1,0) [0|3] "" Vector__XXX
 SG_ ParkBrakeReleaseInhibitStatus : 28|2@1+ (1,0) [0|3] "" Vector__XXX
 SG_ ParkingBrakeRedWarningSignal : 26|2@1+ (1,0) [0|3] "" Vector__XXX

BO_ 2566848254 AWPP: 8 Vector__XXX
 SG_ AuxPumpPress : 0|8@1+ (16,0) [0|4000] "kPa" Vector__XXX

BO_ 2566725886 A1DOC: 8 Vector__XXX
 SG_ Aftrtrtmnt1DslOxdtnCtlystIntkGsT : 0|16@1+ (0.03125,-273) [-273|1734.97] "deg C" Vector__XXX
 SG_ Aftrtrtmnt1DslOxdtnCtlystOtltGsT : 16|16@1+ (0.03125,-273) [-273|1734.97] "deg C" Vector__XXX
 SG_ Aftrtrtmnt1DslOxdtnCtlystDffPrss : 32|16@1+ (0.1,0) [0|6425.5] "kPa" Vector__XXX
 SG_ Aftrtrtmnt1DslOxdtnCtlystIntkGsT : 48|5@1+ (1,0) [0|31] "" Vector__XXX
 SG_ Aftrtrtmnt1DslOxdtnCtlystOtltGsT : 53|5@1+ (1,0) [0|31] "" Vector__XXX
 SG_ Aftrtrtmnt1DslOxdtnCtlystDffPrss : 58|5@1+ (1,0) [0|31] "" Vector__XXX

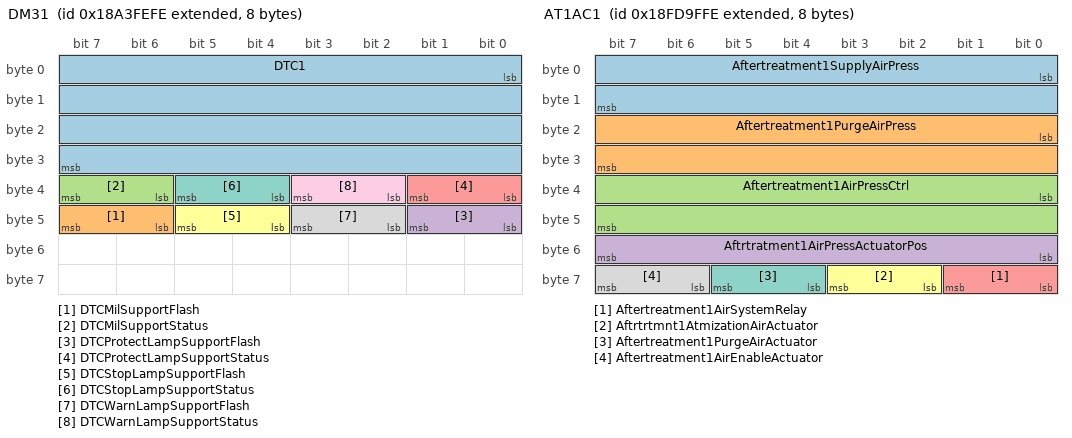
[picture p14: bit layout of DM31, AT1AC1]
BO_ 2560884478 DM31: 8 Vector__XXX
 SG_ DTC1 : 0|32@1+ (1,0) [0|2704] "" Vector__XXX
 SG_ DTCMilSupportFlash : 46|2@1+ (1,0) [0|3] "" Vector__XXX
 SG_ DTCMilSupportStatus : 38|2@1+ (1,0) [0|3] "" Vector__XXX
 SG_ DTCProtectLampSupportFlash : 40|2@1+ (1,0) [0|3] "" Vector__XXX
 SG_ DTCProtectLampSupportStatus : 32|2@1+ (1,0) [0|3] "" Vector__XXX
 SG_ DTCStopLampSupportFlash : 44|2@1+ (1,0) [0|3] "" Vector__XXX
 SG_ DTCStopLampSupportStatus : 36|2@1+ (1,0) [0|3] "" Vector__XXX
 SG_ DTCWarnLampSupportFlash : 42|2@1+ (1,0) [0|3] "" Vector__XXX
 SG_ DTCWarnLampSupportStatus : 34|2@1+ (1,0) [0|3] "" Vector__XXX

BO_ 2633844734 TML: 8 Vector__XXX

BO_ 2560360190 PMI: 8 Vector__XXX
 SG_ DataDictionaryManufacturerCode : 0|11@1+ (1,0) [0|2047] "" Vector__XXX
 SG_ DataDictionaryMethod : 11|21@1+ (1,0) [0|2097150] "" Vector__XXX

BO_ 2566736126 O2FT2: 8 Vector__XXX
 SG_ LongtermFuelTrimBank2 : 0|16@1+ (1,-100) [-100|100] "%" Vector__XXX
 SG_ ShorttermFuelTrimBank2 : 16|16@1+ (1,-100) [-100|100] "%" Vector__XXX
 SG_ EngExhstGsOxygnSnsrClsdLpOprtnBn : 32|4@1+ (1,0) [0|15] "" Vector__XXX

BO_ 2566736382 O2FT1: 8 Vector__XXX
 SG_ LongtermFuelTrimBank1 : 0|16@1+ (1,-100) [-100|100] "%" Vector__XXX
 SG_ ShorttermFuelTrimBank1 : 16|16@1+ (1,-100) [-100|100] "%" Vector__XXX
 SG_ EngExhstGsOxygnSnsrClsdLpOprtnBn : 32|4@1+ (1,0) [0|15] "" Vector__XXX

BO_ 2565874174 ESSI: 8 Vector__XXX
 SG_ EngSpeed1 : 0|16@1+ (0.5,0) [0|32127.5] "rpm" Vector__XXX
 SG_ EngSpeed2 : 16|16@1+ (0.5,0) [0|32127.5] "rpm" Vector__XXX
 SG_ EngSpeed3 : 32|16@1+ (0.5,0) [0|32127.5] "rpm" Vector__XXX
 SG_ EngSpdSensor3TimingPatternStatus : 50|2@1+ (1,0) [0|3] "" Vector__XXX
 SG_ EngSpdSensor2TimingPatternStatus : 52|2@1+ (1,0) [0|3] "" Vector__XXX
 SG_ EngSpdSensor1TimingPatternStatus : 54|2@1+ (1,0) [0|3] "" Vector__XXX

BO_ 2432520958 ECCVC: 8 Vector__XXX
 SG_ EngCoolantThermostatMode : 0|2@1+ (1,0) [0|3] "" Vector__XXX
 SG_ DesiredEngCoolantPumpOutletTemp : 8|8@1+ (1,-40) [-40|210] "deg C" Vector__XXX
 SG_ DsredEngCoolantThermostatOpening : 16|8@1+ (1,0) [0|100] "%" Vector__XXX

BO_ 2560425726 AUXIO7: 8 Vector__XXX
 SG_ AuxI_OChannel18 : 0|8@1+ (1,0) [0|250] "" Vector__XXX
 SG_ AuxI_OChannel17 : 8|8@1+ (1,0) [0|250] "" Vector__XXX
 SG_ AuxI_OChannel16 : 16|8@1+ (1,0) [0|250] "" Vector__XXX
 SG_ AuxI_OChannel15 : 24|8@1+ (1,0) [0|250] "" Vector__XXX
 SG_ AuxI_OChannel22 : 32|8@1+ (1,0) [0|250] "" Vector__XXX
 SG_ AuxI_OChannel21 : 40|8@1+ (1,0) [0|250] "" Vector__XXX
 SG_ AuxI_OChannel20 : 48|8@1+ (1,0) [0|250] "" Vector__XXX
 SG_ AuxI_OChannel19 : 56|8@1+ (1,0) [0|250] "" Vector__XXX

BO_ 2560491262 AUXIO6: 8 Vector__XXX
 SG_ AuxI_OChannel10 : 0|8@1+ (1,0) [0|250] "" Vector__XXX
 SG_ AuxI_OChannel9 : 8|8@1+ (1,0) [0|250] "" Vector__XXX
 SG_ AuxI_OChannel8 : 16|8@1+ (1,0) [0|250] "" Vector__XXX
 SG_ AuxI_OChannel7 : 24|8@1+ (1,0) [0|250] "" Vector__XXX
 SG_ AuxI_OChannel14 : 32|8@1+ (1,0) [0|250] "" Vector__XXX
 SG_ AuxI_OChannel13 : 40|8@1+ (1,0) [0|250] "" Vector__XXX
 SG_ AuxI_OChannel12 : 48|8@1+ (1,0) [0|250] "" Vector__XXX
 SG_ AuxI_OChannel11 : 56|8@1+ (1,0) [0|250] "" Vector__XXX

BO_ 2349399806 AUXIO5: 8 Vector__XXX
 SG_ AuxI_OChannel6 : 0|16@1+ (1,0) [0|64255] "counts" Vector__XXX
 SG_ AuxI_OChannel5 : 16|16@1+ (1,0) [0|64255] "counts" Vector__XXX
 SG_ AuxI_OChannel4 : 32|16@1+ (1,0) [0|64255] "counts" Vector__XXX
 SG_ AuxI_OChannel3 : 48|16@1+ (1,0) [0|64255] "counts" Vector__XXX

BO_ 2566758398 AT1AC1: 8 Vector__XXX
 SG_ Aftertreatment1SupplyAirPress : 0|16@1+ (0.1,0) [0|6425.5] "kPa" Vector__XXX
 SG_ Aftertreatment1PurgeAirPress : 16|16@1+ (0.1,0) [0|6425.5] "kPa" Vector__XXX
 SG_ Aftertreatment1AirPressCtrl : 32|16@1+ (0.0025,0) [0|160.637] "%" Vector__XXX
 SG_ Aftrtratment1AirPressActuatorPos : 48|8@1+ (0.4,0) [0|100] "%" Vector__XXX
 SG_ Aftertreatment1AirSystemRelay : 56|2@1+ (1,0) [0|3] "" Vector__XXX
 SG_ Aftrtrtmnt1AtmizationAirActuator : 58|2@1+ (1,0) [0|3] "" Vector__XXX
 SG_ Aftertreatment1PurgeAirActuator : 60|2@1+ (1,0) [0|3] "" Vector__XXX
 SG_ Aftertreatment1AirEnableActuator : 62|2@1+ (1,0) [0|3] "" Vector__XXX

BO_ 2566745598 AT1AC2: 8 Vector__XXX
 SG_ Aftrtreatment1SecondAirDiffPress : 0|16@1+ (0.007812,-250) [-250|251.96] "kPa" Vector__XXX
 SG_ Aftertreatment1SecondAirTemp : 16|16@1+ (0.03125,-273) [-273|1734.97] "deg C" Vector__XXX
 SG_ Aftertreatment1SecondAirMassFlow : 32|16@1+ (0.2,0) [0|12851] "kg/h per bit" Vector__XXX
 SG_ Aftertreatment1SecondAirPress : 48|16@1+ (0.1,0) [0|6425.5] "kPa" Vector__XXX

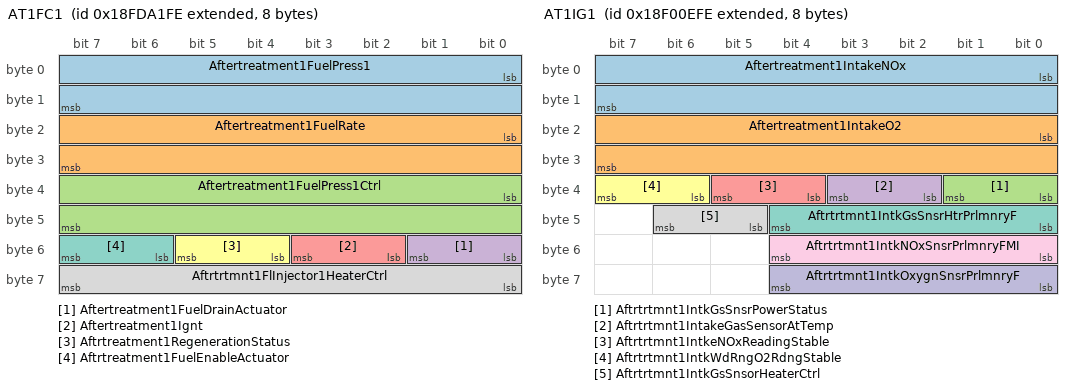
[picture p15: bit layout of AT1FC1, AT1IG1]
BO_ 2566758910 AT1FC1: 8 Vector__XXX
 SG_ Aftertreatment1FuelPress1 : 0|16@1+ (0.1,0) [0|6425.5] "kPa" Vector__XXX
 SG_ Aftertreatment1FuelRate : 16|16@1+ (0.05,0) [0|3212.75] "L/h" Vector__XXX
 SG_ Aftertreatment1FuelPress1Ctrl : 32|16@1+ (1,0) [0|161] "%" Vector__XXX
 SG_ Aftertreatment1FuelDrainActuator : 48|2@1+ (1,0) [0|3] "" Vector__XXX
 SG_ Aftertreatment1Ignt : 50|2@1+ (1,0) [0|3] "" Vector__XXX
 SG_ Aftrtreatment1RegenerationStatus : 52|2@1+ (1,0) [0|3] "" Vector__XXX
 SG_ Aftrtreatment1FuelEnableActuator : 54|2@1+ (1,0) [0|3] "" Vector__XXX
 SG_ Aftrtrtmnt1FlInjector1HeaterCtrl : 56|8@1+ (1,0) [0|100] "%" Vector__XXX

BO_ 2566743550 AT1FC2: 8 Vector__XXX
 SG_ Aftertreatment1FuelPress2 : 0|16@1+ (0.1,0) [0|6425.5] "kPa" Vector__XXX
 SG_ Aftertreatment1FuelPumpRelayCtrl : 16|2@1+ (1,0) [0|3] "" Vector__XXX
 SG_ Aftrtrtmnt1FlFlwDverterValveCtrl : 18|2@1+ (1,0) [0|3] "" Vector__XXX
 SG_ Aftrtrtmnt1FelPress2ActuatorCtrl : 24|16@1+ (1,0) [0|161] "%" Vector__XXX
 SG_ Aftrtrtmnt1HydrcrbnDsrIntkFlTemp : 40|8@1+ (1,-40) [-40|210] "deg C" Vector__XXX

BO_ 2566753534 AT1GP: 8 Vector__XXX
 SG_ DslParticulateFilterIntakePress1 : 0|16@1+ (0.1,0) [0|6425.5] "kPa" Vector__XXX
 SG_ DslParticulateFilterOutletPress1 : 16|16@1+ (0.1,0) [0|6425.5] "kPa" Vector__XXX

BO_ 2565869310 AT1IG1: 8 Vector__XXX
 SG_ Aftertreatment1IntakeNOx : 0|16@1+ (0.05,-200) [-200|3012.75] "ppm" Vector__XXX
 SG_ Aftertreatment1IntakeO2 : 16|16@1+ (0.000514,-12) [-12|21.0271] "%" Vector__XXX
 SG_ Aftrtrtmnt1IntkGsSnsrPowerStatus : 32|2@1+ (1,0) [0|3] "" Vector__XXX
 SG_ Aftrtrtmnt1IntakeGasSensorAtTemp : 34|2@1+ (1,0) [0|3] "" Vector__XXX
 SG_ Aftrtrtmnt1IntkeNOxReadingStable : 36|2@1+ (1,0) [0|3] "" Vector__XXX
 SG_ Aftrtrtmnt1IntkWdRngO2RdngStable : 38|2@1+ (1,0) [0|3] "" Vector__XXX
 SG_ Aftrtrtmnt1IntkGsSnsrHtrPrlmnryF : 40|5@1+ (1,0) [0|31] "" Vector__XXX
 SG_ Aftrtrtmnt1IntkGsSnsorHeaterCtrl : 45|2@1+ (1,0) [0|3] "" Vector__XXX
 SG_ Aftrtrtmnt1IntkNOxSnsrPrlmnryFMI : 48|5@1+ (1,0) [0|31] "" Vector__XXX
 SG_ Aftrtrtmnt1IntkOxygnSnsrPrlmnryF : 56|5@1+ (1,0) [0|31] "" Vector__XXX

BO_ 2566763520 AT1IG2: 8 Vector__XXX
 SG_ Aftrtrtmnt1DslPrtcltFltrIntkGsTm : 16|16@1+ (0.03125,-273) [-273|1734.97] "deg C" Vector__XXX
 SG_ Aftertreatment1ExhaustGasTemp1 : 0|16@1+ (0.03125,-273) [-273|1734.97] "deg C" Vector__XXX
 SG_ Aftrtrtmnt1ExhstGsTmp1PrlmnryFMI : 32|5@1+ (1,0) [0|31] "" Vector__XXX
 SG_ Aftrtrtmnt1DslPrtcltFltrIntkGsTm : 40|5@1+ (1,0) [0|31] "" Vector__XXX

BO_ 2631728894 ATS: 8 Vector__XXX
 SG_ AntitheftPwdValidIndicator : 2|2@1+ (1,0) [0|3] "" Vector__XXX
 SG_ AntitheftModifyPwdStates : 6|2@1+ (1,0) [0|3] "" Vector__XXX
 SG_ AntthftEncryptnSdPrsentIndicator : 0|2@1+ (1,0) [0|3] "" Vector__XXX
 SG_ AntitheftComponentStatusStates : 4|2@1+ (1,0) [0|3] "" Vector__XXX
 SG_ AntitheftRandomNumber : 8|56@1+ (1,0) [0|255] "per byte" Vector__XXX

BO_ 2631794430 ATR: 8 Vector__XXX
 SG_ AntthftEncryptionIndicatorStates : 1|2@1+ (1,0) [0|3] "" Vector__XXX
 SG_ AntitheftDesiredExitModeStates : 3|2@1+ (1,0) [0|3] "" Vector__XXX
 SG_ AntitheftCmdStates : 5|3@1+ (1,0) [0|7] "" Vector__XXX
 SG_ AntitheftPwdRepresentation : 8|56@1+ (1,0) [0|255] "per byte" Vector__XXX

BO_ 2633934846 AT: 8 Vector__XXX
 SG_ EngAltBearing1Temp : 0|8@1+ (1,-40) [-40|210] "deg C" Vector__XXX
 SG_ EngAltBearing2Temp : 8|8@1+ (1,-40) [-40|210] "deg C" Vector__XXX
 SG_ EngAltWinding1Temp : 16|8@1+ (1,-40) [-40|210] "deg C" Vector__XXX
 SG_ EngAltWinding2Temp : 24|8@1+ (1,-40) [-40|210] "deg C" Vector__XXX
 SG_ EngAltWinding3Temp : 32|8@1+ (1,-40) [-40|210] "deg C" Vector__XXX

BO_ 2362572542 ASC6: 8 Vector__XXX
 SG_ LevelPresetFrontAxleLeft : 0|16@1+ (1,-3200) [-3200|3226] "mm" Vector__XXX
 SG_ LevelPresetFrontAxleRight : 16|16@1+ (1,-3200) [-3200|3226] "mm" Vector__XXX
 SG_ LevelPresetRearAxleLeft : 32|16@1+ (1,-3200) [-3200|3226] "mm" Vector__XXX
 SG_ LevelPresetRearAxleRight : 48|16@1+ (1,-3200) [-3200|3226] "mm" Vector__XXX

BO_ 2365478910 ASC5: 8 Vector__XXX
 SG_ DamperStiffnessFrontAxle : 0|8@1+ (1,0) [0|100] "%" Vector__XXX
 SG_ DamperStiffnessRearAxle : 8|8@1+ (1,0) [0|100] "%" Vector__XXX
 SG_ DamperStiffnessLift_TagAxle : 16|8@1+ (1,0) [0|100] "%" Vector__XXX
 SG_ ElctrncShckAbsrbrCtrlMdFrontAxle : 24|2@1+ (1,0) [0|3] "" Vector__XXX
 SG_ ElctrncShckAbsrbrCtrlMdeRearAxle : 26|2@1+ (1,0) [0|3] "" Vector__XXX
 SG_ ElctrncShckAbsrbrCtrlMdLft_TgAxl : 28|2@1+ (1,0) [0|3] "" Vector__XXX

BO_ 2566763262 AT1IMG: 8 Vector__XXX
 SG_ Aftertreatment1ExhaustGasTemp2 : 0|16@1+ (0.03125,-273) [-273|1734.97] "deg C" Vector__XXX
 SG_ Aftrtrtmnt1ExhstGsTmp2PrlmnryFMI : 48|5@1+ (1,0) [0|31] "" Vector__XXX
 SG_ Aftrtrtmnt1DslPrtcltFltrDffPress : 32|16@1+ (0.1,0) [0|6425.5] "kPa" Vector__XXX
 SG_ Aftrtrtmnt1DslPrtcltFltrDltPrssP : 53|5@1+ (1,0) [0|31] "" Vector__XXX
 SG_ Aftrtrtmnt1DslPrtcltFltrIntrmdtG : 16|16@1+ (0.03125,-273) [-273|1734.97] "deg C" Vector__XXX
 SG_ Aftrtrtmnt1DslPrtcltFltrIntrmdtG : 58|5@1+ (1,0) [0|31] "" Vector__XXX

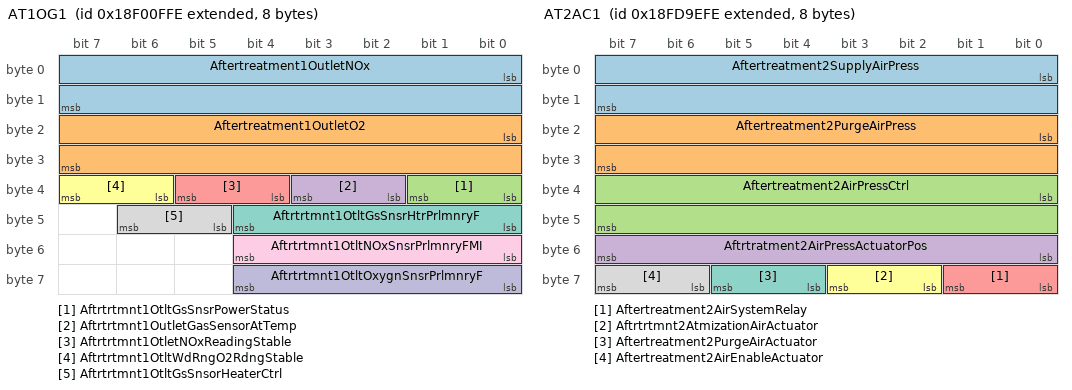
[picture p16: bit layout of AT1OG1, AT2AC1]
BO_ 2565869566 AT1OG1: 8 Vector__XXX
 SG_ Aftertreatment1OutletNOx : 0|16@1+ (0.05,-200) [-200|3012.75] "ppm" Vector__XXX
 SG_ Aftertreatment1OutletO2 : 16|16@1+ (0.000514,-12) [-12|21.0271] "%" Vector__XXX
 SG_ Aftrtrtmnt1OtltGsSnsrPowerStatus : 32|2@1+ (1,0) [0|3] "" Vector__XXX
 SG_ Aftrtrtmnt1OutletGasSensorAtTemp : 34|2@1+ (1,0) [0|3] "" Vector__XXX
 SG_ Aftrtrtmnt1OtletNOxReadingStable : 36|2@1+ (1,0) [0|3] "" Vector__XXX
 SG_ Aftrtrtmnt1OtltWdRngO2RdngStable : 38|2@1+ (1,0) [0|3] "" Vector__XXX
 SG_ Aftrtrtmnt1OtltGsSnsrHtrPrlmnryF : 40|5@1+ (1,0) [0|31] "" Vector__XXX
 SG_ Aftrtrtmnt1OtltGsSnsorHeaterCtrl : 45|2@1+ (1,0) [0|3] "" Vector__XXX
 SG_ Aftrtrtmnt1OtltNOxSnsrPrlmnryFMI : 48|5@1+ (1,0) [0|31] "" Vector__XXX
 SG_ Aftrtrtmnt1OtltOxygnSnsrPrlmnryF : 56|5@1+ (1,0) [0|31] "" Vector__XXX

BO_ 2566763264 AT1OG2: 8 Vector__XXX
 SG_ Aftertreatment1ExhaustGasTemp3 : 0|16@1+ (0.03125,-273) [-273|1734.97] "deg C" Vector__XXX
 SG_ Aftrtrtmnt1ExhstGsTmp3PrlmnryFMI : 32|5@1+ (1,0) [0|31] "" Vector__XXX
 SG_ Aftrtrtmnt1DslPrtcltFltrOtltExhs : 40|5@1+ (1,0) [0|31] "" Vector__XXX
 SG_ Aftrtrtmnt1DslPrtcltFltrOtltGsTm : 16|16@1+ (0.03125,-273) [-273|1734.97] "deg C" Vector__XXX

BO_ 2566748928 AT1S: 8 Vector__XXX
 SG_ Aftrtrtmnt1DslPrtcltFltrStLdRgnr : 48|16@1+ (1,0) [0|161] "%" Vector__XXX
 SG_ DslPrtclteFilter1SootLoadPercent : 0|8@1+ (1,0) [0|250] "%" Vector__XXX
 SG_ DslPrtcltFltr1TmSncLstActvRgnrtn : 16|32@1+ (1,0) [0|4211080000] "s" Vector__XXX
 SG_ DslPrtclateFilter1AshLoadPercent : 8|8@1+ (1,0) [0|250] "%" Vector__XXX

BO_ 2566758142 AT2AC1: 8 Vector__XXX
 SG_ Aftertreatment2SupplyAirPress : 0|16@1+ (0.1,0) [0|6425.5] "kPa" Vector__XXX
 SG_ Aftertreatment2PurgeAirPress : 16|16@1+ (0.1,0) [0|6425.5] "kPa" Vector__XXX
 SG_ Aftertreatment2AirPressCtrl : 32|16@1+ (0.0025,0) [0|160.637] "%" Vector__XXX
 SG_ Aftrtratment2AirPressActuatorPos : 48|8@1+ (0.4,0) [0|100] "%" Vector__XXX
 SG_ Aftertreatment2AirSystemRelay : 56|2@1+ (1,0) [0|3] "" Vector__XXX
 SG_ Aftrtrtmnt2AtmizationAirActuator : 58|2@1+ (1,0) [0|3] "" Vector__XXX
 SG_ Aftertreatment2PurgeAirActuator : 60|2@1+ (1,0) [0|3] "" Vector__XXX
 SG_ Aftertreatment2AirEnableActuator : 62|2@1+ (1,0) [0|3] "" Vector__XXX

BO_ 2566745342 AT2AC2: 8 Vector__XXX
 SG_ Aftrtreatment2SecondAirDiffPress : 0|16@1+ (0.007812,-250) [-250|251.96] "kPa" Vector__XXX
 SG_ Aftertreatment2SecondAirTemp : 16|16@1+ (0.03125,-273) [-273|1734.97] "deg C" Vector__XXX
 SG_ Aftertreatment2SecondAirMassFlow : 32|16@1+ (0.2,0) [0|12851] "kg/h per bit" Vector__XXX
 SG_ Aftertreatment2SecondAirPress : 48|16@1+ (0.1,0) [0|6425.5] "kPa" Vector__XXX

BO_ 2566758654 AT2FC1: 8 Vector__XXX
 SG_ Aftertreatment2FuelPress1 : 0|16@1+ (0.1,0) [0|6425.5] "kPa" Vector__XXX
 SG_ Aftertreatment2FuelRate : 16|16@1+ (0.05,0) [0|3212.75] "L/h" Vector__XXX
 SG_ Aftertreatment2FuelPress1Ctrl : 32|16@1+ (1,0) [0|161] "%" Vector__XXX
 SG_ Aftertreatment2FuelDrainActuator : 48|2@1+ (1,0) [0|3] "" Vector__XXX
 SG_ Aftertreatment2Ignt : 50|2@1+ (1,0) [0|3] "" Vector__XXX
 SG_ Aftrtreatment2RegenerationStatus : 52|2@1+ (1,0) [0|3] "" Vector__XXX
 SG_ Aftrtreatment2FuelEnableActuator : 54|2@1+ (1,0) [0|3] "" Vector__XXX
 SG_ Aftrtrtmnt2FlInjector1HeaterCtrl : 56|8@1+ (1,0) [0|100] "%" Vector__XXX

BO_ 2566753278 AT2GP: 8 Vector__XXX
 SG_ DslParticulateFilterIntakePress2 : 0|16@1+ (0.1,0) [0|6425.5] "kPa" Vector__XXX
 SG_ DslParticulateFilterOutletPress2 : 16|16@1+ (0.1,0) [0|6425.5] "kPa" Vector__XXX

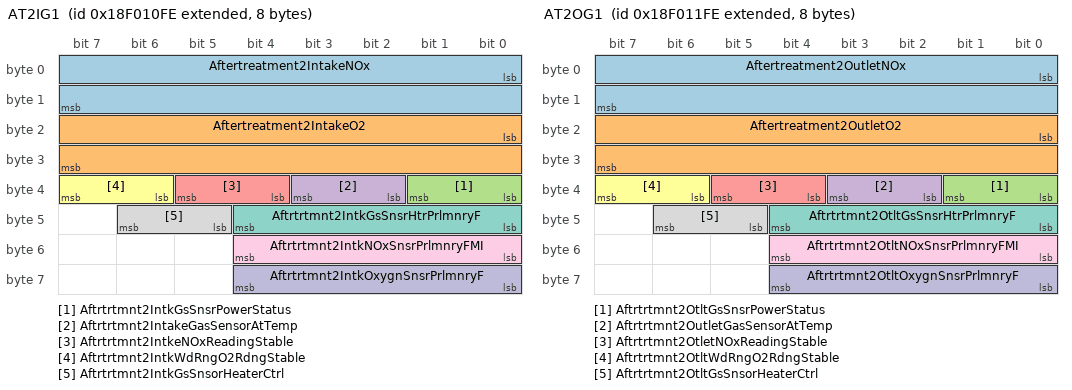
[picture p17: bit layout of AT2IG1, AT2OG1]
BO_ 2565869822 AT2IG1: 8 Vector__XXX
 SG_ Aftertreatment2IntakeNOx : 0|16@1+ (0.05,-200) [-200|3012.75] "ppm" Vector__XXX
 SG_ Aftertreatment2IntakeO2 : 16|16@1+ (0.000514,-12) [-12|21.0271] "%" Vector__XXX
 SG_ Aftrtrtmnt2IntkGsSnsrPowerStatus : 32|2@1+ (1,0) [0|3] "" Vector__XXX
 SG_ Aftrtrtmnt2IntakeGasSensorAtTemp : 34|2@1+ (1,0) [0|3] "" Vector__XXX
 SG_ Aftrtrtmnt2IntkeNOxReadingStable : 36|2@1+ (1,0) [0|3] "" Vector__XXX
 SG_ Aftrtrtmnt2IntkWdRngO2RdngStable : 38|2@1+ (1,0) [0|3] "" Vector__XXX
 SG_ Aftrtrtmnt2IntkGsSnsrHtrPrlmnryF : 40|5@1+ (1,0) [0|31] "" Vector__XXX
 SG_ Aftrtrtmnt2IntkGsSnsorHeaterCtrl : 45|2@1+ (1,0) [0|3] "" Vector__XXX
 SG_ Aftrtrtmnt2IntkNOxSnsrPrlmnryFMI : 48|5@1+ (1,0) [0|31] "" Vector__XXX
 SG_ Aftrtrtmnt2IntkOxygnSnsrPrlmnryF : 56|5@1+ (1,0) [0|31] "" Vector__XXX

BO_ 2566763006 AT2IG2: 8 Vector__XXX
 SG_ Aftrtrtmnt2DslPrtcltFltrIntkGsTm : 16|16@1+ (0.03125,-273) [-273|1734.97] "deg C" Vector__XXX
 SG_ Aftertreatment2ExhaustGasTemp1 : 0|16@1+ (0.03125,-273) [-273|1734.97] "deg C" Vector__XXX
 SG_ Aftrtrtmnt2ExhstGsTmp1PrlmnryFMI : 32|5@1+ (1,0) [0|31] "" Vector__XXX
 SG_ Aftrtrtmnt2DslPrtcltFltrIntkGsTm : 40|5@1+ (1,0) [0|31] "" Vector__XXX

BO_ 2566762494 AT2IMG: 8 Vector__XXX
 SG_ Aftertreatment2ExhaustGasTemp2 : 0|16@1+ (0.03125,-273) [-273|1734.97] "deg C" Vector__XXX
 SG_ Aftrtrtmnt2ExhstGsTmp2PrlmnryFMI : 48|5@1+ (1,0) [0|31] "" Vector__XXX
 SG_ Aftrtrtmnt2DslPrtcltFltrDffPress : 32|16@1+ (0.1,0) [0|6425.5] "kPa" Vector__XXX
 SG_ Aftrtrtmnt2DslPrtcltFltrDltPrssP : 53|5@1+ (1,0) [0|31] "" Vector__XXX
 SG_ Aftrtrtmnt2DslPrtcltFltrIntrmdtG : 16|16@1+ (0.03125,-273) [-273|1734.97] "deg C" Vector__XXX
 SG_ Aftrtrtmnt2DslPrtcltFltrIntrmdtG : 58|5@1+ (1,0) [0|31] "" Vector__XXX

BO_ 2565870078 AT2OG1: 8 Vector__XXX
 SG_ Aftertreatment2OutletNOx : 0|16@1+ (0.05,-200) [-200|3012.75] "ppm" Vector__XXX
 SG_ Aftertreatment2OutletO2 : 16|16@1+ (0.000514,-12) [-12|21.0271] "%" Vector__XXX
 SG_ Aftrtrtmnt2OtltGsSnsrPowerStatus : 32|2@1+ (1,0) [0|3] "" Vector__XXX
 SG_ Aftrtrtmnt2OutletGasSensorAtTemp : 34|2@1+ (1,0) [0|3] "" Vector__XXX
 SG_ Aftrtrtmnt2OtletNOxReadingStable : 36|2@1+ (1,0) [0|3] "" Vector__XXX
 SG_ Aftrtrtmnt2OtltWdRngO2RdngStable : 38|2@1+ (1,0) [0|3] "" Vector__XXX
 SG_ Aftrtrtmnt2OtltGsSnsrHtrPrlmnryF : 40|5@1+ (1,0) [0|31] "" Vector__XXX
 SG_ Aftrtrtmnt2OtltGsSnsorHeaterCtrl : 45|2@1+ (1,0) [0|3] "" Vector__XXX
 SG_ Aftrtrtmnt2OtltNOxSnsrPrlmnryFMI : 48|5@1+ (1,0) [0|31] "" Vector__XXX
 SG_ Aftrtrtmnt2OtltOxygnSnsrPrlmnryF : 56|5@1+ (1,0) [0|31] "" Vector__XXX

BO_ 2566762750 AT2OG2: 8 Vector__XXX
 SG_ Aftertreatment2ExhaustGasTemp3 : 0|16@1+ (0.03125,-273) [-273|1734.97] "deg C" Vector__XXX
 SG_ Aftrtrtmnt2ExhstGsTmp3PrlmnryFMI : 32|5@1+ (1,0) [0|31] "" Vector__XXX
 SG_ Aftrtrtmnt2DslPrtcltFltrExhstGsT : 40|5@1+ (1,0) [0|31] "" Vector__XXX
 SG_ Aftrtrtmnt2DslPrtcltFltrOtltGsTm : 16|16@1+ (0.03125,-273) [-273|1734.97] "deg C" Vector__XXX

BO_ 2566748926 AT2S: 8 Vector__XXX
 SG_ DslPrtclteFilter2SootLoadPercent : 0|8@1+ (1,0) [0|250] "%" Vector__XXX
 SG_ DslPrtclateFilter2AshLoadPercent : 8|8@1+ (1,0) [0|250] "%" Vector__XXX
 SG_ DslPrtcltFltr2TmSncLstActvRgnrtn : 16|32@1+ (1,0) [0|4211080000] "s" Vector__XXX
 SG_ Aftrtrtmnt2DslPrtcltFltrStLdRgnr : 48|16@1+ (1,0) [0|161] "%" Vector__XXX

BO_ 2365428224 EOI: 8 Vector__XXX
 SG_ EngOperatingState : 0|4@1+ (1,0) [0|15] "" Vector__XXX
 SG_ FuelPumpPrimerCtrl : 4|2@1+ (1,0) [0|3] "" Vector__XXX
 SG_ TimeRemainingInEngOperatingState : 8|16@1+ (1,0) [0|64255] "s" Vector__XXX
 SG_ EngFuelShutoffVentCtrl : 24|2@1+ (1,0) [0|3] "" Vector__XXX
 SG_ EngFuelShutoff1Ctrl : 26|2@1+ (1,0) [0|3] "" Vector__XXX
 SG_ EngFuelShutoff2Ctrl : 28|2@1+ (1,0) [0|3] "" Vector__XXX
 SG_ EngFuelShutoffValveLeakTestCtrl : 30|2@1+ (1,0) [0|3] "" Vector__XXX
 SG_ EngOilPrimingPumpCtrl : 32|2@1+ (1,0) [0|3] "" Vector__XXX
 SG_ EngOilPreheaterCtrl : 34|2@1+ (1,0) [0|3] "" Vector__XXX
 SG_ EngElctrclSystmPwrCnsrvationCtrl : 36|2@1+ (1,0) [0|3] "" Vector__XXX
 SG_ EngBlock_CoolantPreheaterCtrl : 38|2@1+ (1,0) [0|3] "" Vector__XXX
 SG_ EngCoolantCirculatingPumpCtrl : 40|2@1+ (1,0) [0|3] "" Vector__XXX
 SG_ EngControlledShutdownRq : 42|2@1+ (1,0) [0|3] "" Vector__XXX
 SG_ EngEmergencyShutdownIndication : 44|2@1+ (1,0) [0|3] "" Vector__XXX
 SG_ EngDerateRq : 56|8@1+ (1,0) [0|100] "%" Vector__XXX
 SG_ EngStarterMotorRelayCtrl : 6|2@1+ (1,0) [0|3] "" Vector__XXX
 SG_ EngColdAmbientElevIdleStatus : 46|2@1+ (1,0) [0|3] "" Vector__XXX
 SG_ EngDesiredTorqReq : 48|8@1+ (1,-125) [-125|130] "%" Vector__XXX

BO_ 2566743806 ET4: 8 Vector__XXX
 SG_ EngCoolantTemp2 : 0|8@1+ (1,-40) [-40|210] "deg C" Vector__XXX
 SG_ EngCoolantPumpOutletTemp : 8|8@1+ (1,-40) [-40|210] "deg C" Vector__XXX
 SG_ EngCoolantThermostatOpening : 16|8@1+ (0.4,0) [0|100] "%" Vector__XXX
 SG_ EngExhstVlvActationSystemOilTemp : 24|16@1+ (0.03125,-273) [-273|1734.97] "deg C" Vector__XXX
 SG_ EngExhstGsRcrcltn1MxerIntakeTemp : 40|16@1+ (0.03125,-273) [-273|1734.97] "deg C" Vector__XXX

BO_ 2499635454 GCVW: 8 Vector__XXX
 SG_ GrossCombinationWeight : 0|24@1+ (1,0) [0|16777200] "kg" Vector__XXX
 SG_ NetVehicleWeightChange : 24|24@1+ (1,-16449500) [-16449500|327715] "kg" Vector__XXX

BO_ 2550660862 GPV4: 8 Vector__XXX
 SG_ ValveLoadSensePress : 0|16@1+ (5,0) [0|321275] "kPa" Vector__XXX
 SG_ ValvePilotPress : 16|8@1+ (16,0) [0|4000] "kPa" Vector__XXX
 SG_ ValveAssemblyLoadSensePress : 24|16@1+ (5,0) [0|321275] "kPa" Vector__XXX
 SG_ ValveAssemblySupplyPress : 40|16@1+ (5,0) [0|321275] "kPa" Vector__XXX

BO_ 2566805758 ASC4: 8 Vector__XXX
 SG_ BellowPressFrontAxleLeft : 0|16@1+ (0.1,0) [0|6425.5] "kPa" Vector__XXX
 SG_ BellowPressFrontAxleRight : 16|16@1+ (0.1,0) [0|6425.5] "kPa" Vector__XXX
 SG_ BellowPressRearAxleLeft : 32|16@1+ (0.1,0) [0|6425.5] "kPa" Vector__XXX
 SG_ BellowPressRearAxleRight : 48|16@1+ (0.1,0) [0|6425.5] "kPa" Vector__XXX

BO_ 2566806014 ASC3: 8 Vector__XXX
 SG_ RelativeLevelFrontAxleLeft : 0|16@1+ (0.1,-3200) [-3200|3225.5] "mm" Vector__XXX
 SG_ RelativeLevelFrontAxleRight : 16|16@1+ (0.1,-3200) [-3200|3225.5] "mm" Vector__XXX
 SG_ RelativeLevelRearAxleLeft : 32|16@1+ (0.1,-3200) [-3200|3225.5] "mm" Vector__XXX
 SG_ RelativeLevelRearAxleRight : 48|16@1+ (0.1,-3200) [-3200|3225.5] "mm" Vector__XXX

BO_ 2362638078 ASC2: 8 Vector__XXX
 SG_ AutomaticTractionHelp : 0|2@1+ (1,0) [0|3] "" Vector__XXX
 SG_ KneelingRqLeftSide : 2|2@1+ (1,0) [0|3] "" Vector__XXX
 SG_ KneelingRqRightSide : 4|2@1+ (1,0) [0|3] "" Vector__XXX
 SG_ KneelingCtrlModeRq : 6|2@1+ (1,0) [0|3] "" Vector__XXX
 SG_ NominalLevelRqFrontAxle : 8|4@1+ (1,0) [0|15] "" Vector__XXX
 SG_ NominalLevelRqRearAxle : 12|4@1+ (1,0) [0|15] "" Vector__XXX
 SG_ LevelCtrlModeRq : 16|4@1+ (1,0) [0|15] "" Vector__XXX
 SG_ LiftAxle1PosCmd : 20|2@1+ (1,0) [0|3] "" Vector__XXX
 SG_ LiftAxle2PosCmd : 22|2@1+ (1,0) [0|3] "" Vector__XXX
 SG_ DamperStiffnessRqFrontAxle : 24|8@1+ (1,0) [0|100] "%" Vector__XXX
 SG_ DamperStiffnessRqRearAxle : 32|8@1+ (1,0) [0|100] "%" Vector__XXX
 SG_ DamperStiffnessRqLift_TagAxle : 40|8@1+ (1,0) [0|100] "%" Vector__XXX
 SG_ KneelingCmdFrontAxle : 48|2@1+ (1,0) [0|3] "" Vector__XXX
 SG_ KneelingCmdRearAxle : 50|2@1+ (1,0) [0|3] "" Vector__XXX
 SG_ ProhibitAirSuspensionCtrl : 52|2@1+ (1,0) [0|3] "" Vector__XXX
 SG_ AllowLevelCtrlDuringBrakingCmd : 54|2@1+ (1,0) [0|3] "" Vector__XXX
 SG_ SpeedDependentLevelCtrlRq : 56|2@1+ (1,0) [0|3] "" Vector__XXX
 SG_ PrhbitAutomaticAirSuspensionCtrl : 58|2@1+ (1,0) [0|3] "" Vector__XXX
 SG_ MemoryLevelRq : 60|4@1+ (1,0) [0|15] "" Vector__XXX

BO_ 2365479678 ASC1: 8 Vector__XXX
 SG_ NominalLevelFrontAxle : 0|4@1+ (1,0) [0|15] "" Vector__XXX
 SG_ NominalLevelRearAxle : 4|4@1+ (1,0) [0|15] "" Vector__XXX
 SG_ BelowNominalLevelFrontAxle : 8|2@1+ (1,0) [0|3] "" Vector__XXX
 SG_ BelowNominalLevelRearAxle : 10|2@1+ (1,0) [0|3] "" Vector__XXX
 SG_ AboveNominalLevelFrontAxle : 12|2@1+ (1,0) [0|3] "" Vector__XXX
 SG_ AboveNominalLevelRearAxle : 14|2@1+ (1,0) [0|3] "" Vector__XXX
 SG_ LoweringCtrlModeFrontAxle : 16|2@1+ (1,0) [0|3] "" Vector__XXX
 SG_ LoweringCtrlModeRearAxle : 18|2@1+ (1,0) [0|3] "" Vector__XXX
 SG_ LiftingCtrlModeFrontAxle : 20|2@1+ (1,0) [0|3] "" Vector__XXX
 SG_ LiftingCtrlModeRearAxle : 22|2@1+ (1,0) [0|3] "" Vector__XXX
 SG_ KneelingInformation : 24|4@1+ (1,0) [0|15] "" Vector__XXX
 SG_ LevelCtrlMode : 28|4@1+ (1,0) [0|15] "" Vector__XXX
 SG_ SecurityDevice : 32|2@1+ (1,0) [0|3] "" Vector__XXX
 SG_ VehicleMotionInhibit : 34|2@1+ (1,0) [0|3] "" Vector__XXX
 SG_ DoorRelease : 36|2@1+ (1,0) [0|3] "" Vector__XXX
 SG_ LiftAxle1Pos : 38|2@1+ (1,0) [0|3] "" Vector__XXX
 SG_ FrontAxleInBumperRange : 40|2@1+ (1,0) [0|3] "" Vector__XXX
 SG_ RearAxleInBumperRange : 42|2@1+ (1,0) [0|3] "" Vector__XXX
 SG_ LiftAxle2Pos : 46|2@1+ (1,0) [0|3] "" Vector__XXX
 SG_ SuspensionRemoteCtrl1 : 48|2@1+ (1,0) [0|3] "" Vector__XXX
 SG_ SuspensionRemoteCtrl2 : 50|2@1+ (1,0) [0|3] "" Vector__XXX
 SG_ AllwLevelCtrlDuringBrakingStatus : 52|2@1+ (1,0) [0|3] "" Vector__XXX
 SG_ SpeedDependantLevelCtrlStatus : 54|2@1+ (1,0) [0|3] "" Vector__XXX
 SG_ SuspensionCtrlRefusalInformation : 56|4@1+ (1,0) [0|15] "" Vector__XXX
 SG_ MemoryLevel : 60|4@1+ (1,0) [0|15] "" Vector__XXX

BO_ 2566837758 AS: 8 Vector__XXX
 SG_ AltSpeed : 0|16@1+ (0.5,0) [0|32127.5] "rpm" Vector__XXX
 SG_ Alt1Status : 16|2@1+ (1,0) [0|3] "" Vector__XXX
 SG_ Alt2Status : 18|2@1+ (1,0) [0|3] "" Vector__XXX
 SG_ Alt3Status : 20|2@1+ (1,0) [0|3] "" Vector__XXX
 SG_ Alt4Status : 22|2@1+ (1,0) [0|3] "" Vector__XXX

BO_ 2633922558 AP: 8 Vector__XXX
 SG_ AuxVacuumPressReading : 0|16@1+ (0.5,0) [0|32127.5] "kPa" Vector__XXX
 SG_ AuxGagePressReading1 : 16|16@1+ (0.5,0) [0|32127.5] "kPa" Vector__XXX
 SG_ AuxAbsPressReading : 32|16@1+ (0.5,0) [0|32127.5] "kPa" Vector__XXX

BO_ 2566775038 AMB2: 8 Vector__XXX
 SG_ SolarIntensityPercent : 0|8@1+ (0.4,0) [0|100] "%" Vector__XXX
 SG_ SolarSensorMax : 8|8@1+ (1,0) [0|100] "mW/cm^2" Vector__XXX
 SG_ SpecificHumidity : 16|16@1+ (0.01,0) [0|642.55] "g/kg" Vector__XXX

BO_ 2566836478 DM8: 8 Vector__XXX
 SG_ TestIdentifier : 0|8@1+ (1,0) [1|64] "" Vector__XXX
 SG_ TestType : 8|8@1+ (1,0) [1|64] "" Vector__XXX
 SG_ TestValue : 16|16@1+ (1,0) [0|64255] "" Vector__XXX
 SG_ TestLimitMaximum : 32|16@1+ (1,0) [0|64255] "" Vector__XXX
 SG_ TestLimitMinimum : 48|16@1+ (1,0) [0|64255] "" Vector__XXX

BO_ 2565078782 DM7: 8 Vector__XXX
 SG_ FailureModeIdentifier1 : 24|5@1+ (1,0) [0|31] "" Vector__XXX
 SG_ TestIdentifier : 0|8@1+ (1,0) [1|64] "" Vector__XXX
 SG_ SPN1 : 8|16@1+ (1,0) [0|65535] "" Vector__XXX
 SG_ SPN1High : 29|3@1+ (1,0) [0|7] "" Vector__XXX

BO_ 2566835966 DM5: 8 Vector__XXX
 SG_ FuelSystemMonitoringSupport : 25|1@1- (1,0) [0|1] "" Vector__XXX
 SG_ ComprehensiveComponentMonSupp : 26|1@1- (1,0) [0|1] "" Vector__XXX
 SG_ FuelSystemMonitoringStatus : 29|1@1- (1,0) [0|1] "" Vector__XXX
 SG_ ComprehensiveCompMonStatus : 30|1@1- (1,0) [0|1] "" Vector__XXX
 SG_ MisfireMonitoringStatus : 28|1@1- (1,0) [0|1] "" Vector__XXX
 SG_ EGRSystemMonitoringSupp : 39|1@1- (1,0) [0|1] "" Vector__XXX
 SG_ OxygenSensorHeaterMonSupp : 38|1@1- (1,0) [0|1] "" Vector__XXX
 SG_ OxygenSensorMonSupp : 37|1@1- (1,0) [0|1] "" Vector__XXX
 SG_ ACSystemRefrigerantMonSupp : 36|1@1- (1,0) [0|1] "" Vector__XXX
 SG_ SecondAirSystemMonSupp : 35|1@1- (1,0) [0|1] "" Vector__XXX
 SG_ EvaporativeSystemMonSupp : 34|1@1- (1,0) [0|1] "" Vector__XXX
 SG_ HeatedCatalystMonSupp : 33|1@1- (1,0) [0|1] "" Vector__XXX
 SG_ ColdStartAidSystemMonSupp : 40|1@1- (1,0) [0|1] "" Vector__XXX
 SG_ CatalystMonSupp : 32|1@1- (1,0) [0|1] "" Vector__XXX
 SG_ HeatedCatalystMonStatus : 49|1@1- (1,0) [0|1] "" Vector__XXX
 SG_ ColdStartAidSystemMonStatus : 56|1@1- (1,0) [0|1] "" Vector__XXX
 SG_ CatalystMonStatus : 48|1@1- (1,0) [0|1] "" Vector__XXX
 SG_ EGRSystemMonitoringStatus : 55|1@1- (1,0) [0|1] "" Vector__XXX
 SG_ OxygenSensorMonStatus : 53|1@1- (1,0) [0|1] "" Vector__XXX
 SG_ OxygenSensorHeaterMonStatus : 54|1@1- (1,0) [0|1] "" Vector__XXX
 SG_ ACSystemRefrigerantMonStatus : 52|1@1- (1,0) [0|1] "" Vector__XXX
 SG_ EvaporativeSystemMonStatus : 50|1@1- (1,0) [0|1] "" Vector__XXX
 SG_ SecondAirSystemMonStatus : 51|1@1- (1,0) [0|1] "" Vector__XXX
 SG_ ActiveTroubleCodes : 0|8@1+ (1,0) [0|240] "" Vector__XXX
 SG_ PreviouslyActiveTroubleCodes : 8|8@1+ (1,0) [0|240] "" Vector__XXX
 SG_ OBDCompliance : 16|8@1+ (1,0) [0|240] "" Vector__XXX
 SG_ MisfireMonitoringSupport : 24|1@1- (1,0) [0|1] "" Vector__XXX
 SG_ NMHCConvertingCatalystSupport : 44|1@1- (1,0) [0|1] "" Vector__XXX
 SG_ NOxConvertingCatalystAdsorberSup : 43|1@1- (1,0) [0|1] "" Vector__XXX
 SG_ DieselParticulateFilterSupport : 42|1@1- (1,0) [0|1] "" Vector__XXX
 SG_ BoostPressureControlSystemSuppor : 41|1@1- (1,0) [0|1] "" Vector__XXX
 SG_ NMHCConvertingCatalystStatus : 60|1@1- (1,0) [0|1] "" Vector__XXX
 SG_ NOxConvertingCatalystAdsorberSta : 59|1@1- (1,0) [0|1] "" Vector__XXX
 SG_ DieselParticulateFilterStatus : 58|1@1- (1,0) [0|1] "" Vector__XXX
 SG_ BoostPressureControlSystemStatus : 57|1@1- (1,0) [0|1] "" Vector__XXX

BO_ 2566835454 DM3: 0 Vector__XXX

BO_ 2562981630 DM22: 8 Vector__XXX
 SG_ FailureModeIdentifier1 : 56|5@1+ (1,0) [0|31] "" Vector__XXX
 SG_ SPN1High : 61|3@1+ (1,0) [0|7] "" Vector__XXX
 SG_ SPN1 : 40|16@1+ (1,0) [0|65535] "" Vector__XXX
 SG_ CtrlByteIndicIndividualDTCClear : 8|8@1+ (1,0) [0|255] "" Vector__XXX
 SG_ IndividualDTCClearControlByte : 0|8@1+ (1,0) [0|255] "" Vector__XXX

BO_ 2562850558 DM21: 8 Vector__XXX
 SG_ DistanceWhileMILisActivated : 0|16@1+ (1,0) [0|64255] "km" Vector__XXX
 SG_ DistanceSinceDTCsCleared : 16|16@1+ (1,0) [0|64255] "km" Vector__XXX
 SG_ MinutesRunByEngineMILActivated : 32|16@1+ (1,0) [0|64255] "mins" Vector__XXX
 SG_ TimeSinceDTCsCleared : 48|16@1+ (1,0) [0|64255] "mins" Vector__XXX

BO_ 2564226814 DM17: 8 Vector__XXX
 SG_ BootLoadData : 0|8@1- (1,0) [-128|127] "" Vector__XXX
 SG_ BootLoadData1 : 8|8@1- (1,0) [-128|127] "" Vector__XXX
 SG_ BootLoadData2 : 16|8@1- (1,0) [-128|127] "" Vector__XXX
 SG_ BootLoadData3 : 24|8@1- (1,0) [-128|127] "" Vector__XXX
 SG_ BootLoadData4 : 32|8@1- (1,0) [-128|127] "" Vector__XXX
 SG_ BootLoadData5 : 40|8@1- (1,0) [-128|127] "" Vector__XXX
 SG_ BootLoadData6 : 48|8@1- (1,0) [-128|127] "" Vector__XXX
 SG_ BootLoadData7 : 56|8@1- (1,0) [-128|127] "" Vector__XXX

BO_ 2564292350 DM16: 8 Vector__XXX
 SG_ NumberOfOccurance : 0|8@1+ (1,0) [0|255] "" Vector__XXX
 SG_ RawBinaryData : 8|8@1- (1,0) [-128|127] "" Vector__XXX
 SG_ RawBinaryData1 : 16|8@1- (1,0) [-128|127] "" Vector__XXX
 SG_ RawBinaryData2 : 24|8@1- (1,0) [-128|127] "" Vector__XXX
 SG_ RawBinaryData3 : 32|8@1- (1,0) [-128|127] "" Vector__XXX
 SG_ RawBinaryData4 : 40|8@1- (1,0) [-128|127] "" Vector__XXX
 SG_ RawBinaryData5 : 48|8@1- (1,0) [-128|127] "" Vector__XXX
 SG_ RawBinaryData6 : 56|8@1- (1,0) [-128|127] "" Vector__XXX

BO_ 2564357886 DM15: 8 Vector__XXX
 SG_ NumberAllowedHigh : 13|3@1+ (1,0) [0|7] "" Vector__XXX
 SG_ Status : 9|3@1+ (1,0) [0|7] "" Vector__XXX
 SG_ ErrorIndicator : 16|24@1+ (1,0) [0|16777200] "" Vector__XXX
 SG_ EDCP_Extension : 40|8@1+ (1,0) [0|255] "" Vector__XXX
 SG_ Seed : 48|16@1+ (1,0) [0|65535] "" Vector__XXX
 SG_ NumberAllowed : 0|8@1+ (1,0) [0|255] "" Vector__XXX

BO_ 2564423422 DM14: 8 Vector__XXX
 SG_ NumberRequestedHigh : 13|3@1+ (1,0) [0|7] "" Vector__XXX
 SG_ NumberRequested : 0|8@1+ (1,0) [0|255] "" Vector__XXX
 SG_ PointerType : 12|1@1- (1,0) [0|1] "" Vector__XXX
 SG_ Command : 9|3@1+ (1,0) [0|7] "" Vector__XXX
 SG_ Pointer : 16|24@1+ (1,0) [0|16777200] "" Vector__XXX
 SG_ PointerExtension : 40|8@1+ (1,0) [0|255] "" Vector__XXX
 SG_ KeyOrUserLevel : 48|16@1+ (1,0) [0|65535] "" Vector__XXX

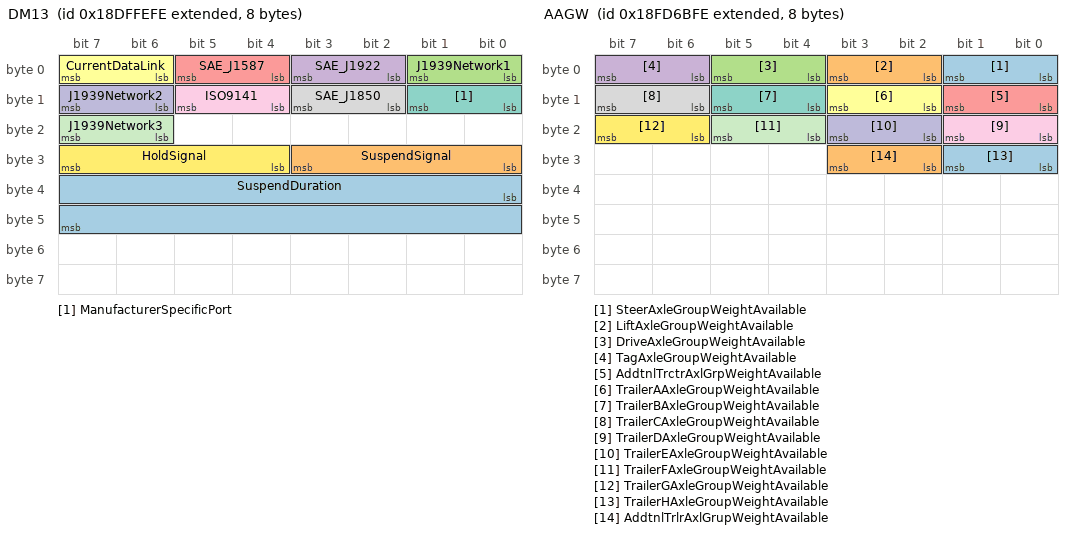
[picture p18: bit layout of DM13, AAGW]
BO_ 2564816638 DM13: 8 Vector__XXX
 SG_ SuspendDuration : 32|16@1+ (1,0) [0|64255] "sec" Vector__XXX
 SG_ SuspendSignal : 24|4@1+ (1,0) [0|15] "" Vector__XXX
 SG_ J1939Network1 : 0|2@1+ (1,0) [0|3] "" Vector__XXX
 SG_ SAE_J1922 : 2|2@1+ (1,0) [0|3] "" Vector__XXX
 SG_ SAE_J1587 : 4|2@1+ (1,0) [0|3] "" Vector__XXX
 SG_ CurrentDataLink : 6|2@1+ (1,0) [0|3] "" Vector__XXX
 SG_ ManufacturerSpecificPort : 8|2@1+ (1,0) [0|3] "" Vector__XXX
 SG_ SAE_J1850 : 10|2@1+ (1,0) [0|3] "" Vector__XXX
 SG_ ISO9141 : 12|2@1+ (1,0) [0|3] "" Vector__XXX
 SG_ J1939Network2 : 14|2@1+ (1,0) [0|3] "" Vector__XXX
 SG_ J1939Network3 : 22|2@1+ (1,0) [0|3] "" Vector__XXX
 SG_ HoldSignal : 28|4@1+ (1,0) [0|15] "" Vector__XXX

BO_ 2566837246 DM11: 0 Vector__XXX

BO_ 2566836990 DM10: 8 Vector__XXX
 SG_ TestIdentifierSupported : 0|64@1+ (1,0) [1|9.22337E+018] "" Vector__XXX

BO_ 2566780926 UTACR: 8 Vector__XXX
 SG_ UtilityTotalReactivePower : 0|32@1+ (1,-2000000000) [-2000000000|2211080000] "VAr" Vector__XXX
 SG_ UtilityOverallPowerFactor : 32|16@1+ (1,-1) [-1|3] "" Vector__XXX
 SG_ UtlityOverallPowerFactorLagging : 48|2@1+ (1,0) [0|3] "" Vector__XXX

BO_ 2566781182 UTACP: 8 Vector__XXX
 SG_ UtilityTotalRealPower : 0|32@1+ (1,-2000000000) [-2000000000|2211080000] "W" Vector__XXX
 SG_ UtilityTotalApparentPower : 32|32@1+ (1,-2000000000) [-2000000000|2211080000] "VA" Vector__XXX

BO_ 2566778366 UTACE: 8 Vector__XXX
 SG_ UtilityTotalKWHoursExport : 0|32@1+ (1,0) [0|4211080000] "kWh" Vector__XXX
 SG_ UtilityTotalKWHoursImport : 32|32@1+ (1,0) [0|4211080000] "kWh" Vector__XXX

BO_ 2566778622 UPCACR: 8 Vector__XXX
 SG_ UtilityPhaseCReactivePower : 0|32@1+ (1,-2000000000) [-2000000000|2211080000] "VAr" Vector__XXX
 SG_ UtilityPhaseCPowerFactor : 32|16@1+ (1,-1) [-1|3] "" Vector__XXX
 SG_ UtilityPhaseCPowerFactorLagging : 48|2@1+ (1,0) [0|3] "" Vector__XXX

BO_ 2566778878 UPCACP: 8 Vector__XXX
 SG_ UtilityPhaseCRealPower : 0|32@1+ (1,-2000000000) [-2000000000|2211080000] "W" Vector__XXX
 SG_ UtilityPhaseCApparentPower : 32|32@1+ (1,-2000000000) [-2000000000|2211080000] "VA" Vector__XXX

BO_ 2566779134 UPCAC: 8 Vector__XXX
 SG_ UtltyPhseCALineLineACRMSVoltage : 0|16@1+ (1,0) [0|64255] "V" Vector__XXX
 SG_ UtltyPhsCLneNeutralACRMSVoltage : 16|16@1+ (1,0) [0|64255] "V" Vector__XXX
 SG_ UtilityPhaseCACFrequency : 32|16@1+ (1,0) [0|502] "Hz" Vector__XXX
 SG_ UtilityPhaseCACRMSCurrent : 48|16@1+ (1,0) [0|64255] "A" Vector__XXX

BO_ 2566779390 UPBACR: 8 Vector__XXX
 SG_ UtilityPhaseBReactivePower : 0|32@1+ (1,-2000000000) [-2000000000|2211080000] "VAr" Vector__XXX
 SG_ UtilityPhaseBPowerFactor : 32|16@1+ (1,-1) [-1|3] "" Vector__XXX
 SG_ UtilityPhaseBPowerFactorLagging : 48|2@1+ (1,0) [0|3] "" Vector__XXX

BO_ 2566779646 UPBACP: 8 Vector__XXX
 SG_ UtilityPhaseBRealPower : 0|32@1+ (1,-2000000000) [-2000000000|2211080000] "W" Vector__XXX
 SG_ UtilityPhaseBApparentPower : 32|32@1+ (1,-2000000000) [-2000000000|2211080000] "VA" Vector__XXX

BO_ 2566779902 UPBAC: 8 Vector__XXX
 SG_ UtltyPhseBCLineLineACRMSVoltage : 0|16@1+ (1,0) [0|64255] "V" Vector__XXX
 SG_ UtltyPhsBLneNeutralACRMSVoltage : 16|16@1+ (1,0) [0|64255] "V" Vector__XXX
 SG_ UtilityPhaseBACFrequency : 32|16@1+ (1,0) [0|502] "Hz" Vector__XXX
 SG_ UtilityPhaseBACRMSCurrent : 48|16@1+ (1,0) [0|64255] "A" Vector__XXX

BO_ 2566780158 UPACCR: 8 Vector__XXX
 SG_ UtilityPhaseAReactivePower : 0|32@1+ (1,-2000000000) [-2000000000|2211080000] "VAr" Vector__XXX
 SG_ UtilityPhaseAPowerFactor : 32|16@1+ (1,-1) [-1|3] "" Vector__XXX
 SG_ UtilityPhaseAPowerFactorLagging : 48|2@1+ (1,0) [0|3] "" Vector__XXX

BO_ 2566780414 UPAACP: 8 Vector__XXX
 SG_ UtilityPhaseARealPower : 0|32@1+ (1,-2000000000) [-2000000000|2211080000] "W" Vector__XXX
 SG_ UtilityPhaseAApparentPower : 32|32@1+ (1,-2000000000) [-2000000000|2211080000] "VA" Vector__XXX

BO_ 2566780670 UPAAC: 8 Vector__XXX
 SG_ UtltyPhseABLineLineACRMSVoltage : 0|16@1+ (1,0) [0|64255] "V" Vector__XXX
 SG_ UtltyPhsALneNeutralACRMSVoltage : 16|16@1+ (1,0) [0|64255] "V" Vector__XXX
 SG_ UtilityPhaseAACFrequency : 32|16@1+ (1,0) [0|502] "Hz" Vector__XXX
 SG_ UtilityPhaseAACRMSCurrent : 48|16@1+ (1,0) [0|64255] "A" Vector__XXX

BO_ 2566781438 UAAC: 8 Vector__XXX
 SG_ UtltyAvrageLineLineACRMSVoltage : 0|16@1+ (1,0) [0|64255] "V" Vector__XXX
 SG_ UtltyAvrgLneNeutralACRMSVoltage : 16|16@1+ (1,0) [0|64255] "V" Vector__XXX
 SG_ UtilityAverageACFrequency : 32|16@1+ (1,0) [0|502] "Hz" Vector__XXX
 SG_ UtilityAverageACRMSCurrent : 48|16@1+ (1,0) [0|64255] "A" Vector__XXX

BO_ 2566784254 GTACR: 8 Vector__XXX
 SG_ GeneratorTotalReactivePower : 0|32@1+ (1,-2000000000) [-2000000000|2211080000] "VAr" Vector__XXX
 SG_ GeneratorOverallPowerFactor : 32|16@1+ (1,-1) [-1|3] "" Vector__XXX
 SG_ GnrtorOverallPowerFactorLagging : 48|2@1+ (1,0) [0|3] "" Vector__XXX

BO_ 2566784510 GTACP: 8 Vector__XXX
 SG_ GeneratorTotalRealPower : 0|32@1+ (1,-2000000000) [-2000000000|2211080000] "W" Vector__XXX
 SG_ GeneratorTotalApparentPower : 32|32@1+ (1,-2000000000) [-2000000000|2211080000] "VA" Vector__XXX

BO_ 2566781694 GTACE: 8 Vector__XXX
 SG_ GeneratorTotalKWHoursExport : 0|32@1+ (1,0) [0|4211080000] "kWh" Vector__XXX
 SG_ GeneratorTotalKWHoursImport : 32|32@1+ (1,0) [0|4211080000] "kWh" Vector__XXX

BO_ 2566781950 GPCACR: 8 Vector__XXX
 SG_ GeneratorPhaseCReactivePower : 0|32@1+ (1,-2000000000) [-2000000000|2211080000] "VAr" Vector__XXX
 SG_ GeneratorPhaseCPowerFactor : 32|16@1+ (1,-1) [-1|3] "" Vector__XXX
 SG_ GnratorPhaseCPowerFactorLagging : 48|2@1+ (1,0) [0|3] "" Vector__XXX

BO_ 2566782206 GPCACP: 8 Vector__XXX
 SG_ GeneratorPhaseCRealPower : 0|32@1+ (1,-2000000000) [-2000000000|2211080000] "W" Vector__XXX
 SG_ GeneratorPhaseCApparentPower : 32|32@1+ (1,-2000000000) [-2000000000|2211080000] "VA" Vector__XXX

BO_ 2566782462 GPCAC: 8 Vector__XXX
 SG_ GnrtrPhseCALineLineACRMSVoltage : 0|16@1+ (1,0) [0|64255] "V" Vector__XXX
 SG_ GnrtrPhsCLneNeutralACRMSVoltage : 16|16@1+ (1,0) [0|64255] "V" Vector__XXX
 SG_ GeneratorPhaseCACFrequency : 32|16@1+ (1,0) [0|502] "Hz" Vector__XXX
 SG_ GeneratorPhaseCACRMSCurrent : 48|16@1+ (1,0) [0|64255] "A" Vector__XXX

BO_ 2566782718 GPBACRP: 8 Vector__XXX
 SG_ GeneratorPhaseBReactivePower : 0|32@1+ (1,-2000000000) [-2000000000|2211080000] "VAr" Vector__XXX
 SG_ GeneratorPhaseBPowerFactor : 32|16@1+ (1,-1) [-1|3] "" Vector__XXX
 SG_ GnratorPhaseBPowerFactorLagging : 48|2@1+ (1,0) [0|3] "" Vector__XXX

BO_ 2566782974 GPBACP: 8 Vector__XXX
 SG_ GeneratorPhaseBRealPower : 0|32@1+ (1,-2000000000) [-2000000000|2211080000] "W" Vector__XXX
 SG_ GeneratorPhaseBApparentPower : 32|32@1+ (1,-2000000000) [-2000000000|2211080000] "VA" Vector__XXX

BO_ 2566783230 GPBAC: 8 Vector__XXX
 SG_ GnrtrPhseBCLineLineACRMSVoltage : 0|16@1+ (1,0) [0|64255] "V" Vector__XXX
 SG_ GnrtrPhsBLneNeutralACRMSVoltage : 16|16@1+ (1,0) [0|64255] "V" Vector__XXX
 SG_ GeneratorPhaseBACFrequency : 32|16@1+ (1,0) [0|502] "Hz" Vector__XXX
 SG_ GeneratorPhaseBACRMSCurrent : 48|16@1+ (1,0) [0|64255] "A" Vector__XXX

BO_ 2566783486 GPAACR: 8 Vector__XXX
 SG_ GeneratorPhaseAReactivePower : 0|32@1+ (1,-2000000000) [-2000000000|2211080000] "VAr" Vector__XXX
 SG_ GeneratorPhaseAPowerFactor : 32|16@1+ (1,-1) [-1|3] "" Vector__XXX
 SG_ GnratorPhaseAPowerFactorLagging : 48|2@1+ (1,0) [0|3] "" Vector__XXX

BO_ 2566783742 GPAACP: 8 Vector__XXX
 SG_ GeneratorPhaseARealPower : 0|32@1+ (1,-2000000000) [-2000000000|2211080000] "W" Vector__XXX
 SG_ GeneratorPhaseAApparentPower : 32|32@1+ (1,-2000000000) [-2000000000|2211080000] "VA" Vector__XXX

BO_ 2566783998 GPAAC: 8 Vector__XXX
 SG_ GnrtrPhseABLineLineACRMSVoltage : 0|16@1+ (1,0) [0|64255] "V" Vector__XXX
 SG_ GnrtrPhsALneNeutralACRMSVoltage : 16|16@1+ (1,0) [0|64255] "V" Vector__XXX
 SG_ GeneratorPhaseAACFrequency : 32|16@1+ (1,0) [0|502] "Hz" Vector__XXX
 SG_ GeneratorPhaseAACRMSCurrent : 48|16@1+ (1,0) [0|64255] "A" Vector__XXX

BO_ 2566784766 GAAC: 8 Vector__XXX
 SG_ GnrtrAvrageLineLineACRMSVoltage : 0|16@1+ (1,0) [0|64255] "V" Vector__XXX
 SG_ GnrtrAvrgLneNeutralACRMSVoltage : 16|16@1+ (1,0) [0|64255] "V" Vector__XXX
 SG_ GeneratorAverageACFrequency : 32|16@1+ (1,0) [0|502] "Hz" Vector__XXX
 SG_ GeneratorAverageACRMSCurrent : 48|16@1+ (1,0) [0|64255] "A" Vector__XXX

BO_ 2566776830 BUSC: 8 Vector__XXX
 SG_ Bus1_UtilityDeadBus : 0|2@1+ (1,0) [0|3] "" Vector__XXX
 SG_ Bus1_UtilityPhaseMatch : 2|2@1+ (1,0) [0|3] "" Vector__XXX
 SG_ Bus1_UtilityFrequencyMatch : 4|2@1+ (1,0) [0|3] "" Vector__XXX
 SG_ Bus1_UtilityVoltageMatch : 6|2@1+ (1,0) [0|3] "" Vector__XXX
 SG_ Bus1_UtilityInSync : 8|2@1+ (1,0) [0|3] "" Vector__XXX
 SG_ Bus1_UtilityACPhaseDifference : 16|16@1+ (1,-200) [-200|302] "deg" Vector__XXX

BO_ 2566777342 BPCAC: 8 Vector__XXX
 SG_ Bus1PhaseCALineLineACRMSVoltage : 0|16@1+ (1,0) [0|64255] "V" Vector__XXX
 SG_ Bs1PhseCLineNeutralACRMSVoltage : 16|16@1+ (1,0) [0|64255] "V" Vector__XXX
 SG_ Bus1PhaseCACFrequency : 32|16@1+ (1,0) [0|502] "Hz" Vector__XXX

BO_ 2566777598 BPBAC: 8 Vector__XXX
 SG_ Bus1PhaseBCLineLineACRMSVoltage : 0|16@1+ (1,0) [0|64255] "V" Vector__XXX
 SG_ Bs1PhseBLineNeutralACRMSVoltage : 16|16@1+ (1,0) [0|64255] "V" Vector__XXX
 SG_ Bus1PhaseBACFrequency : 32|16@1+ (1,0) [0|502] "Hz" Vector__XXX

BO_ 2566777854 BPAAC: 8 Vector__XXX
 SG_ Bus1PhaseABLineLineACRMSVoltage : 0|16@1+ (1,0) [0|64255] "V" Vector__XXX
 SG_ Bs1PhseALineNeutralACRMSVoltage : 16|16@1+ (1,0) [0|64255] "V" Vector__XXX
 SG_ Bus1PhaseAACFrequency : 32|16@1+ (1,0) [0|502] "Hz" Vector__XXX

BO_ 2566777086 BGSC: 8 Vector__XXX
 SG_ Bus1_GeneratorDeadBus : 0|2@1+ (1,0) [0|3] "" Vector__XXX
 SG_ Bus1_GeneratorPhaseMatch : 2|2@1+ (1,0) [0|3] "" Vector__XXX
 SG_ Bus1_GeneratorFrequencyMatch : 4|2@1+ (1,0) [0|3] "" Vector__XXX
 SG_ Bus1_GeneratorVoltageMatch : 6|2@1+ (1,0) [0|3] "" Vector__XXX
 SG_ Bus1_GeneratorInSync : 8|2@1+ (1,0) [0|3] "" Vector__XXX
 SG_ Bus1_GeneratorACPhaseDifference : 16|16@1+ (1,-200) [-200|302] "deg" Vector__XXX

BO_ 2566778110 BAAC: 8 Vector__XXX
 SG_ Bus1AverageLineLineACRMSVoltage : 0|16@1+ (1,0) [0|64255] "V" Vector__XXX
 SG_ Bs1AvrgeLineNeutralACRMSVoltage : 16|16@1+ (1,0) [0|64255] "V" Vector__XXX
 SG_ Bus1AverageACFrequency : 32|16@1+ (1,0) [0|502] "Hz" Vector__XXX

BO_ 2633895422 WSMSTR: 8 Vector__XXX
 SG_ NumberOfMembers : 0|8@1+ (1,0) [0|255] "" Vector__XXX

BO_ 2565799678 ACL: 8 Vector__XXX
 SG_ VehicleSystem1 : 49|7@1+ (1,0) [0|127] "" Vector__XXX
 SG_ VehicleSystem2 : 49|7@1+ (1,0) [0|127] "" Vector__XXX
 SG_ VehicleSystem3 : 49|7@1+ (1,0) [0|127] "" Vector__XXX
 SG_ VehicleSystem4 : 49|7@1+ (1,0) [0|127] "" Vector__XXX
 SG_ VehicleSystem5 : 49|7@1+ (1,0) [0|127] "" Vector__XXX
 SG_ VehicleSystem : 49|7@1+ (1,0) [0|127] "" Vector__XXX
 SG_ IdentityNumber : 0|21@1+ (1,0) [0|2097150] "" Vector__XXX
 SG_ ManufacturerCode : 21|11@1+ (1,0) [0|2047] "" Vector__XXX
 SG_ ECUInstance : 32|3@1+ (1,0) [0|7] "" Vector__XXX
 SG_ FunctionInstance : 35|5@1+ (1,0) [0|31] "" Vector__XXX
 SG_ Function : 40|8@1+ (1,0) [0|255] "" Vector__XXX
 SG_ VehicleSystemInstance : 56|4@1+ (1,0) [0|15] "" Vector__XXX
 SG_ IndustryGroup : 60|3@1+ (1,0) [0|7] "" Vector__XXX
 SG_ ArbitraryAddressCapable : 63|1@1- (1,0) [0|1] "" Vector__XXX

BO_ 2563440382 XFER: 8 Vector__XXX
 SG_ PGNofRequstedInformation : 0|24@1+ (1,0) [0|16777200] "" Vector__XXX
 SG_ LengthOfDataForTheReportedPGN : 24|8@1+ (1,0) [0|255] "" Vector__XXX
 SG_ ShrtNameOfActualReportingDevice : 32|32@1+ (1,0) [0|2704] "(2^32 - 1)" Vector__XXX

BO_ 2632711934 TPDT: 8 Vector__XXX
 SG_ SequenceNumber : 0|8@1+ (1,0) [0|255] "" Vector__XXX

BO_ 2632777470 TPCM: 8 Vector__XXX
 SG_ ControlByte : 0|8@1+ (1,0) [0|255] "" Vector__XXX
 SG_ TotalMessageSize : 8|16@1+ (1,0) [0|64255] "counts" Vector__XXX
 SG_ TotalNumberOfPackets : 24|8@1+ (1,0) [0|255] "" Vector__XXX
 SG_ MaximumNumberOfPackets : 32|8@1+ (1,0) [0|255] "" Vector__XXX
 SG_ PGNumber : 40|24@1+ (1,0) [0|16777200] "" Vector__XXX
 SG_ NumberOfPacketsThatCanBeSent : 8|8@1+ (1,0) [0|255] "" Vector__XXX
 SG_ NextPacketNumberToBeSent : 16|8@1+ (1,0) [0|255] "" Vector__XXX
 SG_ ConnectionAbortReason : 8|8@1+ (1,0) [0|255] "" Vector__XXX
 SG_ TotalNumberOfPacketsBAM : 24|8@1+ (1,0) [0|255] "" Vector__XXX
 SG_ TotalMessageSizeBAM : 8|16@1+ (1,0) [0|64255] "counts" Vector__XXX
 SG_ TotalMessageSizeEoMA : 8|16@1+ (1,0) [0|64255] "counts" Vector__XXX
 SG_ TotalNumberOfPacketsEoMA : 24|8@1+ (1,0) [0|255] "" Vector__XXX

BO_ 2563374846 RQST2: 8 Vector__XXX
 SG_ ParameterGroupNumber : 0|24@1+ (1,0) [0|16777200] "" Vector__XXX
 SG_ UseTransferMode : 24|2@1+ (1,0) [0|3] "" Vector__XXX

BO_ 2565537534 RQST: 3 Vector__XXX
 SG_ ParameterGroupNumber : 0|24@1+ (1,0) [0|16777200] "" Vector__XXX

BO_ 2499635966 AGW: 8 Vector__XXX
 SG_ AxleGroupLocation : 0|4@1+ (1,0) [0|15] "" Vector__XXX
 SG_ AxleGroupWeight : 8|16@1+ (2,0) [0|128510] "kg" Vector__XXX

BO_ 2633853438 AGCW: 8 Vector__XXX
 SG_ AxleGroupEmptyWeightCalib : 8|16@1+ (2,0) [0|128510] "kg" Vector__XXX
 SG_ AxleGroupFullWeightCalib : 24|16@1+ (2,0) [0|128510] "kg" Vector__XXX
 SG_ AxleGroupLocation : 4|4@1+ (1,0) [0|15] "" Vector__XXX

BO_ 2432520702 ACCVC: 8 Vector__XXX
 SG_ AftercoolerCoolantThermostatMode : 0|2@1+ (1,0) [0|3] "" Vector__XXX
 SG_ DsrdAftercoolerCoolantIntakeTemp : 8|8@1+ (1,-40) [-40|210] "deg C" Vector__XXX
 SG_ DsrdAftrclrClntThermostatOpening : 16|8@1+ (1,0) [0|100] "%" Vector__XXX

BO_ 2566745086 AAGW: 8 Vector__XXX
 SG_ SteerAxleGroupWeightAvailable : 0|2@1+ (1,0) [0|3] "" Vector__XXX
 SG_ LiftAxleGroupWeightAvailable : 2|2@1+ (1,0) [0|3] "" Vector__XXX
 SG_ DriveAxleGroupWeightAvailable : 4|2@1+ (1,0) [0|3] "" Vector__XXX
 SG_ TagAxleGroupWeightAvailable : 6|2@1+ (1,0) [0|3] "" Vector__XXX
 SG_ AddtnlTrctrAxlGrpWeightAvailable : 8|2@1+ (1,0) [0|3] "" Vector__XXX
 SG_ TrailerAAxleGroupWeightAvailable : 10|2@1+ (1,0) [0|3] "" Vector__XXX
 SG_ TrailerBAxleGroupWeightAvailable : 12|2@1+ (1,0) [0|3] "" Vector__XXX
 SG_ TrailerCAxleGroupWeightAvailable : 14|2@1+ (1,0) [0|3] "" Vector__XXX
 SG_ TrailerDAxleGroupWeightAvailable : 16|2@1+ (1,0) [0|3] "" Vector__XXX
 SG_ TrailerEAxleGroupWeightAvailable : 18|2@1+ (1,0) [0|3] "" Vector__XXX
 SG_ TrailerFAxleGroupWeightAvailable : 20|2@1+ (1,0) [0|3] "" Vector__XXX
 SG_ TrailerGAxleGroupWeightAvailable : 22|2@1+ (1,0) [0|3] "" Vector__XXX
 SG_ TrailerHAxleGroupWeightAvailable : 24|2@1+ (1,0) [0|3] "" Vector__XXX
 SG_ AddtnlTrlrAxlGrupWeightAvailable : 26|2@1+ (1,0) [0|3] "" Vector__XXX

BO_ 2566744062 ZNVW: 8 Vector__XXX
 SG_ ZeroNetVehicleWeightChange : 0|2@1+ (1,0) [0|3] "" Vector__XXX

BO_ 2499630078 EAI: 8 Vector__XXX
 SG_ EngExhaustGasTempAverage : 0|16@1+ (1,-273) [-273|1735] "deg C" Vector__XXX
 SG_ EngExhaustGasTempAverageBank1 : 16|16@1+ (1,-273) [-273|1735] "deg C" Vector__XXX
 SG_ EngExhaustGasTempAverageBank2 : 32|16@1+ (1,-273) [-273|1735] "deg C" Vector__XXX

BO_ 2560556798 DM29: 8 Vector__XXX
 SG_ PendingDTCs : 0|8@1+ (1,0) [0|255] "" Vector__XXX
 SG_ AllPendingDTCs : 8|8@1+ (1,0) [0|255] "" Vector__XXX
 SG_ MILOnDTCs : 16|8@1+ (1,0) [0|255] "" Vector__XXX
 SG_ PreviouslyMILOnDTCs : 24|8@1+ (1,0) [0|255] "" Vector__XXX
 SG_ PermanentDTCs : 32|8@1+ (1,0) [0|255] "" Vector__XXX

BO_ 2566754558 AETC: 8 Vector__XXX
 SG_ AETCDataCollectionStandard : 0|4@1+ (1,0) [0|15] "" Vector__XXX
 SG_ NumberOfAETCDataPoints : 4|4@1+ (1,0) [0|15] "" Vector__XXX
 SG_ AETCTorqueValue : 24|16@1+ (1,0) [0|64255] "Nm" Vector__XXX
 SG_ AETCSpeedValue : 8|16@1+ (0.125,0) [0|8031.88] "rpm" Vector__XXX

BO_ 2566749950 AFSS: 8 Vector__XXX
 SG_ LeftHeadlampDynamicBendingLight : 0|3@1+ (1,0) [0|7] "" Vector__XXX
 SG_ RightHeadlampDynamicBendingLight : 3|3@1+ (1,0) [0|7] "" Vector__XXX
 SG_ LeftHeadlampLightDistribution : 8|4@1+ (1,0) [0|15] "" Vector__XXX
 SG_ RightHeadlampLightDistribution : 12|4@1+ (1,0) [0|15] "" Vector__XXX

BO_ 2566838782 AUXIO1: 8 Vector__XXX
 SG_ AuxI_O03 : 63|2@1+ (1,0) [0|3] "" Vector__XXX
 SG_ AuxI_O04 : 0|2@1+ (1,0) [0|3] "" Vector__XXX
 SG_ AuxI_O02 : 4|2@1+ (1,0) [0|3] "" Vector__XXX
 SG_ AuxI_O01 : 6|2@1+ (1,0) [0|3] "" Vector__XXX
 SG_ AuxI_O08 : 8|2@1+ (1,0) [0|3] "" Vector__XXX
 SG_ AuxI_O07 : 10|2@1+ (1,0) [0|3] "" Vector__XXX
 SG_ AuxI_O06 : 12|2@1+ (1,0) [0|3] "" Vector__XXX
 SG_ AuxI_O05 : 14|2@1+ (1,0) [0|3] "" Vector__XXX
 SG_ AuxI_O12 : 16|2@1+ (1,0) [0|3] "" Vector__XXX
 SG_ AuxI_O11 : 18|2@1+ (1,0) [0|3] "" Vector__XXX
 SG_ AuxI_O10 : 20|2@1+ (1,0) [0|3] "" Vector__XXX
 SG_ AuxI_O09 : 22|2@1+ (1,0) [0|3] "" Vector__XXX
 SG_ AuxI_O16 : 24|2@1+ (1,0) [0|3] "" Vector__XXX
 SG_ AuxI_O15 : 26|2@1+ (1,0) [0|3] "" Vector__XXX
 SG_ AuxI_O14 : 28|2@1+ (1,0) [0|3] "" Vector__XXX
 SG_ AuxI_O13 : 30|2@1+ (1,0) [0|3] "" Vector__XXX
 SG_ AuxI_OChannel1 : 32|16@1+ (1,0) [0|64255] "counts" Vector__XXX
 SG_ AuxI_OChannel2 : 48|16@1+ (1,0) [0|64255] "counts" Vector__XXX

BO_ 2561146622 AUXIO2: 8 Vector__XXX
 SG_ AuxI_O20 : 0|2@1+ (1,0) [0|3] "" Vector__XXX
 SG_ AuxI_O19 : 2|2@1+ (1,0) [0|3] "" Vector__XXX
 SG_ AuxI_O18 : 4|2@1+ (1,0) [0|3] "" Vector__XXX
 SG_ AuxI_O17 : 6|2@1+ (1,0) [0|3] "" Vector__XXX
 SG_ AuxI_O24 : 8|2@1+ (1,0) [0|3] "" Vector__XXX
 SG_ AuxI_O23 : 10|2@1+ (1,0) [0|3] "" Vector__XXX
 SG_ AuxI_O22 : 12|2@1+ (1,0) [0|3] "" Vector__XXX
 SG_ AuxI_O21 : 14|2@1+ (1,0) [0|3] "" Vector__XXX
 SG_ AuxI_O28 : 16|2@1+ (1,0) [0|3] "" Vector__XXX
 SG_ AuxI_O27 : 18|2@1+ (1,0) [0|3] "" Vector__XXX
 SG_ AuxI_O26 : 20|2@1+ (1,0) [0|3] "" Vector__XXX
 SG_ AuxI_O25 : 22|2@1+ (1,0) [0|3] "" Vector__XXX
 SG_ AuxI_O32 : 24|2@1+ (1,0) [0|3] "" Vector__XXX
 SG_ AuxI_O31 : 26|2@1+ (1,0) [0|3] "" Vector__XXX
 SG_ AuxI_O30 : 28|2@1+ (1,0) [0|3] "" Vector__XXX
 SG_ AuxI_O29 : 30|2@1+ (1,0) [0|3] "" Vector__XXX
 SG_ AuxI_O36 : 32|2@1+ (1,0) [0|3] "" Vector__XXX
 SG_ AuxI_O35 : 34|2@1+ (1,0) [0|3] "" Vector__XXX
 SG_ AuxI_O34 : 36|2@1+ (1,0) [0|3] "" Vector__XXX
 SG_ AuxI_O33 : 38|2@1+ (1,0) [0|3] "" Vector__XXX
 SG_ AuxI_O40 : 40|2@1+ (1,0) [0|3] "" Vector__XXX
 SG_ AuxI_O39 : 42|2@1+ (1,0) [0|3] "" Vector__XXX
 SG_ AuxI_O38 : 44|2@1+ (1,0) [0|3] "" Vector__XXX
 SG_ AuxI_O37 : 46|2@1+ (1,0) [0|3] "" Vector__XXX
 SG_ AuxI_O44 : 48|2@1+ (1,0) [0|3] "" Vector__XXX
 SG_ AuxI_O43 : 50|2@1+ (1,0) [0|3] "" Vector__XXX
 SG_ AuxI_O42 : 52|2@1+ (1,0) [0|3] "" Vector__XXX
 SG_ AuxI_O41 : 54|2@1+ (1,0) [0|3] "" Vector__XXX
 SG_ AuxI_O48 : 56|2@1+ (1,0) [0|3] "" Vector__XXX
 SG_ AuxI_O47 : 58|2@1+ (1,0) [0|3] "" Vector__XXX
 SG_ AuxI_O46 : 60|2@1+ (1,0) [0|3] "" Vector__XXX
 SG_ AuxI_O45 : 62|2@1+ (1,0) [0|3] "" Vector__XXX

BO_ 2561081086 AUXIO3: 8 Vector__XXX
 SG_ AuxI_O52 : 0|2@1+ (1,0) [0|3] "" Vector__XXX
 SG_ AuxI_O51 : 2|2@1+ (1,0) [0|3] "" Vector__XXX
 SG_ AuxI_O50 : 4|2@1+ (1,0) [0|3] "" Vector__XXX
 SG_ AuxI_O49 : 6|2@1+ (1,0) [0|3] "" Vector__XXX
 SG_ AuxI_O56 : 8|2@1+ (1,0) [0|3] "" Vector__XXX
 SG_ AuxI_O55 : 10|2@1+ (1,0) [0|3] "" Vector__XXX
 SG_ AuxI_O54 : 12|2@1+ (1,0) [0|3] "" Vector__XXX
 SG_ AuxI_O53 : 14|2@1+ (1,0) [0|3] "" Vector__XXX
 SG_ AuxI_O60 : 16|2@1+ (1,0) [0|3] "" Vector__XXX
 SG_ AuxI_O59 : 18|2@1+ (1,0) [0|3] "" Vector__XXX
 SG_ AuxI_O58 : 20|2@1+ (1,0) [0|3] "" Vector__XXX
 SG_ AuxI_O57 : 22|2@1+ (1,0) [0|3] "" Vector__XXX
 SG_ AuxI_O64 : 24|2@1+ (1,0) [0|3] "" Vector__XXX
 SG_ AuxI_O63 : 26|2@1+ (1,0) [0|3] "" Vector__XXX
 SG_ AuxI_O62 : 28|2@1+ (1,0) [0|3] "" Vector__XXX
 SG_ AuxI_O61 : 30|2@1+ (1,0) [0|3] "" Vector__XXX
 SG_ AuxI_O68 : 32|2@1+ (1,0) [0|3] "" Vector__XXX
 SG_ AuxI_O67 : 34|2@1+ (1,0) [0|3] "" Vector__XXX
 SG_ AuxI_O66 : 36|2@1+ (1,0) [0|3] "" Vector__XXX
 SG_ AuxI_O65 : 38|2@1+ (1,0) [0|3] "" Vector__XXX
 SG_ AuxI_O72 : 40|2@1+ (1,0) [0|3] "" Vector__XXX
 SG_ AuxI_O71 : 42|2@1+ (1,0) [0|3] "" Vector__XXX
 SG_ AuxI_O70 : 44|2@1+ (1,0) [0|3] "" Vector__XXX
 SG_ AuxI_O69 : 46|2@1+ (1,0) [0|3] "" Vector__XXX
 SG_ AuxI_O76 : 48|2@1+ (1,0) [0|3] "" Vector__XXX
 SG_ AuxI_O75 : 50|2@1+ (1,0) [0|3] "" Vector__XXX
 SG_ AuxI_O74 : 52|2@1+ (1,0) [0|3] "" Vector__XXX
 SG_ AuxI_O73 : 54|2@1+ (1,0) [0|3] "" Vector__XXX
 SG_ AuxI_O80 : 56|2@1+ (1,0) [0|3] "" Vector__XXX
 SG_ AuxI_O79 : 58|2@1+ (1,0) [0|3] "" Vector__XXX
 SG_ AuxI_O78 : 60|2@1+ (1,0) [0|3] "" Vector__XXX
 SG_ AuxI_O77 : 62|2@1+ (1,0) [0|3] "" Vector__XXX

BO_ 2561015550 AUXIO4: 8 Vector__XXX
 SG_ AuxI_O84 : 0|2@1+ (1,0) [0|3] "" Vector__XXX
 SG_ AuxI_O83 : 2|2@1+ (1,0) [0|3] "" Vector__XXX
 SG_ AuxI_O82 : 4|2@1+ (1,0) [0|3] "" Vector__XXX
 SG_ AuxI_O81 : 6|2@1+ (1,0) [0|3] "" Vector__XXX
 SG_ AuxI_O88 : 8|2@1+ (1,0) [0|3] "" Vector__XXX
 SG_ AuxI_O87 : 10|2@1+ (1,0) [0|3] "" Vector__XXX
 SG_ AuxI_O86 : 12|2@1+ (1,0) [0|3] "" Vector__XXX
 SG_ AuxI_O85 : 14|2@1+ (1,0) [0|3] "" Vector__XXX
 SG_ AuxI_O92 : 16|2@1+ (1,0) [0|3] "" Vector__XXX
 SG_ AuxI_O91 : 18|2@1+ (1,0) [0|3] "" Vector__XXX
 SG_ AuxI_O90 : 20|2@1+ (1,0) [0|3] "" Vector__XXX
 SG_ AuxI_O89 : 22|2@1+ (1,0) [0|3] "" Vector__XXX
 SG_ AuxI_O96 : 24|2@1+ (1,0) [0|3] "" Vector__XXX
 SG_ AuxI_O95 : 26|2@1+ (1,0) [0|3] "" Vector__XXX
 SG_ AuxI_O94 : 28|2@1+ (1,0) [0|3] "" Vector__XXX
 SG_ AuxI_O93 : 30|2@1+ (1,0) [0|3] "" Vector__XXX
 SG_ AuxI_O100 : 32|2@1+ (1,0) [0|3] "" Vector__XXX
 SG_ AuxI_O99 : 34|2@1+ (1,0) [0|3] "" Vector__XXX
 SG_ AuxI_O98 : 36|2@1+ (1,0) [0|3] "" Vector__XXX
 SG_ AuxI_O97 : 38|2@1+ (1,0) [0|3] "" Vector__XXX
 SG_ AuxI_O104 : 40|2@1+ (1,0) [0|3] "" Vector__XXX
 SG_ AuxI_O103 : 42|2@1+ (1,0) [0|3] "" Vector__XXX
 SG_ AuxI_O102 : 44|2@1+ (1,0) [0|3] "" Vector__XXX
 SG_ AuxI_O101 : 46|2@1+ (1,0) [0|3] "" Vector__XXX
 SG_ AuxI_O108 : 48|2@1+ (1,0) [0|3] "" Vector__XXX
 SG_ AuxI_O107 : 50|2@1+ (1,0) [0|3] "" Vector__XXX
 SG_ AuxI_O106 : 52|2@1+ (1,0) [0|3] "" Vector__XXX
 SG_ AuxI_O105 : 54|2@1+ (1,0) [0|3] "" Vector__XXX
 SG_ AuxI_O112 : 56|2@1+ (1,0) [0|3] "" Vector__XXX
 SG_ AuxI_O111 : 58|2@1+ (1,0) [0|3] "" Vector__XXX
 SG_ AuxI_O110 : 60|2@1+ (1,0) [0|3] "" Vector__XXX
 SG_ AuxI_O109 : 62|2@1+ (1,0) [0|3] "" Vector__XXX

BO_ 2566746622 BSA: 8 Vector__XXX
 SG_ TractorBrakeStrokeAxle1Left : 0|3@1+ (1,0) [0|7] "" Vector__XXX
 SG_ TractorBrakeStrokeAxle1Right : 3|3@1+ (1,0) [0|7] "" Vector__XXX
 SG_ TractorBrakeStrokeAxle2Left : 6|3@1+ (1,0) [0|7] "" Vector__XXX
 SG_ TractorBrakeStrokeAxle2Right : 9|3@1+ (1,0) [0|7] "" Vector__XXX
 SG_ TractorBrakeStrokeAxle3Left : 12|3@1+ (1,0) [0|7] "" Vector__XXX
 SG_ TractorBrakeStrokeAxle3Right : 15|3@1+ (1,0) [0|7] "" Vector__XXX
 SG_ TractorBrakeStrokeAxle4Left : 18|3@1+ (1,0) [0|7] "" Vector__XXX
 SG_ TractorBrakeStrokeAxle4Right : 21|3@1+ (1,0) [0|7] "" Vector__XXX
 SG_ TractorBrakeStrokeAxle5Left : 24|3@1+ (1,0) [0|7] "" Vector__XXX
 SG_ TractorBrakeStrokeAxle5Right : 27|3@1+ (1,0) [0|7] "" Vector__XXX
 SG_ TrailerBrakeStrokeAxle1Left : 30|3@1+ (1,0) [0|7] "" Vector__XXX
 SG_ TrailerBrakeStrokeAxle1Right : 33|3@1+ (1,0) [0|7] "" Vector__XXX
 SG_ TrailerBrakeStrokeAxle2Left : 36|3@1+ (1,0) [0|7] "" Vector__XXX
 SG_ TrailerBrakeStrokeAxle2Right : 39|3@1+ (1,0) [0|7] "" Vector__XXX
 SG_ TrailerBrakeStrokeAxle3Left : 42|3@1+ (1,0) [0|7] "" Vector__XXX
 SG_ TrailerBrakeStrokeAxle3Right : 45|3@1+ (1,0) [0|7] "" Vector__XXX
 SG_ TrailerBrakeStrokeAxle4Left : 48|3@1+ (1,0) [0|7] "" Vector__XXX
 SG_ TrailerBrakeStrokeAxle4Right : 51|3@1+ (1,0) [0|7] "" Vector__XXX
 SG_ TrailerBrakeStrokeAxle5Left : 54|3@1+ (1,0) [0|7] "" Vector__XXX
 SG_ TrailerBrakeStrokeAxle5Right : 57|3@1+ (1,0) [0|7] "" Vector__XXX

BO_ 2566845950 AMB: 8 Vector__XXX
 SG_ BarometricPress : 0|8@1+ (0.5,0) [0|125] "kPa" Vector__XXX
 SG_ CabInteriorTemp : 8|16@1+ (0.03125,-273) [-273|1734.97] "deg C" Vector__XXX
 SG_ AmbientAirTemp : 24|16@1+ (0.03125,-273) [-273|1734.97] "deg C" Vector__XXX
 SG_ EngAirIntakeTemp : 40|8@1+ (1,-40) [-40|210] "deg C" Vector__XXX
 SG_ RoadSurfaceTemp : 48|16@1+ (0.03125,-273) [-273|1734.97] "deg C" Vector__XXX

BO_ 2566840062 AIR2: 8 Vector__XXX
 SG_ EngAirStartPress : 0|8@1+ (4,0) [0|1000] "kPa" Vector__XXX

BO_ 2566827569 AIR1: 8 Vector__XXX
 SG_ PneumaticSupplyPress : 0|8@1+ (8,0) [0|2000] "kPa" Vector__XXX
 SG_ ParkingAnd_orTrailerAirPress : 8|8@1+ (8,0) [0|2000] "kPa" Vector__XXX
 SG_ ServiceBrakeCircuit1AirPress : 16|8@1+ (8,0) [0|2000] "kPa" Vector__XXX
 SG_ ServiceBrakeCircuit2AirPress : 24|8@1+ (8,0) [0|2000] "kPa" Vector__XXX
 SG_ AuxEquipmentSupplyPress : 32|8@1+ (8,0) [0|2000] "kPa" Vector__XXX
 SG_ AirSuspensionSupplyPress : 40|8@1+ (8,0) [0|2000] "kPa" Vector__XXX
 SG_ AirCompressorStatus : 48|2@1+ (1,0) [0|3] ""  VCU

BO_ 2566846974 AI: 8 Vector__XXX
 SG_ DriveAxleLocation : 8|8@1+ (1.02,0) [0|255] "" Vector__XXX
 SG_ DriveAxleLiftAirPress : 16|8@1+ (4,0) [0|1000] "kPa" Vector__XXX
 SG_ DriveAxleTemp : 24|8@1+ (1,-40) [-40|210] "deg C" Vector__XXX
 SG_ DriveAxleLubePress : 32|8@1+ (4,0) [0|1000] "kPa" Vector__XXX
 SG_ SteerAxleTemp : 0|8@1+ (1,-40) [-40|210] "deg C" Vector__XXX
 SG_ SteerAxleLubePress : 56|8@1+ (4,0) [0|1000] "kPa" Vector__XXX

BO_ 2633935614 AF2: 8 Vector__XXX
 SG_ EngGasFuelCorrectionFactor : 0|8@1+ (1,0) [0|250] "%" Vector__XXX
 SG_ EngDesiredAbsIntakeManifoldPress : 8|16@1+ (1,0) [0|6426] "kPa" Vector__XXX
 SG_ EngTurboWastegateValvePos : 24|8@1+ (0.4,0) [0|100] "%" Vector__XXX
 SG_ EngGsMssFlwSnsrFuelingCorrection : 32|8@1+ (1,-125) [-125|125] "%" Vector__XXX

BO_ 2566803966 ACC2: 8 Vector__XXX
 SG_ ACCUsageDemand : 0|2@1+ (1,0) [0|3] "" Vector__XXX
 SG_ RequestedACCDistanceMode : 5|3@1+ (1,0) [0|7] "" Vector__XXX

BO_ 2432593706 ACC1: 8 Vector__XXX
 SG_ SpeedOfForwardVehicle : 0|8@1+ (1,0) [0|250] "km/h" Vector__XXX
 SG_ DistanceToForwardVehicle : 8|8@1+ (1,0) [0|250] "m" Vector__XXX
 SG_ AdaptiveCruiseCtrlSetSpeed : 16|8@1+ (1,0) [0|250] "km/h" Vector__XXX
 SG_ AdaptiveCruiseCtrlMode : 24|3@1+ (1,0) [0|7] "" Vector__XXX
 SG_ AdptiveCruiseCtrlSetDistanceMode : 27|3@1+ (1,0) [0|7] "" Vector__XXX
 SG_ RoadCurvature : 32|16@1+ (0.007813,-250) [-250|252.024] "1/km" Vector__XXX
 SG_ ACCTargetDetected : 48|2@1+ (1,0) [0|3] "" Vector__XXX
 SG_ ACCSystemShutoffWarning : 50|2@1+ (1,0) [0|3] "" Vector__XXX
 SG_ ACCDistanceAlertSignal : 52|2@1+ (1,0) [0|3] "" Vector__XXX
 SG_ ForwardCollisionWarning : 54|2@1+ (1,0) [0|3] ""  VCU

BO_ 2633935102 AC: 8 Vector__XXX
 SG_ ArticulationAngle : 0|8@1+ (1,-125) [-125|125] "deg" Vector__XXX

BO_ 2633927934 AAI: 8 Vector__XXX
 SG_ AuxTemp1 : 0|8@1+ (1,-40) [-40|210] "deg C" Vector__XXX
 SG_ AuxTemp2 : 8|8@1+ (1,-40) [-40|210] "deg C" Vector__XXX
 SG_ AuxPress1 : 16|8@1+ (16,0) [0|4000] "kPa" Vector__XXX
 SG_ AuxPress2 : 24|8@1+ (16,0) [0|4000] "kPa" Vector__XXX
 SG_ AuxLevel : 32|16@1+ (0.1,0) [0|6425.5] "mm" Vector__XXX
 SG_ RelativeHumidity : 48|8@1+ (0.4,0) [0|100] "%" Vector__XXX

BO_ 2566847998 A1: 8 Vector__XXX
 SG_ EngGasSupplyPress : 8|16@1+ (0.5,0) [0|32127.5] "kPa" Vector__XXX
 SG_ EngBlowerBypassValvePos : 0|8@1+ (0.4,0) [0|100] "%" Vector__XXX

BO_ 2565406462 ACKM: 8 Vector__XXX
 SG_ AddressAcknowledged : 40|8@1+ (1,0) [0|255] "" Vector__XXX
 SG_ AddressNegativeAcknowledgement : 32|8@1+ (1,0) [0|255] "" Vector__XXX
 SG_ AddressAccessDenied : 24|8@1+ (1,0) [0|255] "" Vector__XXX
 SG_ GroupFunctionValue : 8|8@1+ (1,0) [0|255] "" Vector__XXX
 SG_ ParameterGroupNumber : 48|24@1+ (1,0) [0|16777200] "" Vector__XXX
 SG_ ControlByte : 0|8@1+ (1,0) [0|255] "" Vector__XXX
 SG_ AddressBusy : 16|8@1+ (1,0) [0|255] "" Vector__XXX

BO_ 2566803198 DC1: 8 Vector__XXX
 SG_ PosOfDoors : 0|4@1+ (1,0) [0|15] "" Vector__XXX
 SG_ Ramp_WheelChairLiftPos : 4|2@1+ (1,0) [0|3] "" Vector__XXX
 SG_ Status2OfDoors : 6|2@1+ (1,0) [0|3] "" Vector__XXX

BO_ 2565870334 FWSS1: 8 Vector__XXX
 SG_ FifthWheelVerticalForce : 0|16@1+ (5,0) [0|321275] "N" Vector__XXX
 SG_ FifthWheelDrawbarForce : 16|16@1+ (10,-320000) [-320000|322550] "N" Vector__XXX
 SG_ FifthWheelRollMoment : 32|16@1+ (10,-320000) [-320000|322550] "N" Vector__XXX
 SG_ FifthWheelRollWarningIndicator : 48|2@1+ (1,0) [0|3] "" Vector__XXX

BO_ 2566762238 FWSS2: 8 Vector__XXX
 SG_ FifthWheelErrorStatus : 0|4@1+ (1,0) [0|15] "" Vector__XXX
 SG_ FfthWhlLckReadyToCoupleIndicator : 4|2@1+ (1,0) [0|3] "" Vector__XXX
 SG_ FfthWhlLockCoupleStatusIndicator : 6|2@1+ (1,0) [0|3] "" Vector__XXX
 SG_ FifthWheelSliderPos : 8|8@1+ (10,0) [0|2500] "mm" Vector__XXX
 SG_ FifthWheelSliderLockIndicator : 16|2@1+ (1,0) [0|3] "" Vector__XXX

BO_ 2364543998 SSI: 8 Vector__XXX
 SG_ PitchAngle : 0|16@1+ (0.002,-64) [-64|64.51] "deg" Vector__XXX
 SG_ RollAngle : 16|16@1+ (0.002,-64) [-64|64.51] "deg" Vector__XXX
 SG_ PitchRate : 32|8@1- (0.0001,0) [-0.0128|0.0127] "rad/s" Vector__XXX
 SG_ PitchAngleFigureOfMerit : 48|2@1+ (1,0) [0|3] "" Vector__XXX
 SG_ RollAngleFigureOfMerit : 50|2@1+ (1,0) [0|3] "" Vector__XXX
 SG_ PitchRateFigureOfMerit : 52|2@1+ (1,0) [0|3] "" Vector__XXX
 SG_ PitchAndRollCompensated : 54|2@1+ (1,0) [0|3] "" Vector__XXX
 SG_ RollAndPitchMeasurementLatency : 56|8@1+ (0.5,0) [0|125] "ms" Vector__XXX

BO_ 2566846513 TRF1: 8 Vector__XXX
 SG_ ClutchPress : 0|8@1+ (16,0) [0|4000] "kPa" Vector__XXX
 SG_ TransOilLevel : 8|8@1+ (0.4,0) [0|100] "%" Vector__XXX
 SG_ TransFilterDiffPress : 16|8@1+ (2,0) [0|500] "kPa" Vector__XXX
 SG_ TransOilPress : 24|8@1+ (16,0) [0|4000] "kPa" Vector__XXX
 SG_ TransOilTemp : 32|16@1+ (0.03125,-273) [-273|1734.97] "deg C" Vector__XXX
 SG_ TransOilLevelHigh_Low : 48|8@1+ (0.5,-62.5) [-62.5|62.5] "L" Vector__XXX
 SG_ TransOilLevelCountdownTimer : 56|4@1+ (1,0) [0|15] "" Vector__XXX
 SG_ TransOilLevelMeasurementStatus : 60|4@1+ (1,0) [0|15] "" Vector__XXX

BO_ 2566846208 VEP1: 8 Vector__XXX
 SG_ BatteryPotential_PowerInput1 : 32|16@1+ (0.05,0) [0|3212.75] "V" Vector__XXX
 SG_ KeyswitchBatteryPotential : 48|16@1+ (0.05,0) [0|3212.75] "V" Vector__XXX
 SG_ NetBatteryCurrent : 0|8@1+ (1,-125) [-125|125] "A" Vector__XXX
 SG_ AltCurrent : 8|8@1+ (1,0) [0|250] "A" Vector__XXX
 SG_ ChargingSystemPotential : 16|16@1+ (0.05,0) [0|3212.75] "V"  VCU

BO_ 2566760702 WCM2: 8 Vector__XXX
 SG_ NetworkTransceiverStatus2 : 0|8@1+ (1,0) [0|255] "" Vector__XXX
 SG_ NetworkServiceStatus2 : 8|8@1+ (1,0) [0|255] "" Vector__XXX
 SG_ NetworkAntennaStatus2 : 16|8@1+ (1,0) [0|255] "" Vector__XXX
 SG_ NetworkSignalStrength2 : 24|8@1+ (1,0) [0|100] "%" Vector__XXX
 SG_ WrelessCommunicationNetworkType2 : 32|8@1+ (1,0) [0|255] "" Vector__XXX

BO_ 2566760958 WCM1: 8 Vector__XXX
 SG_ NetworkTransceiverStatus1 : 0|8@1+ (1,0) [0|255] "" Vector__XXX
 SG_ NetworkServiceStatus1 : 8|8@1+ (1,0) [0|255] "" Vector__XXX
 SG_ NetworkAntennaStatus1 : 16|8@1+ (1,0) [0|255] "" Vector__XXX
 SG_ NetworkSignalStrength1 : 24|8@1+ (1,0) [0|100] "%" Vector__XXX
 SG_ WrelessCommunicationNetworkType1 : 32|8@1+ (1,0) [0|255] "" Vector__XXX

BO_ 2633869310 VROM: 8 Vector__XXX
 SG_ VltgRglatorLoadCompensationMode : 0|3@1+ (1,0) [0|7] "" Vector__XXX
 SG_ VltgRgltrVAr_PwrFctrOprtingMode : 3|3@1+ (1,0) [0|7] "" Vector__XXX
 SG_ VltgRgltrUndrfrqncyCmpnstnEnbld : 6|2@1+ (1,0) [0|3] "" Vector__XXX
 SG_ VoltageRegulatorSoftStartState : 8|2@1+ (1,0) [0|3] "" Vector__XXX
 SG_ VoltageRegulatorEnabled : 10|2@1+ (1,0) [0|3] "" Vector__XXX

BO_ 2365433598 VREP: 8 Vector__XXX
 SG_ GeneratorExcitationFieldVoltage : 0|16@1+ (0.05,-1605.63) [-1605.63|1606.37] "V" Vector__XXX
 SG_ GeneratorExcitationFieldCurrent : 16|16@1+ (0.05,0) [0|3217.5] "A" Vector__XXX
 SG_ GnrtrOtputVoltageBiasPercentage : 32|16@1+ (0.1,-100) [-100|100] "%" Vector__XXX

BO_ 2147488528 PDU_Current: 8 Vector__XXX
 SG_ Current4 : 48|16@1- (1,0) [-32768|32767] "" Vector__XXX
 SG_ Current3 : 32|16@1- (1,0) [-32768|32767] "" Vector__XXX
 SG_ Current2 : 16|16@1- (1,0) [-32768|32767] "" Vector__XXX
 SG_ Current1 : 0|16@1- (1,0) [-32768|32767] "" Vector__XXX

BO_ 2147488532 PDU_CMD: 8 Vector__XXX
 SG_ Relay8 : 56|8@1+ (1,0) [0|255] "" Vector__XXX
 SG_ Relay7 : 48|8@1+ (1,0) [0|255] "" Vector__XXX
 SG_ Relay6 : 40|8@1+ (1,0) [0|255] "" Vector__XXX
 SG_ Relay5 : 32|8@1+ (1,0) [0|255] "" Vector__XXX
 SG_ Relay4 : 24|8@1+ (1,0) [0|255] "" Vector__XXX
 SG_ Relay3 : 16|8@1+ (1,0) [0|255] "" Vector__XXX
 SG_ Relay2 : 8|8@1+ (1,0) [0|255] "" Vector__XXX
 SG_ Relay1 : 0|8@1+ (1,0) [0|255] "" Vector__XXX

BO_ 2566803486 PDS_YT_BasicStatus: 8 Vector__XXX
 SG_ LED_FLASH : 54|2@1+ (1,0) [0|3] "" Vector__XXX
 SG_ LED_ON_OFF : 52|2@1+ (1,0) [0|3] "" Vector__XXX
 SG_ Relay2 : 50|2@1+ (1,0) [0|3] "" Vector__XXX
 SG_ Relay1 : 48|2@1+ (1,0) [0|3] "" Vector__XXX
 SG_ Voltage2 : 32|16@1+ (0.05,0) [0|3276.75] "V" Vector__XXX
 SG_ Voltage1 : 16|16@1+ (0.05,0) [0|3276.75] "V" Vector__XXX
 SG_ Temperature2 : 8|8@1- (1,-40) [-168|87] "degC" Vector__XXX
 SG_ Temperature1 : 0|8@1- (1,-40) [-168|87] "degC"  VCU

BO_ 2566803998 PDS_YT_Current: 8 Vector__XXX
 SG_ Current_Server : 16|16@1+ (0.05,-1600) [-3238.4|38.3500000000001] "" Vector__XXX
 SG_ Current_All : 0|16@1+ (0.05,-1600) [-3238.4|38.3500000000001] "A"  VCU

BO_ 2566803991 PDS_YT_Control: 8 Vector__XXX
 SG_ LED_FLASH_Control : 38|2@1+ (1,0) [0|3] "" Vector__XXX
 SG_ LED_ONOFF_Control : 36|2@1+ (1,0) [0|3] "" Vector__XXX
 SG_ Relay2_Control : 34|2@1+ (1,0) [0|3] "" Vector__XXX
 SG_ Relay1_Control : 32|2@1+ (1,0) [0|3] ""  VCU

BO_ 2147516418 ROS_WPoint: 7 Server
 SG_ Turn_Signal : 48|8@1+ (1,0) [0|0] ""  VCU
 SG_ WP_speed : 32|16@1- (0.01,0) [-327.68|327.67] "" Vector__XXX
 SG_ WP_y : 16|16@1- (0.005,0) [0|0] "m" Vector__XXX
 SG_ WP_x : 0|16@1- (0.005,0) [0|0] "m" Vector__XXX

BO_ 2147516420 ROS_Long_Control: 8 Vector__XXX
 SG_ Accel : 0|16@1- (0.005,150) [-13.84|313.835] "" Vector__XXX

BO_ 2147516421 ROS_Lat_Control: 8 Vector__XXX
 SG_ Steering : 0|16@1- (0.005,-150) [-313.84|13.835] "" Vector__XXX

BO_ 2147516423 ROS_Log_Speed: 8 Vector__XXX
 SG_ Speed : 0|16@1- (0.005,-150) [-313.84|13.835] "" Vector__XXX

BO_ 2147516544 ROS_LatCmd: 8 Server
 SG_ lat_enable_demand : 48|8@1+ (1,0) [0|255] "" Vector__XXX
 SG_ steering_effort : 16|16@1- (1,0) [-32768|32767] "" Vector__XXX
 SG_ angle_cmd : 0|16@1- (0.0005,0) [-16.384|16.3835] "rad"  VCU

BO_ 2147516550 ROS_LogCmd: 8 Server
 SG_ xbr_ebi_mode : 32|2@1+ (1,0) [0|3] "" Vector__XXX
 SG_ log_enable_demand : 48|8@1+ (1,0) [0|255] "" Vector__XXX
 SG_ brake_tau : 24|8@1- (0.1,0) [-12.8|12.7] "" Vector__XXX
 SG_ brake_limit : 16|8@1- (0.01,0) [-1.28|1.27] "" Vector__XXX
 SG_ accel_cmd : 0|16@1- (0.0005,0) [-16.384|16.3835] "m/s^2"  VCU

BO_ 2147516424 ROST_Active_Tri: 8 Server
 SG_ Lat_Active : 0|8@1+ (1,0) [0|255] ""  VCU

BO_ 2147516548 ROST_LatReport: 8 VCU
 SG_ Lat_Mode : 36|4@1+ (1,0) [0|15] "" Vector__XXX
 SG_ Lat_Status : 32|4@1+ (1,0) [0|15] "" Vector__XXX
 SG_ accel_y : 16|16@1- (1,0) [-32768|32767] "" Vector__XXX
 SG_ yaw_rate : 0|16@1- (1,0) [-32768|32767] "" Vector__XXX

BO_ 2147516546 ROST_LatStReport: 8 VCU
 SG_ HW_Torque : 48|8@1- (1,0) [-128|127] "" Vector__XXX
 SG_ angle_speed : 32|16@1- (1,0) [-32768|32767] "" Vector__XXX
 SG_ angle_cmd : 16|16@1- (0.0005,0) [-16.384|16.3835] "" Vector__XXX
 SG_ angle_manual : 0|16@1- (0.0005,0) [-16.384|16.3835] "" Vector__XXX

BO_ 2147516560 ROST_LogReport: 8 VCU
 SG_ Log_Mode : 52|4@1+ (1,0) [0|15] "" Vector__XXX
 SG_ Log_Status : 48|4@1+ (1,0) [0|15] "" Vector__XXX
 SG_ cmd_accel : 16|16@1- (1,0) [-32768|32767] "" Vector__XXX
 SG_ current_speed : 0|16@1+ (0.01,0) [0|655.35] "" Vector__XXX
 SG_ foundationbrakeuse : 32|2@1+ (1,0) [0|3] "" Vector__XXX
 SG_ Retarder_Torque : 40|8@1+ (1,0) [0|255] "" Vector__XXX
 SG_ AirBrake_Pressure : 56|8@1+ (1,0) [0|255] "" Vector__XXX

BO_ 2147516552 ROST_LogPdlReport: 7 VCU
 SG_ VDC2_Long_Accel : 48|8@1+ (0.1,-12.5) [-12.5|12.5] "" Vector__XXX
 SG_ DisTFwrVeh : 40|8@1+ (1,0) [0|250] "m" Vector__XXX
 SG_ SpdFwrVeh : 32|8@1+ (1,0) [0|250] "km/h" Vector__XXX
 SG_ remote_accel : 24|8@1+ (0.4,0) [0|100] "%" Vector__XXX
 SG_ brake_pedal : 8|8@1+ (0.4,0) [0|100] "%" Vector__XXX
 SG_ accel_pedal : 0|8@1+ (0.4,0) [0|100] "%" Vector__XXX

BO_ 2147516562 ROST_GlobalReport: 8 VCU
 SG_ lat_error_status : 52|4@1+ (1,0) [0|15] "" Vector__XXX
 SG_ log_error_status : 48|4@1+ (1,0) [0|15] "" Vector__XXX
 SG_ fuel_level2 : 40|8@1+ (0.4,0) [0|102] "" Vector__XXX
 SG_ fuel_level1 : 32|8@1+ (0.4,0) [0|102] "" Vector__XXX
 SG_ gear_ratio : 24|8@1+ (0.1,0) [0|25.5] "" Vector__XXX
 SG_ engine_speed : 16|8@1+ (8,0) [0|2040] "" Vector__XXX
 SG_ current_torque : 0|8@1+ (1,-125) [-125|130] "%" Vector__XXX

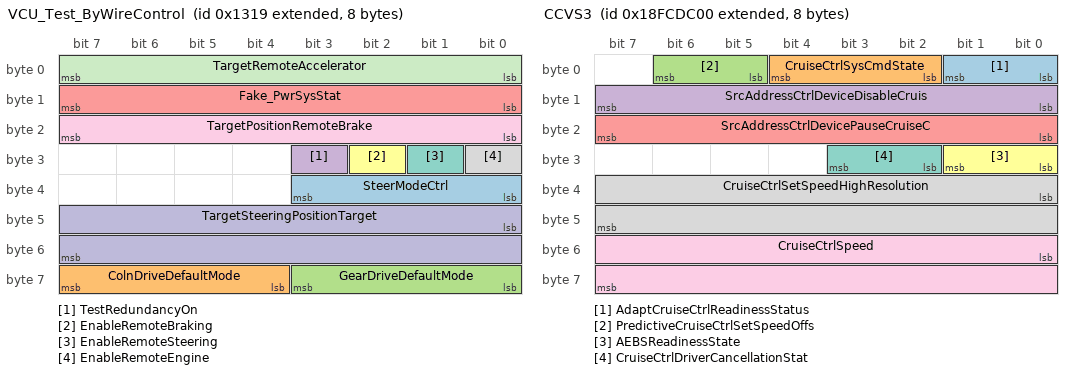
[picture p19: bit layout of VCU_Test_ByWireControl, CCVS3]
BO_ 2147488537 VCU_Test_ByWireControl: 8 VCU
 SG_ SteerModeCtrl : 32|4@1+ (1,0) [0|0] "" Vector__XXX
 SG_ ColnDriveDefaultMode : 60|4@1+ (1,0) [0|0] "" Vector__XXX
 SG_ GearDriveDefaultMode : 56|4@1+ (1,0) [0|0] "" Vector__XXX
 SG_ TestRedundancyOn : 27|1@1+ (1,0) [0|0] "" Vector__XXX
 SG_ Fake_PwrSysStat : 8|8@1+ (1,0) [0|255] "" Vector__XXX
 SG_ EnableRemoteBraking : 26|1@1+ (1,0) [0|1] "" Vector__XXX
 SG_ EnableRemoteSteering : 25|1@1+ (1,0) [0|1] "" Vector__XXX
 SG_ EnableRemoteEngine : 24|1@1+ (1,0) [0|1] "" Vector__XXX
 SG_ TargetPositionRemoteBrake : 16|8@1- (1,0) [-128|127] "m/s^2" Vector__XXX
 SG_ TargetSteeringPositionTarget : 40|16@1- (0.043945,0) [-1439.98976|1439.945815] "deg" Vector__XXX
 SG_ TargetRemoteAccelerator : 0|8@1+ (0.4,0) [0|102] "%" Vector__XXX

BO_ 2147553433 SystemStatus: 8 VCU
 SG_ SystemStatus : 56|8@1+ (1,0) [0|255] "" Vector__XXX
 SG_ TargetBrake : 48|8@1- (0.1,0) [-12.8|12.7] "m/s^2" Vector__XXX
 SG_ ORD_FLAG : 7|1@1+ (1,0) [0|1] "" Vector__XXX
 SG_ TargetThrottle : 40|8@1+ (1,0) [0|255] "%" Vector__XXX
 SG_ TargetSteeringAngle : 32|8@1- (1,0) [-128|127] "degree" Vector__XXX
 SG_ VehicleSpeed : 24|16@1+ (0.003906,0) [0|250.98] "km/hr" Vector__XXX
 SG_ EngineSpeed : 16|16@1+ (0.125,0) [0|8031.88] "rpm" Vector__XXX
 SG_ Voltage_TTC580_V : 8|8@1+ (0.1,0) [0|25.5] "V" Vector__XXX
 SG_ KL15 : 3|1@1+ (1,0) [0|1] "" Vector__XXX
 SG_ IO_EmergencySwitch : 6|1@1+ (1,0) [0|1] "" Vector__XXX
 SG_ IO_AutonomousON : 4|1@1+ (1,0) [0|1] "" Vector__XXX
 SG_ CruiseSwitch : 5|1@1+ (1,0) [0|1] "" Vector__XXX
 SG_ Inverter_ONStatus : 0|1@1+ (1,0) [0|1] "" Vector__XXX
 SG_ UPS_ONStatus : 1|1@1+ (1,0) [0|1] "" Vector__XXX
 SG_ Server_ONStatus : 2|1@1+ (1,0) [0|1] "" Vector__XXX

BO_ 2364539185 EBC1_C31: 8 Vector__XXX
 SG_ EngineRetarderC31 : 32|8@1+ (0.4,0) [0|102] "" Vector__XXX

BO_ 2632974641 EBC1_1C31: 8 Vector__XXX
 SG_ EngineRetarder1C31 : 32|8@1+ (0.4,0) [0|102] "" Vector__XXX

BO_ 2364550954 AEBS1: 8 Vector__XXX
 SG_ AdvanEmerBrakingSysState : 0|4@1+ (1,0) [0|15] "bit" Vector__XXX
 SG_ CollisionWarningLevel : 4|4@1+ (1,0) [0|15] "bit" Vector__XXX
 SG_ ReleObjDetectAdvEmerBrakSys : 8|3@1+ (1,0) [0|7] "bit" Vector__XXX
 SG_ BendOffProbRelevantObj : 11|3@1+ (1,0) [0|7] "bit" Vector__XXX
 SG_ TimeToCollisionWithRelevantObj : 16|8@1+ (0.05,0) [0|0.6] "s" Vector__XXX

BO_ 2566711857 HSS2: 8 Vector__XXX
 SG_ HybridBatPackRemainCharge : 0|16@1+ (0.0025,0) [0|0.88] "%" Vector__XXX
 SG_ HybridSysEngStopStartRemainPerce : 16|8@1+ (0.4,0) [0|40] "%" Vector__XXX

BO_ 2566834688 DM1: 8 Vector__XXX
 SG_ ProtectLamp : 0|2@1+ (1,0) [0|3] "" Vector__XXX
 SG_ AmberWarningLamp : 2|2@1+ (1,0) [0|3] "" Vector__XXX
 SG_ RedStopLamp : 4|2@1+ (1,0) [0|3] "" Vector__XXX
 SG_ MalfuncIndicatorLamp : 6|2@1+ (1,0) [0|3] "" Vector__XXX
 SG_ FlashProtectLamp : 8|2@1+ (1,0) [0|3] "" Vector__XXX
 SG_ FlashAmberWarningLamp : 10|2@1+ (1,0) [0|3] "" Vector__XXX
 SG_ FlashRedStopLamp : 12|2@1+ (1,0) [0|3] "" Vector__XXX
 SG_ FlashMalfuncIndicatorLamp : 14|2@1+ (1,0) [0|3] "" Vector__XXX
 SG_ SuspectParamNumber : 16|19@1+ (1,0) [0|524287] "" Vector__XXX
 SG_ FailureModeIdentifier : 35|5@1+ (1,0) [0|31] "" Vector__XXX
 SG_ OccuranceCount : 40|7@1+ (1,0) [0|127] "" Vector__XXX
 SG_ SPNConverMethod : 45|2@1+ (1,0) [0|3] "" Vector__XXX

BO_ 2566708224 CCVS3: 8 Vector__XXX
 SG_ AdaptCruiseCtrlReadinessStatus : 0|2@1+ (1,0) [0|3] "" Vector__XXX
 SG_ CruiseCtrlSysCmdState : 2|3@1+ (1,0) [0|7] "" Vector__XXX
 SG_ PredictiveCruiseCtrlSetSpeedOffs : 5|2@1+ (1,0) [0|3] "" Vector__XXX
 SG_ SrcAddressCtrlDeviceDisableCruis : 8|8@1+ (1,0) [0|255] "" Vector__XXX
 SG_ SrcAddressCtrlDevicePauseCruiseC : 16|8@1+ (1,0) [0|255] "" Vector__XXX
 SG_ AEBSReadinessState : 24|2@1+ (1,0) [0|3] "" Vector__XXX
 SG_ CruiseCtrlDriverCancellationStat : 26|2@1+ (1,0) [0|3] "" Vector__XXX
 SG_ CruiseCtrlSetSpeedHighResolution : 32|16@1+ (0.003906,0) [0|250.98] "" Vector__XXX
 SG_ CruiseCtrlSpeed : 48|16@1+ (0.003906,0) [0|250.98] "" Vector__XXX

BO_ 2566662912 CCVS4: 8 Vector__XXX
 SG_ AppliedVehicleSpeedLimit_HR : 0|16@1+ (0.003906,0) [0|250.98] "" Vector__XXX
 SG_ CruiseCtrlAdjustedMaxSpeed : 24|16@1+ (0.003906,0) [0|250.98] "" Vector__XXX
 SG_ EngExternalIdleRequestFeedback : 40|2@1+ (1,0) [0|3] "" Vector__XXX

BO_ 2499581952 VSL: 8 Vector__XXX
 SG_ SoftTopSpeedLimitActive : 0|2@1+ (1,0) [0|3] "" Vector__XXX
 SG_ VehicleSpeedLimiter : 2|2@1+ (1,0) [0|3] "" Vector__XXX
 SG_ SoftTopSpeedLimitRemainingDistan : 8|16@1+ (1,0) [0|64255] "" Vector__XXX
 SG_ SoftTopSpeedLimitResetDistance : 24|16@1+ (1,0) [0|64255] "" Vector__XXX
 SG_ SoftTopSpeedLimitRemainContInter : 40|16@1+ (1,0) [0|64255] "" Vector__XXX

CM_ SG_ 2364543998 PitchRate "about x axis rotation";
CM_ SG_ 2566803486 Voltage2 "Voltage after PDS main relay";
CM_ SG_ 2566803486 Voltage1 "Voltage before PDS main relay";
CM_ SG_ 2566803486 Temperature2 "Temperature after main relay";
CM_ SG_ 2566803486 Temperature1 "Temperature before main relay";
BA_DEF_ BO_  "GenMsgCycleTime" INT 0 65535;
BA_DEF_DEF_  "GenMsgCycleTime" 0;
BA_ "GenMsgCycleTime" BO_ 2565866755 10;
BA_ "GenMsgCycleTime" BO_ 2364539904 200;
BA_ "GenMsgCycleTime" BO_ 2566767627 10;
BA_ "GenMsgCycleTime" BO_ 2432593706 100;
BA_ "GenMsgCycleTime" BO_ 2566803486 200;
BA_ "GenMsgCycleTime" BO_ 2147516418 500;
BA_ "GenMsgCycleTime" BO_ 2147516544 40;
BA_ "GenMsgCycleTime" BO_ 2147516550 40;
VAL_ 2348941054 TransGearShiftInhibitRq 0 "Gear shifts are allowed disable function" 1 "Gear shifts are inhibited enable function" 3 "Take no action leave function as is" 2 "Reserved" ;
VAL_ 2348941054 TrnsTrqeConverterLockupDisableRq 0 "Allow torque converter lockup" 1 "Disable torque converter lockup" 2 "Reserved" 3 "Take no action" ;
VAL_ 2348941054 DisengageDrivelineRq 0 "Allow driveline engagement" 1 "Disengage driveline" 3 "Take no action" 2 "Reserved" ;
VAL_ 2348941054 TransReverseGearShiftInhibitRq 0 "Allow shifts into Reverse gear" 1 "Inhibit shifts into Reverse gear and shift transmission to Neutral if already in Reverse or attempting to shift to" 2 "Reserved" 3 "Take no action" ;
VAL_ 2348941054 DisengageDiffLockRqFrontAxle1 0 "Engage differential lock" 1 "Disengage differential lock" 2 "Reserved" 3 "Take no action" ;
VAL_ 2348941054 DisengageDiffLockRqFrontAxle2 0 "Engage differential lock" 1 "Disengage differential lock" 2 "Reserved" 3 "Take no action" ;
VAL_ 2348941054 DisengageDiffLockRqRearAxle1 0 "Engage differential lock" 1 "Disengage differential lock" 2 "Reserved" 3 "Take no action" ;
VAL_ 2348941054 DisengageDiffLockRqRearAxle2 0 "Engage differential lock" 1 "Disengage differential lock" 2 "Reserved" 3 "Take no action" ;
VAL_ 2348941054 DisengageDiffLockRqCentral 0 "Engage differential lock" 1 "Disengage differential lock" 2 "Reserved" 3 "Take no action" ;
VAL_ 2348941054 DisengageDiffLockRqCentralFront 0 "Engage differential lock" 1 "Disengage differential lock" 2 "Reserved" 3 "Take no action" ;
VAL_ 2348941054 DisengageDiffLockRqCentralRear 0 "Engage differential lock" 1 "Disengage differential lock" 2 "Reserved" 3 "Take no action" ;
VAL_ 2348941054 TransMode1 0 "Disable" 1 "Enable" 2 "Reserved" 3 "Take no action" ;
VAL_ 2348941054 TransMode2 0 "Disable" 1 "Enable" 2 "Reserved" 3 "Take no action" ;
VAL_ 2348941054 TransMode3 0 "Disable" 1 "Enable" 2 "Reserved" 3 "Take no action" ;
VAL_ 2348941054 TransMode4 0 "Disable" 1 "Enable" 2 "Reserved" 3 "Take no action" ;
VAL_ 2348941054 TransRequestedLaunchGear 0 "No specific launch gear requested use default launch gear" 1 "Launch the vehicle in 1st gear" 2 "Launch the vehicle in 2nd gear" 3 "Launch the vehicle in 3rd gear" 4 "Launch the vehicle in 4th gear" 5 "Launch the vehicle in 5th gear" 6 "Launch the vehicle in 6th gear" 7 "Launch the vehicle in 7th gear" 8 "Launch the vehicle in 8th gear" 9 "Launch the vehicle in Reverse 1" 10 "Launch the vehicle in Reverse 2" 11 "Launch the vehicle in Reverse 3" 12 "Launch the vehicle in Reverse 4" 13 "Reserved" 14 "Error" 15 "Not Available" ;
VAL_ 2348941054 TrnsShftSlectorDisplayModeSwitch 0 "Off" 1 "On" 2 "Error" 3 "Not available" ;
VAL_ 2348941054 TransMode5 0 "Disable" 1 "Enable" 2 "Reserved" 3 "Take no action" ;
VAL_ 2348941054 TransMode6 0 "Disable" 1 "Enable" 2 "Reserved" 3 "Take no action" ;
VAL_ 2348941054 TransMode7 0 "Disable" 1 "Enable" 2 "Reserved" 3 "Take no action" ;
VAL_ 2348941054 TransMode8 0 "Disable" 1 "Enable" 2 "Reserved" 3 "Take no action" ;
VAL_ 2566839806 EngTurboOilLevelSwitch 0 "No oil present at turbocharger" 1 "Oil present at turbocharger" 2 "Error" 3 "Not available" ;
VAL_ 2566841344 EngIdleShutdownHasShutdownEng 0 "No" 1 "Yes" 2 "Error" 3 "Not available" ;
VAL_ 2566841344 EngIdleShutdownDriverAlertMode 0 "Inactive" 1 "Active" 2 "Error" 3 "Not available" ;
VAL_ 2566841344 EngIdleShutdownTimerOverride 0 "Inactive" 1 "Active" 2 "Error" 3 "Not available" ;
VAL_ 2566841344 EngIdleShutdownTimerState 0 "Inactive" 1 "Active" 2 "Error" 3 "Not available" ;
VAL_ 2566841344 EngIdleShutdownTimerFunction 0 "Disabled in calibration" 1 "Enabled in calibration" 2 "Error" 3 "Not available" ;
VAL_ 2566841344 A_CHighPressFanSwitch 0 "Pressure normal" 1 "Pressure high fan may be engaged" 2 "Error" 3 "Not available" ;
VAL_ 2566841344 RefrigerantLowPressSwitch 0 "Pressure normal" 1 "Pressure too low compressor clutch may be disengaged" 2 "Error" 3 "Not available" ;
VAL_ 2566841344 RefrigerantHighPressSwitch 0 "Pressure normal" 1 "Pressure too high compressor clutch may be disengaged" 2 "Error" 3 "Not available" ;
VAL_ 2566841344 EngWaitToStartLamp 0 "Off" 1 "On" 2 "Error" 3 "Not available" ;
VAL_ 2566841344 EngPrtectionSystemHasShutdownEng 0 "No" 1 "Yes" 2 "Error" 3 "Not available" ;
VAL_ 2566841344 EngPrtctnSystmApprachingShutdown 0 "Not approaching" 1 "Approaching" 2 "Error" 3 "Not available" ;
VAL_ 2566841344 EngProtectionSystemTimerOverride 0 "Inactive" 1 "Active" 2 "Error" 3 "Not available" ;
VAL_ 2566841344 EngProtectionSystemTimerState 0 "Inactive" 1 "Active" 2 "Error" 3 "Not available" ;
VAL_ 2566841344 EngProtectionSystemConfig 0 "Disabled in calibration" 1 "Enabled in calibration" 2 "Error" 3 "Not available" ;
VAL_ 2566841344 EngAlarmAcknowledge 0 "Engine Alarm Acknowledge Not Active" 1 "Engine Alarm Acknowledge Active" 2 "Error" 3 "Not Available" ;
VAL_ 2566841344 EngAlarmOutputCmdStatus 0 "Engine Alarm Output Command Not Active" 1 "Engine Alarm Output Command Active" 2 "Reserved" 3 "Not Available" ;
VAL_ 2566841344 EngAirShutoffCmdStatus 1 "Air Shutoff Enabled attempting to shutoff engine air supply" 2 "Reserved" 3 "Not Available" 0 "Air Shutoff Disabled not attempting to shutoff engine air supply" ;
VAL_ 2566841344 EngOverspeedTest 0 "Engine Overspeed Test Not Active" 1 "Engine Overspeed Test Active" 2 "Reserved" 3 "Not Available" ;
VAL_ 2566841344 EngAirShutoffStatus 0 "Air flow allowed to engine" 1 "Air flow restricted" 2 "Error" 3 "Not Available" ;
VAL_ 2566841344 PTOShutdownHasShutdownEng 0 "No" 1 "Yes" 2 "Error" 3 "Not available" ;
VAL_ 2633895166 Function 43 "Transmission Display" 44 "Exhaust Emission Control" 45 "Vehicle Dynamic Stability Control" 46 "Oil Sensor Unit" 47 "Information System Controller" 48 "Ramp Control" 49 "Clutch/Converter Control" 50 "Auxiliary Heater" 51 "Forward-Looking Collision Warning System" 52 "Chassis Controller" 53 "Alternator/Charging System" 57 "Communications Unit,0" 57 "Communications Unit,0" 57 "Communications Unit,0" 57 "Steering Column Unit" 58 "Fan Drive Control" 59 "Starter" 60 "Cab Display" 61 "File Server/Printer" 62 "On-Board Diagnostic Unit" 63 "Engine Valve Controller" 64 "Endurance Braking" 65 "Gas Flow Measurement" 66 "I/O Controller" 67 "Electrical System Controller" 68 "Aftertreatment system gas measurement" 69 "Engine Emission Aftertreatement System" 70 "Auxiliary Regeneration Device" 71 "Transfer Case Control" 72 "Coolant Valve Controller" 73 "Rollover Detection Control" 74 "Lubrication System" 75 "Supplemental Fan" 76 "Reserved" 77 "Reserved" 78 "Reserved" 79 "Reserved" 80 "Reserved" 81 "Reserved" 82 "Reserved" 83 "Reserved" 84 "Reserved" 85 "Reserved" 86 "Reserved" 87 "Reserved" 88 "Reserved" 89 "Reserved" 90 "Reserved" 91 "Reserved" 92 "Reserved" 93 "Reserved" 94 "Reserved" 95 "Reserved" 96 "Reserved" 97 "Reserved" 98 "Reserved" 99 "Reserved" 100 "Reserved" 0 "Engine" 1 "Auxiliary Power Unit (APU)" 2 "Electric Propulsion Control" 3 "Transmission" 4 "Battery Pack Monitor" 5 "Shift Control/Console" 6 "Power TakeOff - (Main or Rear)" 7 "Axle - Steering" 8 "Axle - Drive" 9 "Brakes - System Controller" 10 "Brakes - Steer Axle" 11 "Brakes - Drive Axle" 12 "Retarder - Engine" 13 "Retarder - Driveline" 14 "Cruise Control" 15 "Fuel System" 16 "Steering Controller" 17 "Suspension - Steer Axle" 18 "Suspension - Drive Axle" 19 "Instrument Cluster" 20 "Trip Recorder" 21 "Cab Climate Control" 22 "Aerodynamic Control" 23 "Vehicle Navigation" 24 "Vehicle Security" 25 "Network Interconnect ECU" 26 "Body Controller" 27 "Power TakeOff (Secondary or Front)" 28 "Off Vehicle Gateway" 29 "Virtual Terminal (in cab)" 30 "Management Computer" 31 "Propulsion Battery Charger" 32 "Headway Controller" 33 "System Monitor" 34 "Hydraulic Pump Controller" 35 "Suspension - System Controller" 36 "Pneumatic - System Controller" 37 "Cab Controller" 38 "Tire Pressure Control" 39 "Ignition Control Module" 40 "Seat Control" 41 "Lighting - Operator Controls" 42 "Water Pump Control" 101 "Reserved" 102 "Reserved" 103 "Reserved" 104 "Reserved" 105 "Reserved" 106 "Reserved" 107 "Reserved" 108 "Reserved" 109 "Reserved" 110 "Reserved" 111 "Reserved" 112 "Reserved" 113 "Reserved" 114 "Reserved" 115 "Reserved" 116 "Reserved" 117 "Reserved" 118 "Reserved" 119 "Reserved" 120 "Reserved" 121 "Reserved" 122 "Reserved" 123 "Reserved" 124 "Reserved" 125 "Reserved" 126 "Reserved" 127 "Reserved" ;
VAL_ 2633895166 VehicleSystem 127 "Not Available" 0 "Non-specific System" ;
VAL_ 2633895166 IndustryGroup 0 "Global" 1 "On-Highway" 2 "Agricultural and Forestry" 3 "Construction" 4 "Marine" 5 "IndustrialProcessCtrlStationary" 7 "Reserved for SAE" 6 "Reserved for SAE" ;
VAL_ 2633895166 VehicleSystem1 0 "Non-specific System" 127 "Not Available" 1 "Tractor" 2 "Trailer" ;
VAL_ 2633895166 VehicleSystem2 0 "Non-specific System" 127 "Not Available" 1 "Tractor" 2 "Tillage" 3 "Secondary Tillage" 4 "Planters/Seeders" 5 "Fertilizers" 6 "Sprayers" 7 "Harvesters" 8 "Root Harvesters" 9 "Forage" 10 "Irrigation" 11 "Transport/Trailer" 12 "Farm Yard Operations" 13 "Powered Auxiliary Device" 14 "Special Crops" 15 "Earth Work" 16 "Skidder" ;
VAL_ 2633895166 VehicleSystem3 0 "Non-specific System" 127 "Not Available" 1 "Skid Steer Loader" 2 "Articulated Dump Truck" 3 "Backhoe" 4 "Crawler" 5 "Excavator" 6 "Forklift" 7 "Four Wheel Drive Loader" 8 "Grader" ;
VAL_ 2633895166 VehicleSystem4 0 "Non-specific System" 127 "Not Available" 10 "System Tools" 20 "Safety Systems" 25 "Gateway" 30 "Power Mgmt and lighting systems" 40 "Steering Systems" 50 "Propulsion Systems" 60 "Navigation Systems" 70 "Communications Systems" 80 "Instrumentation/General Systems" 90 "Environmental (HVAC) Systems" 100 "Deck/Cargo/Fishing equip. sys" ;
VAL_ 2633895166 VehicleSystem5 0 "Ind. Process Control Stationary" 127 "Not Available" ;
VAL_ 2565406462 ControlByte 0 "MFDB_Request" 1 "MFDB_Response" 2 "MFDB_Add" 3 "MFDB_Delete" 4 "MFDB_Clear" 5 "MFDB_SetMode" 6 "MFDB_CreateEntry" ;
